VERSION ""

NS_ :

BS_:

BU_: CHUD_LS VKM_LS RCRM_LS MSM_RR_LS MSM_LR_LS CGM_LS BSM_LS VPM_LS ISRVM_LS DCAC_LS TouchPad_LS RSC_LS LVMPC_LS EOCM2B_K1_LS EOCM2A_K1_LS LCM_LS TIM_B_LS V2V_LS TCP_LS CSM_LS EOCM2B_K2_LS EOCM2A_K2_LS TIM_A_LS LVMNav_LS HFP_LS EDI_LS ARB_LS RSE_LS Dummy_LS VIS2_LS ICS_LS FCM_LS EOCM_F_LS VICM_LS AGC_LS MSM_P_LS OTIM_LS HVSM_R_LS HVSM_F_LS DVB_T_LS SBZA_R_LS PSD_R_LS PSD_L_LS UHP_Low UPA_LS STC_LS SBZA_L_LS PTM_LS ONSTAR_LS APA_LS TestTool_LS PHS_LS PDIM_LS CHM_LS RSA_LS AMP_LS HUD_LS MSM_LS HBSM_LS SCL_LS ECC_LS RadioHead_LS PEPS_LS IPC_LS AOS_LS SDM_LS TIM_LS BCM_LS

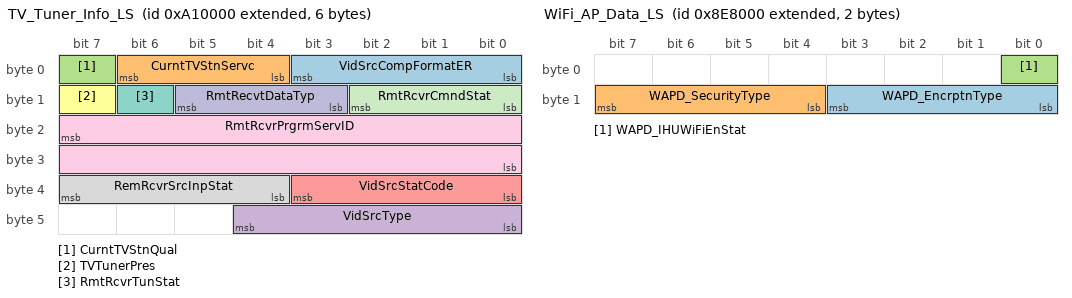
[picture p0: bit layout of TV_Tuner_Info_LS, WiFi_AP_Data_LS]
BO_ 2158034944 TV_Tuner_Info_LS: 6 DVB_T_LS
 SG_ VidSrcCompFormatER : 3|4@0+ (1,0) [0|15] ""  CGM_LS,RadioHead_LS
 SG_ CurntTVStnServc : 6|3@0+ (1,0) [0|7] ""  CGM_LS,RadioHead_LS
 SG_ CurntTVStnQual : 7|1@0+ (1,0) [0|1] ""  CGM_LS,RadioHead_LS
 SG_ VidSrcType : 44|5@0+ (1,0) [0|31] ""  CGM_LS,RadioHead_LS
 SG_ VidSrcStatCode : 35|4@0+ (1,0) [0|15] ""  CGM_LS,RadioHead_LS
 SG_ TVTunerPres : 15|1@0+ (1,0) [0|1] ""  CGM_LS,RadioHead_LS
 SG_ RmtRcvrTunStat : 14|1@0+ (1,0) [0|1] ""  CGM_LS,RadioHead_LS
 SG_ RemRcvrSrcInpStat : 39|4@0+ (1,0) [0|15] ""  CGM_LS,RadioHead_LS
 SG_ RmtRcvrPrgrmServID : 23|16@0+ (1,0) [0|65535] ""  CGM_LS,RadioHead_LS
 SG_ RmtRecvtDataTyp : 13|3@0+ (1,0) [0|7] ""  CGM_LS,RadioHead_LS
 SG_ RmtRcvrCmndStat : 10|3@0+ (1,0) [0|7] ""  CGM_LS,RadioHead_LS

BO_ 2158018560 TV_Station_Name_LS: 8 DVB_T_LS
 SG_ TVStatNmeChar1_8 : 7|64@0+ (1,0) [0|0] ""  CGM_LS,RadioHead_LS

BO_ 2156838912 WiFi_Station_LS: 7 RadioHead_LS
 SG_ WSR_WiFiStnMACAddr : 15|48@0+ (1,0) [0|281474976710655] ""  CGM_LS,ONSTAR_LS
 SG_ WSR_WiFiAssnStat : 3|4@0+ (1,0) [0|15] ""  CGM_LS,ONSTAR_LS

BO_ 2156822528 WiFi_AP_Data_LS: 2 ONSTAR_LS
 SG_ WAPD_EncrptnType : 11|4@0+ (1,0) [0|15] ""  CGM_LS,RadioHead_LS
 SG_ WAPD_SecurityType : 15|4@0+ (1,0) [0|15] ""  CGM_LS,RadioHead_LS
 SG_ WAPD_IHUWiFiEnStat : 0|1@0+ (1,0) [0|1] ""  CGM_LS,RadioHead_LS

BO_ 2151948288 Driver_Drow_Det_Cst_Rqst_LS: 1 RadioHead_LS
 SG_ RunBrdOpMdCstStReq : 7|3@0+ (1,0) [0|7] ""  ARB_LS
 SG_ DrvDrowDetCstStRq : 2|3@0+ (1,0) [0|7] ""  VIS2_LS,FCM_LS

BO_ 2158002176 XM_Radio_Service_LS: 1 RadioHead_LS
 SG_ SrvcPrvdr : 5|3@0+ (1,0) [0|7] ""  CGM_LS,ONSTAR_LS
 SG_ CurntStnServc : 2|3@0+ (1,0) [0|7] ""  CGM_LS,ONSTAR_LS

BO_ 2149728256 Charging_Sys_Trans_Shift_Lock_LS: 5 VICM_LS
 SG_ PrtyChrgStPnt : 38|7@0+ (1,0) [0|127] ""  BCM_LS,CGM_LS,IPC_LS,CSM_LS,RadioHead_LS
 SG_ PrtyChrgActIO : 3|1@0+ (1,0) [0|1] ""  BCM_LS,CSM_LS,CGM_LS,IPC_LS
 SG_ PrtyChrgAct : 4|1@0+ (1,0) [0|1] ""  BCM_LS,CGM_LS,CSM_LS,RadioHead_LS
 SG_ EngAstHtPlgInCsStAvl : 31|1@0+ (1,0) [0|1] ""  CGM_LS,CSM_LS,RadioHead_LS
 SG_ EngAstHtPlgInCsCrStVl : 30|3@0+ (1,0) [0|7] ""  CGM_LS,CSM_LS,RadioHead_LS
 SG_ EngAstHtCsStAvl : 27|1@0+ (1,0) [0|1] ""  CGM_LS,CSM_LS,RadioHead_LS
 SG_ EngAstHtCsCrStVal : 26|3@0+ (1,0) [0|7] ""  ECC_LS,CGM_LS,CSM_LS,RadioHead_LS
 SG_ HghVltgPropState : 7|3@0+ (1,0) [0|7] ""  CSM_LS,CGM_LS,RadioHead_LS,IPC_LS
 SG_ HVChrgPwrLvl : 22|3@0+ (1,0) [0|7] ""  BCM_LS,CGM_LS,CSM_LS,RadioHead_LS,IPC_LS
 SG_ ChrgPrtDrStat : 2|2@0+ (1,0) [0|3] ""  TCP_LS,CGM_LS,ONSTAR_LS,IPC_LS
 SG_ ChgCdTfAlCzStAvbl : 11|1@0+ (1,0) [0|1] ""  CGM_LS,CSM_LS,RadioHead_LS
 SG_ ChgCdTfAlCzCrStVal : 10|3@0+ (1,0) [0|7] ""  CGM_LS,CSM_LS,RadioHead_LS
 SG_ ChrgSysTrnsShftLckRq : 0|1@0+ (1,0) [0|1] ""  CSM_LS,CGM_LS,RadioHead_LS,BCM_LS
 SG_ ChgPwLsAlCzStAvbl : 15|1@0+ (1,0) [0|1] ""  CGM_LS,CSM_LS,RadioHead_LS
 SG_ ChgPwLsAlCzCrStVal : 14|3@0+ (1,0) [0|7] ""  CGM_LS,CSM_LS,RadioHead_LS
 SG_ ChgSysAudInCsStAvl : 19|1@0+ (1,0) [0|1] ""  CGM_LS,CSM_LS,RadioHead_LS
 SG_ ChgSyAudInCsCrStVa : 18|3@0+ (1,0) [0|7] ""  CGM_LS,CSM_LS,RadioHead_LS

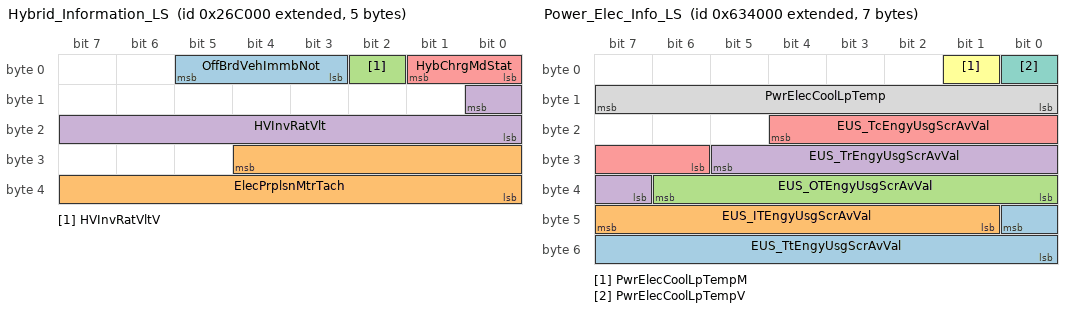
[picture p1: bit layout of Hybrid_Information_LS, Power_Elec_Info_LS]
BO_ 2150023168 Hybrid_Information_LS: 5 VICM_LS
 SG_ OffBrdVehImmbNot : 5|3@0+ (1,0) [0|7] ""  CGM_LS,TCP_LS,ONSTAR_LS
 SG_ ElecPrplsnMtrTach : 28|13@0+ (1,0) [0|8191] "rpm"  CSM_LS,RadioHead_LS,CGM_LS,IPC_LS
 SG_ HVInvRatVltV : 2|1@0+ (1,0) [0|1] ""  CSM_LS,ECC_LS,CGM_LS,RadioHead_LS
 SG_ HVInvRatVlt : 8|9@0+ (1,0) [0|511] "volts"  CSM_LS,ECC_LS,CGM_LS,RadioHead_LS
 SG_ HybChrgMdStat : 1|2@0+ (1,0) [0|3] ""  CSM_LS,ECC_LS,CGM_LS,RadioHead_LS,IPC_LS

BO_ 2153988096 Power_Elec_Info_LS: 7 VICM_LS
 SG_ EUS_TtEngyUsgScrAvVal : 40|9@0- (0.1,0) [-20|20] ""  CGM_LS,CSM_LS,RadioHead_LS
 SG_ EUS_ITEngyUsgScrAvVal : 47|7@0- (0.1,0) [-5|5] ""  CGM_LS,CSM_LS,RadioHead_LS
 SG_ EUS_OTEngyUsgScrAvVal : 38|7@0- (0.1,0) [-5|5] ""  CGM_LS,CSM_LS,RadioHead_LS
 SG_ EUS_TrEngyUsgScrAvVal : 29|7@0- (0.1,0) [-5|5] ""  CGM_LS,CSM_LS,RadioHead_LS
 SG_ EUS_TcEngyUsgScrAvVal : 20|7@0- (0.1,0) [-5|5] ""  CGM_LS,CSM_LS,RadioHead_LS
 SG_ PwrElecCoolLpTempM : 1|1@0+ (1,0) [0|1] ""  CGM_LS,ECC_LS
 SG_ PwrElecCoolLpTempV : 0|1@0+ (1,0) [0|1] ""  CGM_LS,ECC_LS
 SG_ PwrElecCoolLpTemp : 15|8@0+ (1,-40) [-40|215] "deg C"  CGM_LS,ECC_LS

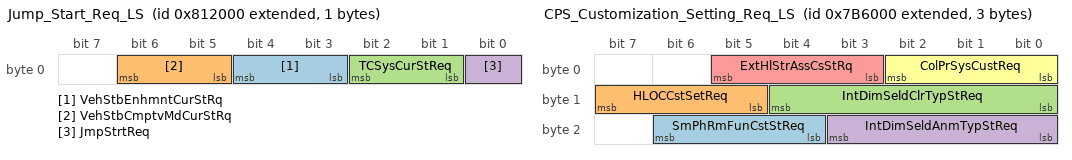
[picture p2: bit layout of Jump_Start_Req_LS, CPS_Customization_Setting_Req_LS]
BO_ 2155945984 Jump_Start_Req_LS: 1 IPC_LS
 SG_ VehStbEnhmntCurStRq : 4|2@0+ (1,0) [0|3] ""  BCM_LS
 SG_ VehStbCmptvMdCurStRq : 6|2@0+ (1,0) [0|3] ""  BCM_LS
 SG_ TCSysCurStReq : 2|2@0+ (1,0) [0|3] ""  BCM_LS
 SG_ JmpStrtReq : 0|1@0+ (1,0) [0|1] ""  BCM_LS

BO_ 1516 UUDT_Resp_From_VICM_LS: 8 VICM_LS
 SG_ DgnInf_LS5EC : 7|64@0+ (1,0) [0|1.84467440737096E+019] ""  CSM_LS,CGM_LS,TCP_LS,ONSTAR_LS,TestTool_LS

BO_ 2155585536 MSB_Customization_Setting_Req_LS: 1 RadioHead_LS
 SG_ StBltTgtCSRq : 2|3@0+ (1,0) [0|7] ""  BCM_LS

BO_ 2155569152 CPS_Customization_Setting_Req_LS: 3 RadioHead_LS
 SG_ SmPhRmFunCstStReq : 22|3@0+ (1,0) [0|7] ""  BCM_LS
 SG_ HLOCCstSetReq : 15|3@0+ (1,0) [0|7] ""  LCM_LS,PTM_LS
 SG_ IntDimSeldClrTypStReq : 12|5@0+ (1,0) [0|31] ""  BCM_LS
 SG_ IntDimSeldAnmTypStReq : 19|4@0+ (1,0) [0|15] ""  BCM_LS
 SG_ ExtHlStrAssCsStRq : 5|3@0+ (1,0) [0|7] ""  BCM_LS
 SG_ ColPrSysCustReq : 2|3@0+ (1,0) [0|7] ""  BCM_LS

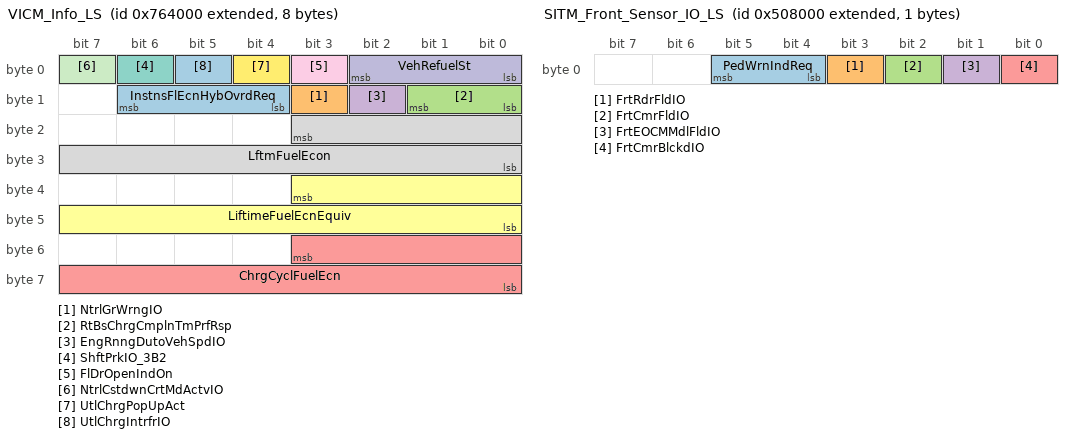
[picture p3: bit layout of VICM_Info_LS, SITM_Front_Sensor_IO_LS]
BO_ 2155233280 VICM_Info_LS: 8 VICM_LS
 SG_ InstnsFlEcnHybOvrdReq : 14|3@0+ (1,0) [0|7] ""  CGM_LS,IPC_LS
 SG_ NtrlGrWrngIO : 11|1@0+ (1,0) [0|1] ""  CGM_LS,IPC_LS
 SG_ RtBsChrgCmplnTmPrfRsp : 9|2@0+ (1,0) [0|3] ""  CGM_LS,CSM_LS,RadioHead_LS
 SG_ EngRnngDutoVehSpdIO : 10|1@0+ (1,0) [0|1] ""  IPC_LS,CGM_LS
 SG_ ChrgCyclFuelEcn : 51|12@0+ (0.1,0) [0|409.5] "km/l"  CGM_LS,CSM_LS,RadioHead_LS
 SG_ LiftimeFuelEcnEquiv : 35|12@0+ (0.1,0) [0|409.5] "km/l"  CGM_LS,CSM_LS,RadioHead_LS
 SG_ ShftPrkIO_3B2 : 6|1@0+ (1,0) [0|1] ""  CGM_LS,IPC_LS
 SG_ LftmFuelEcon : 19|12@0+ (0.1,0) [0|409.5] "kilometers/liter"  CGM_LS,CSM_LS,RadioHead_LS
 SG_ FlDrOpenIndOn : 3|1@0+ (1,0) [0|1] ""  CSM_LS,CGM_LS,RadioHead_LS,IPC_LS
 SG_ VehRefuelSt : 2|3@0+ (1,0) [0|7] ""  CSM_LS,CGM_LS,RadioHead_LS,IPC_LS
 SG_ NtrlCstdwnCrtMdActvIO : 7|1@0+ (1,0) [0|1] ""  CGM_LS,IPC_LS
 SG_ UtlChrgPopUpAct : 4|1@0+ (1,0) [0|1] ""  CGM_LS,CSM_LS,RadioHead_LS
 SG_ UtlChrgIntrfrIO : 5|1@0+ (1,0) [0|1] ""  CGM_LS,CSM_LS,RadioHead_LS,IPC_LS

BO_ 2152759296 SITM_Front_Sensor_IO_LS: 1 EOCM_F_LS
 SG_ PedWrnIndReq : 5|2@0+ (1,0) [0|3] ""  CSM_LS,RadioHead_LS,CGM_LS,IPC_LS
 SG_ FrtRdrFldIO : 3|1@0+ (1,0) [0|1] ""  CSM_LS,CGM_LS,RadioHead_LS,IPC_LS
 SG_ FrtCmrFldIO : 2|1@0+ (1,0) [0|1] ""  CSM_LS,CGM_LS,RadioHead_LS,IPC_LS
 SG_ FrtEOCMMdlFldIO : 1|1@0+ (1,0) [0|1] ""  CSM_LS,CGM_LS,RadioHead_LS,IPC_LS
 SG_ FrtCmrBlckdIO : 0|1@0+ (1,0) [0|1] ""  CSM_LS,CGM_LS,RadioHead_LS,IPC_LS

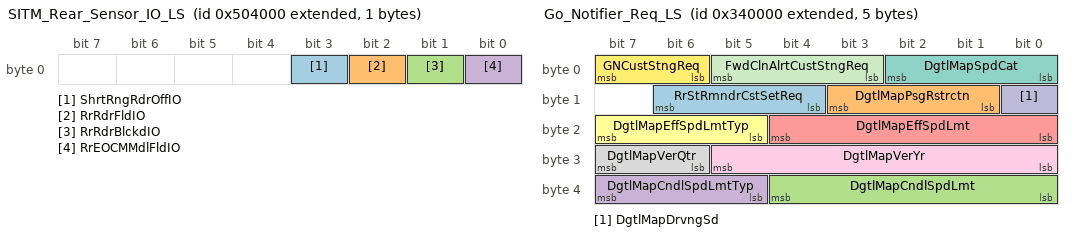
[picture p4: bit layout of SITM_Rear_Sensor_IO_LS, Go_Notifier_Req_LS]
BO_ 2152742912 SITM_Rear_Sensor_IO_LS: 1 EOCM_F_LS
 SG_ ShrtRngRdrOffIO : 3|1@0+ (1,0) [0|1] ""  CSM_LS,CGM_LS,RadioHead_LS,IPC_LS
 SG_ RrRdrFldIO : 2|1@0+ (1,0) [0|1] ""  CSM_LS,CGM_LS,RadioHead_LS,IPC_LS
 SG_ RrRdrBlckdIO : 1|1@0+ (1,0) [0|1] ""  CSM_LS,CGM_LS,RadioHead_LS,IPC_LS
 SG_ RrEOCMMdlFldIO : 0|1@0+ (1,0) [0|1] ""  CSM_LS,CGM_LS,RadioHead_LS,IPC_LS

BO_ 2150891520 Go_Notifier_Req_LS: 5 RadioHead_LS
 SG_ RrStRmndrCstSetReq : 14|3@0+ (1,0) [0|7] ""  BCM_LS
 SG_ DgtlMapPsgRstrctn : 11|3@0+ (1,0) [0|7] ""  VIS2_LS,FCM_LS
 SG_ DgtlMapCndlSpdLmt : 36|5@0+ (1,0) [0|31] ""  VIS2_LS,FCM_LS
 SG_ DgtlMapCndlSpdLmtTyp : 39|3@0+ (1,0) [0|7] ""  VIS2_LS,FCM_LS
 SG_ DgtlMapEffSpdLmt : 20|5@0+ (1,0) [0|31] ""  VIS2_LS,FCM_LS
 SG_ DgtlMapEffSpdLmtTyp : 23|3@0+ (1,0) [0|7] ""  VIS2_LS,FCM_LS
 SG_ DgtlMapSpdCat : 2|3@0+ (1,0) [0|7] ""  VIS2_LS,FCM_LS
 SG_ DgtlMapVerQtr : 31|2@0+ (1,0) [0|3] ""  VIS2_LS,FCM_LS
 SG_ DgtlMapVerYr : 29|6@0+ (1,0) [0|63] ""  VIS2_LS,FCM_LS
 SG_ DgtlMapDrvngSd : 8|1@0+ (1,0) [0|1] ""  VIS2_LS,FCM_LS
 SG_ FwdClnAlrtCustStngReq : 5|3@0+ (1,0) [0|7] ""  FCM_LS,BCM_LS
 SG_ GNCustStngReq : 7|2@0+ (1,0) [0|3] ""  BCM_LS

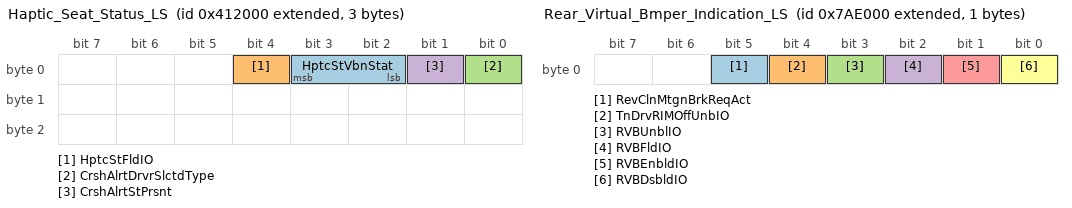
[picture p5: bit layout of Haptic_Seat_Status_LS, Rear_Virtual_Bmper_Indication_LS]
BO_ 2151751680 Haptic_Seat_Status_LS: 3 MSM_LS
 SG_ HptcStVbnStat : 3|2@0+ (1,0) [0|3] ""  V2V_LS,EOCM2A_K2_LS,EOCM2B_K2_LS,VPM_LS,CGM_LS,SBZA_R_LS,SBZA_L_LS,UPA_LS,APA_LS,VIS2_LS,FCM_LS,EOCM_F_LS,BCM_LS
 SG_ HptcStFldIO : 4|1@0+ (1,0) [0|1] ""  VPM_LS,EOCM2A_K2_LS,EOCM2B_K2_LS,V2V_LS,CGM_LS,VIS2_LS,IPC_LS,FCM_LS
 SG_ CrshAlrtDrvrSlctdType : 0|1@0+ (1,0) [0|1] ""  EOCM2A_K2_LS,EOCM2B_K2_LS,V2V_LS,VPM_LS,CGM_LS,VIS2_LS,UPA_LS,APA_LS,FCM_LS,SBZA_R_LS,SBZA_L_LS,BCM_LS,EOCM_F_LS
 SG_ CrshAlrtStPrsnt : 1|1@0+ (1,0) [0|1] ""  VPM_LS,EOCM2A_K2_LS,EOCM2B_K2_LS,V2V_LS,CGM_LS,VIS2_LS,FCM_LS,UPA_LS,APA_LS,BCM_LS,SBZA_R_LS,SBZA_L_LS,EOCM_F_LS

BO_ 2155536384 Rear_Virtual_Bmper_Indication_LS: 1 EOCM_F_LS
 SG_ RevClnMtgnBrkReqAct : 5|1@0+ (1,0) [0|1] ""  CGM_LS,BCM_LS
 SG_ TnDrvRIMOffUnbIO : 4|1@0+ (1,0) [0|1] ""  CGM_LS,IPC_LS
 SG_ RVBUnblIO : 3|1@0+ (1,0) [0|1] ""  CGM_LS,IPC_LS
 SG_ RVBFldIO : 2|1@0+ (1,0) [0|1] ""  CGM_LS,IPC_LS
 SG_ RVBEnbldIO : 1|1@0+ (1,0) [0|1] ""  CGM_LS,IPC_LS
 SG_ RVBDsbldIO : 0|1@0+ (1,0) [0|1] ""  CGM_LS,SBZA_R_LS,SBZA_L_LS,IPC_LS

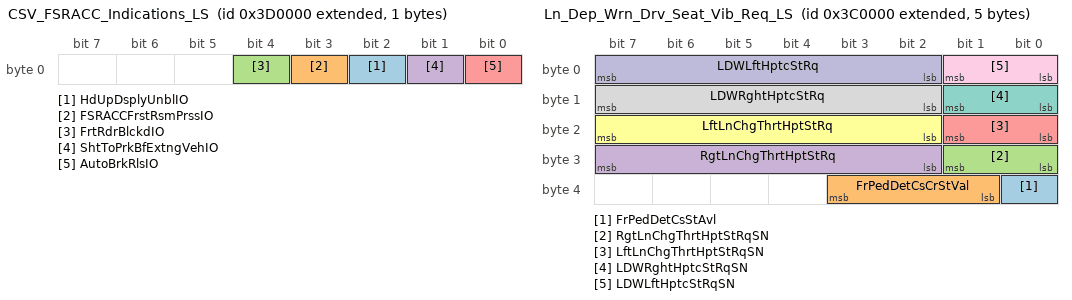
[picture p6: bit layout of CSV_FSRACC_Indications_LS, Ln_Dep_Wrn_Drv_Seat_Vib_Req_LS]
BO_ 2151481344 CSV_FSRACC_Indications_LS: 1 EOCM_F_LS
 SG_ HdUpDsplyUnblIO : 2|1@0+ (1,0) [0|1] ""  CGM_LS,IPC_LS
 SG_ FSRACCFrstRsmPrssIO : 3|1@0+ (1,0) [0|1] ""  CGM_LS,IPC_LS
 SG_ FrtRdrBlckdIO : 4|1@0+ (1,0) [0|1] ""  CSM_LS,CGM_LS,RadioHead_LS,IPC_LS
 SG_ ShtToPrkBfExtngVehIO : 1|1@0+ (1,0) [0|1] ""  CGM_LS,IPC_LS
 SG_ AutoBrkRlsIO : 0|1@0+ (1,0) [0|1] ""  CGM_LS,IPC_LS

BO_ 2151432192 ACC_Drv_Seat_Vib_Req_IO_LS: 1 BCM_LS
 SG_ ACCHptcStVbnRqSeqN : 1|2@0+ (1,0) [0|3] ""  MSM_P_LS,MSM_LS
 SG_ ACCHptcStVbnReq : 7|6@0+ (1,0) [0|63] ""  MSM_P_LS,MSM_LS

BO_ 2151415808 Ln_Dep_Wrn_Drv_Seat_Vib_Req_LS: 5 EOCM_F_LS
 SG_ FrPedDetCsStAvl : 32|1@0+ (1,0) [0|1] ""  CGM_LS,CSM_LS,RadioHead_LS,MSM_P_LS,MSM_LS
 SG_ FrPedDetCsCrStVal : 35|3@0+ (1,0) [0|7] ""  CGM_LS,CSM_LS,RadioHead_LS,MSM_P_LS,MSM_LS
 SG_ RgtLnChgThrtHptStRqSN : 25|2@0+ (1,0) [0|3] ""  CGM_LS,MSM_P_LS,MSM_LS
 SG_ RgtLnChgThrtHptStRq : 31|6@0+ (1,0) [0|63] "Pulse"  CGM_LS,MSM_P_LS,MSM_LS
 SG_ LftLnChgThrtHptStRqSN : 17|2@0+ (1,0) [0|3] ""  CGM_LS,MSM_P_LS,MSM_LS
 SG_ LftLnChgThrtHptStRq : 23|6@0+ (1,0) [0|63] "Pulse"  CGM_LS,MSM_P_LS,MSM_LS
 SG_ LDWRghtHptcStRqSN : 9|2@0+ (1,0) [0|3] ""  CGM_LS,MSM_P_LS,MSM_LS
 SG_ LDWRghtHptcStRq : 15|6@0+ (1,0) [0|63] ""  CGM_LS,BCM_LS,MSM_P_LS,MSM_LS
 SG_ LDWLftHptcStRqSN : 1|2@0+ (1,0) [0|3] ""  CGM_LS,MSM_P_LS,MSM_LS
 SG_ LDWLftHptcStRq : 7|6@0+ (1,0) [0|63] ""  CGM_LS,BCM_LS,MSM_P_LS,MSM_LS

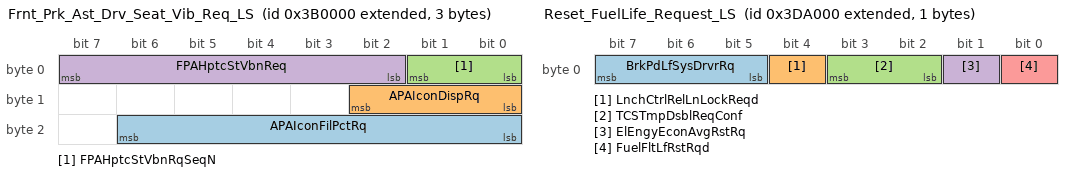
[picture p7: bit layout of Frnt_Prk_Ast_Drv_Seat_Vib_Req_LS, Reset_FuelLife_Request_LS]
BO_ 2151350272 Frnt_Prk_Ast_Drv_Seat_Vib_Req_LS: 3 APA_LS
 SG_ APAIconFilPctRq : 22|7@0+ (1,0) [0|127] ""  CGM_LS,VPM_LS,CSM_LS,RadioHead_LS
 SG_ APAIconDispRq : 10|3@0+ (1,0) [0|7] ""  CGM_LS,VPM_LS,CSM_LS,RadioHead_LS
 SG_ FPAHptcStVbnRqSeqN : 1|2@0+ (1,0) [0|3] ""  CGM_LS,MSM_P_LS,MSM_LS
 SG_ FPAHptcStVbnReq : 7|6@0+ (1,0) [0|63] ""  CGM_LS,MSM_P_LS,MSM_LS

BO_ 2151333888 Rear_Prk_Ast_Drv_Seat_Vib_Req_LS: 1 APA_LS
 SG_ RPAHptcStVbRqSeqN : 1|2@0+ (1,0) [0|3] ""  MSM_P_LS,MSM_LS
 SG_ RPAHptcStVbnReq : 7|6@0+ (1,0) [0|63] ""  MSM_P_LS,MSM_LS

BO_ 2151522304 Reset_FuelLife_Request_LS: 1 IPC_LS
 SG_ BrkPdLfSysDrvrRq : 7|3@0+ (1,0) [0|7] ""  BCM_LS
 SG_ LnchCtrlRelLnLockReqd : 4|1@0+ (1,0) [0|1] ""  BCM_LS
 SG_ TCSTmpDsblReqConf : 3|2@0+ (1,0) [0|3] ""  BCM_LS
 SG_ ElEngyEconAvgRstRq : 1|1@0+ (1,0) [0|1] ""  BSM_LS,VICM_LS
 SG_ FuelFltLfRstRqd : 0|1@0+ (1,0) [0|1] ""  BCM_LS

BO_ 2150629376 CV_System_Failure_LS: 1 Dummy_LS
 SG_ CVSysFlrIO : 0|1@0+ (1,0) [0|1] ""  CSM_LS,CGM_LS,IPC_LS

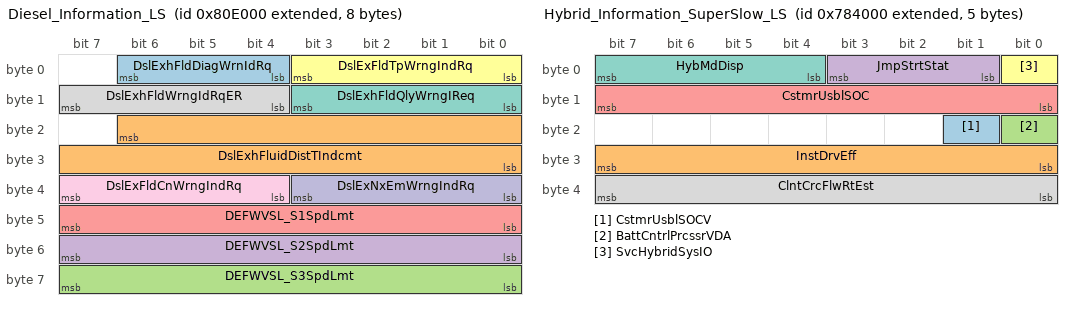
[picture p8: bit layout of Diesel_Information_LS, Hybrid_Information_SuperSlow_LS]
BO_ 2155929600 Diesel_Information_LS: 8 BCM_LS
 SG_ DslExhFldDiagWrnIdRq : 6|3@0+ (1,0) [0|7] ""  CSM_LS,CGM_LS,IPC_LS
 SG_ DslExhFluidDistTIndcmt : 22|15@0+ (2,0) [0|65534] "km"  CGM_LS,IPC_LS
 SG_ DEFWVSL_S3SpdLmt : 63|8@0+ (1,0) [0|255] "km / h"  CGM_LS,IPC_LS
 SG_ DEFWVSL_S2SpdLmt : 55|8@0+ (1,0) [0|255] "km / h"  CGM_LS,IPC_LS
 SG_ DEFWVSL_S1SpdLmt : 47|8@0+ (1,0) [0|255] "km / h"  CGM_LS,IPC_LS
 SG_ DslExFldTpWrngIndRq : 3|4@0+ (1,0) [0|15] ""  CGM_LS,IPC_LS
 SG_ DslExhFldQlyWrngIReq : 11|4@0+ (1,0) [0|15] ""  CGM_LS,IPC_LS
 SG_ DslExhFldWrngIdRqER : 15|4@0+ (1,0) [0|15] ""  CGM_LS,IPC_LS
 SG_ DslExFldCnWrngIndRq : 39|4@0+ (1,0) [0|15] ""  CGM_LS,IPC_LS
 SG_ DslExNxEmWrngIndRq : 35|4@0+ (1,0) [0|15] ""  CGM_LS,IPC_LS

BO_ 2154741760 RSA_Status_LS: 1 RSA_LS
 SG_ RSAPrsnt : 0|1@0+ (1,0) [0|1] ""  CGM_LS,CSM_LS,RadioHead_LS

BO_ 2154807296 Lighting_Customization_Info_3_LS: 4 BCM_LS
 SG_ ESCMHiEleclLdReqAct : 12|1@0+ (1,0) [0|1] ""  ECC_LS,CGM_LS
 SG_ TnDrvStBltShftIntrlkCsStAvl : 19|1@0+ (1,0) [0|1] ""  CSM_LS,CGM_LS
 SG_ TnDrvStBltShftIntrlkCrStVal : 22|3@0+ (1,0) [0|7] ""  CSM_LS,CGM_LS
 SG_ StBltShftIntrlkCsStAvl : 18|1@0+ (1,0) [0|1] ""  CSM_LS,CGM_LS
 SG_ StBltShftIntrlkCsCrStVal : 15|3@0+ (1,0) [0|7] ""  CSM_LS,CGM_LS
 SG_ EASSI_UnsdRsrvd2 : 24|1@0+ (1,0) [0|1] ""  CGM_LS,ECC_LS
 SG_ EASSI_StlDetd : 26|1@0+ (1,0) [0|1] ""  CGM_LS,ECC_LS
 SG_ EASSI_TrqDetd : 27|1@0+ (1,0) [0|1] ""  CGM_LS,ECC_LS
 SG_ EASSI_FuelReqOn : 28|1@0+ (1,0) [0|1] ""  CGM_LS,ECC_LS
 SG_ EASSI_StrtTyp : 31|3@0+ (1,0) [0|7] ""  CGM_LS,ECC_LS
 SG_ EASSI_StrtStpSt : 17|2@0+ (1,0) [0|3] ""  CGM_LS,ECC_LS
 SG_ EASSI_TorqDetdIndet : 25|1@0+ (1,0) [0|1] ""  CGM_LS,ECC_LS
 SG_ EngAutoStpNotProb : 11|1@0+ (1,0) [0|1] ""  CGM_LS,ECC_LS
 SG_ AFLMnu3CstStAvl : 10|1@0+ (1,0) [0|1] ""  CGM_LS,CSM_LS,RadioHead_LS
 SG_ AFLMnu2CstStAvl : 9|1@0+ (1,0) [0|1] ""  CGM_LS,CSM_LS,RadioHead_LS
 SG_ AFLGPSMnu2CstStAvl : 8|1@0+ (1,0) [0|1] ""  CGM_LS,CSM_LS,RadioHead_LS
 SG_ AFLGPSCstStAvl : 6|1@0+ (1,0) [0|1] ""  CGM_LS,CSM_LS,RadioHead_LS
 SG_ AFLGPSCstCrStVal : 2|3@0+ (1,0) [0|7] ""  CGM_LS,CSM_LS,RadioHead_LS
 SG_ AFLCstStAvl : 7|1@0+ (1,0) [0|1] ""  CGM_LS,CSM_LS,RadioHead_LS
 SG_ AFLCstCrStVal : 5|3@0+ (1,0) [0|7] ""  CGM_LS,CSM_LS,RadioHead_LS

BO_ 2151079936 PDIM_Status_LS: 1 PDIM_LS
 SG_ PDIMPrsnt : 0|1@0+ (1,0) [0|1] ""  CGM_LS,CSM_LS,RadioHead_LS

BO_ 2155364352 Hybrid_Information_SuperSlow_LS: 5 BCM_LS
 SG_ CstmrUsblSOCV : 17|1@0+ (1,0) [0|1] ""  BCM_LS,CGM_LS,IPC_LS,CSM_LS,RadioHead_LS
 SG_ InstDrvEff : 31|8@0- (0.78125,0) [-100|99.21875] "%"  CGM_LS,CSM_LS,RadioHead_LS,IPC_LS
 SG_ BattCntrlPrcssrVDA : 16|1@0+ (1,0) [0|1] ""  CSM_LS,CGM_LS,RadioHead_LS,IPC_LS
 SG_ JmpStrtStat : 3|3@0+ (1,0) [0|7] ""  CSM_LS,CGM_LS,RadioHead_LS,IPC_LS
 SG_ CstmrUsblSOC : 15|8@0+ (0.39216,0) [0|100.0008] "%"  BCM_LS,CGM_LS,CSM_LS,RadioHead_LS,IPC_LS
 SG_ SvcHybridSysIO : 0|1@0+ (1,0) [0|1] ""  CSM_LS,CGM_LS,RadioHead_LS,IPC_LS
 SG_ HybMdDisp : 7|4@0+ (1,0) [0|15] ""  CGM_LS,CSM_LS,RadioHead_LS,IPC_LS
 SG_ ClntCrcFlwRtEst : 39|8@0+ (0.392157,0) [0|100.000035] "%"  CSM_LS,CGM_LS,RadioHead_LS,ECC_LS

BO_ 2154979328 Front_Seat_Heat_Cool_Req_LS: 1 MSM_LS
 SG_ FrntStVoltBstModReq : 0|1@0+ (1,0) [0|1] ""  CGM_LS,BCM_LS

BO_ 2155282432 RearSeat_HeatVent_Cool_LS: 1 HVSM_R_LS
 SG_ RrStVoltBstModReq : 0|1@0+ (1,0) [0|1] ""  CGM_LS,BCM_LS

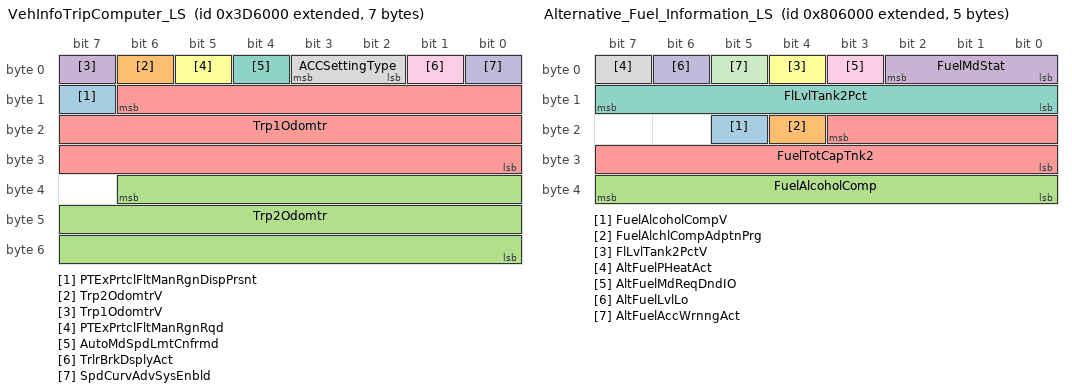
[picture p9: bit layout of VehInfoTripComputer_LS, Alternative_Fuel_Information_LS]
BO_ 2151505920 VehInfoTripComputer_LS: 7 IPC_LS
 SG_ PTExPrtclFltManRgnDispPrsnt : 15|1@0+ (1,0) [0|1] ""  BCM_LS
 SG_ Trp2OdomtrV : 6|1@0+ (1,0) [0|1] ""  RadioHead_LS
 SG_ Trp2Odomtr : 38|23@0+ (0.015625,0) [0|131071.984375] "km"  RadioHead_LS
 SG_ Trp1OdomtrV : 7|1@0+ (1,0) [0|1] ""  RadioHead_LS
 SG_ Trp1Odomtr : 14|23@0+ (0.015625,0) [0|131071.984375] "km"  RadioHead_LS
 SG_ PTExPrtclFltManRgnRqd : 5|1@0+ (1,0) [0|1] ""  BCM_LS
 SG_ AutoMdSpdLmtCnfrmd : 4|1@0+ (1,0) [0|1] ""  BCM_LS
 SG_ ACCSettingType : 3|2@0+ (1,0) [0|3] ""  VIS2_LS,ONSTAR_LS,BCM_LS
 SG_ TrlrBrkDsplyAct : 1|1@0+ (1,0) [0|1] ""  BCM_LS
 SG_ SpdCurvAdvSysEnbld : 0|1@0+ (1,0) [0|1] ""  ONSTAR_LS,CHUD_LS,HUD_LS

BO_ 2155896832 Alternative_Fuel_Information_LS: 5 BCM_LS
 SG_ FuelAlcoholCompV : 21|1@0+ (1,0) [0|1] ""  CGM_LS,RadioHead_LS,IPC_LS
 SG_ FuelAlchlCompAdptnPrg : 20|1@0+ (1,0) [0|1] ""  CGM_LS,RadioHead_LS,IPC_LS
 SG_ FuelAlcoholComp : 39|8@0+ (0.392157,0) [0|100.000035] "%"  CGM_LS,RadioHead_LS,IPC_LS
 SG_ FuelMdStat : 2|3@0+ (1,0) [0|7] ""  CGM_LS,RadioHead_LS,IPC_LS
 SG_ FuelTotCapTnk2 : 19|12@0+ (0.125,0) [0|511.875] "liters"  CGM_LS,RadioHead_LS,IPC_LS
 SG_ FlLvlTank2PctV : 4|1@0+ (1,0) [0|1] ""  CGM_LS,RadioHead_LS,IPC_LS
 SG_ FlLvlTank2Pct : 15|8@0+ (0.392157,0) [0|100.000035] "%"  CGM_LS,RadioHead_LS,IPC_LS
 SG_ AltFuelPHeatAct : 7|1@0+ (1,0) [0|1] ""  CGM_LS,RadioHead_LS,IPC_LS
 SG_ AltFuelMdReqDndIO : 3|1@0+ (1,0) [0|1] ""  CGM_LS,RadioHead_LS,IPC_LS
 SG_ AltFuelLvlLo : 6|1@0+ (1,0) [0|1] ""  CGM_LS,RadioHead_LS,IPC_LS
 SG_ AltFuelAccWrnngAct : 5|1@0+ (1,0) [0|1] ""  CGM_LS,RadioHead_LS,IPC_LS

BO_ 2155552768 Exterior_Lock_Switch_Req_LS: 1 PEPS_LS
 SG_ PsvEntCmftWndRq : 1|2@0+ (1,0) [0|3] ""  CGM_LS,BCM_LS

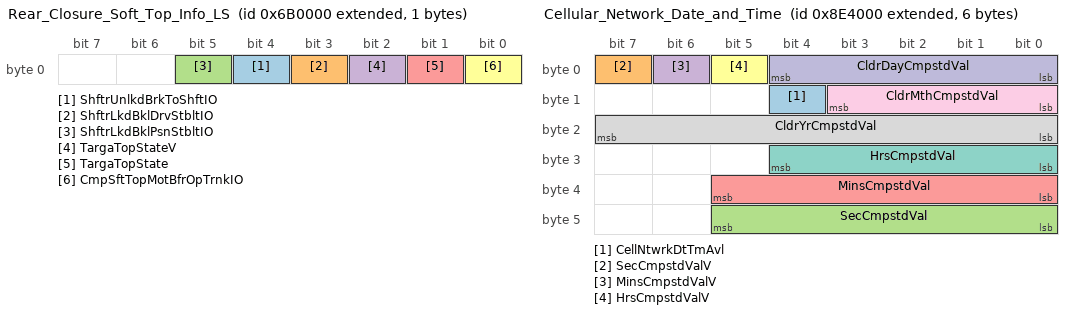
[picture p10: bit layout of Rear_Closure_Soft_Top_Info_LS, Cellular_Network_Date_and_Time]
BO_ 2154496000 Rear_Closure_Soft_Top_Info_LS: 1 BCM_LS
 SG_ ShftrUnlkdBrkToShftIO : 4|1@0+ (1,0) [0|1] ""  CGM_LS,IPC_LS
 SG_ ShftrLkdBklDrvStbltIO : 3|1@0+ (1,0) [0|1] ""  CGM_LS,IPC_LS
 SG_ ShftrLkdBklPsnStbltIO : 5|1@0+ (1,0) [0|1] ""  CGM_LS,IPC_LS
 SG_ TargaTopStateV : 2|1@0+ (1,0) [0|1] ""  AMP_LS,CGM_LS,ISRVM_LS,CSM_LS,RadioHead_LS
 SG_ TargaTopState : 1|1@0+ (1,0) [0|1] ""  AMP_LS,CGM_LS,ISRVM_LS,CSM_LS,RadioHead_LS
 SG_ CmpSftTopMotBfrOpTrnkIO : 0|1@0+ (1,0) [0|1] ""  CSM_LS,CGM_LS,IPC_LS

BO_ 2155208704 Power_Conv_Top_Info_LS: 3 STC_LS
 SG_ SftTpPlsDnWrngIndOn : 22|1@0+ (1,0) [0|1] ""  CGM_LS,IPC_LS
 SG_ SftTpPlsDnSrtdIndOn : 21|1@0+ (1,0) [0|1] ""  CGM_LS,IPC_LS
 SG_ VltSwAtvIndOn : 14|1@0+ (1,0) [0|1] ""  CGM_LS,RadioHead_LS,IPC_LS
 SG_ SftTpVltLwIO : 10|1@0+ (1,0) [0|1] ""  CGM_LS,RadioHead_LS,IPC_LS
 SG_ SftTpVehOvSpdIndOn : 9|1@0+ (1,0) [0|1] ""  CGM_LS,RadioHead_LS,IPC_LS
 SG_ SftTpTneuCvrIO : 8|1@0+ (1,0) [0|1] ""  CGM_LS,RadioHead_LS,IPC_LS
 SG_ SftTpTmpLwIO : 7|1@0+ (1,0) [0|1] ""  CGM_LS,RadioHead_LS,IPC_LS
 SG_ SftTpStrIO : 6|1@0+ (1,0) [0|1] ""  CGM_LS,RadioHead_LS,IPC_LS
 SG_ SftTpRmCrgCrrIO : 5|1@0+ (1,0) [0|1] ""  CGM_LS,RadioHead_LS,IPC_LS
 SG_ SftTpMnlLtchIndOn : 3|1@0+ (1,0) [0|1] ""  CGM_LS,RadioHead_LS,IPC_LS
 SG_ SftTpMchnOvhtIO : 4|1@0+ (1,0) [0|1] ""  CGM_LS,RadioHead_LS,IPC_LS
 SG_ SftTpLtcIO : 2|1@0+ (1,0) [0|1] ""  CGM_LS,RadioHead_LS,IPC_LS
 SG_ SftTpFlrIO : 1|1@0+ (1,0) [0|1] ""  CGM_LS,RadioHead_LS,IPC_LS
 SG_ SftTpAbvWrngSpdIndOn : 0|1@0+ (1,0) [0|1] ""  CGM_LS,RadioHead_LS,IPC_LS
 SG_ FldngTpSt : 18|3@0+ (1,0) [0|7] ""  AMP_LS,LCM_LS,CGM_LS,ISRVM_LS,IPC_LS,ECC_LS,RadioHead_LS,BCM_LS
 SG_ ClsTrnkLidIO : 12|1@0+ (1,0) [0|1] ""  V2V_LS,CGM_LS,RadioHead_LS,IPC_LS
 SG_ CkSoftTpIO : 11|1@0+ (1,0) [0|1] ""  CGM_LS,RadioHead_LS,IPC_LS
 SG_ SftTpTrnLmpsRqd : 15|1@0+ (1,0) [0|1] ""  CGM_LS,RadioHead_LS,BCM_LS
 SG_ FldngTpWndCmftRq : 20|2@0+ (1,0) [0|3] ""  CGM_LS,RadioHead_LS,BCM_LS
 SG_ FTUpdWndPsLmtEnbld : 13|1@0+ (1,0) [0|1] ""  CGM_LS,RadioHead_LS,BCM_LS

BO_ 2153390080 Manual_Liftgate_Control_LS: 1 BCM_LS
 SG_ RrClosOpenSwAct_2D1V : 3|1@0+ (1,0) [0|1] ""  CGM_LS,IPC_LS
 SG_ RrClosOpenSwAct_2D1 : 1|1@0+ (1,0) [0|1] ""  VKM_LS,CGM_LS,IPC_LS

BO_ 2155175936 CruiseControlGapSwitch_LS: 1 BCM_LS
 SG_ AdptCrsLKALDWSwAct : 2|1@0+ (1,0) [0|1] ""  CGM_LS,FCM_LS
 SG_ AdptCrsGapSwAct : 1|2@0+ (1,0) [0|3] ""  CGM_LS,FCM_LS

BO_ 2156806144 Cellular_Network_Date_and_Time: 6 ONSTAR_LS
 SG_ CellNtwrkDtTmAvl : 12|1@0+ (1,0) [0|1] ""  CSM_LS,RadioHead_LS
 SG_ SecCmpstdValV : 7|1@0+ (1,0) [0|1] ""  CSM_LS,RadioHead_LS
 SG_ SecCmpstdVal : 45|6@0+ (1,0) [0|63] "secs"  CSM_LS,RadioHead_LS
 SG_ MinsCmpstdValV : 6|1@0+ (1,0) [0|1] ""  CSM_LS,RadioHead_LS
 SG_ MinsCmpstdVal : 37|6@0+ (1,0) [0|63] "min"  CSM_LS,RadioHead_LS
 SG_ HrsCmpstdValV : 5|1@0+ (1,0) [0|1] ""  CSM_LS,RadioHead_LS
 SG_ HrsCmpstdVal : 28|5@0+ (1,0) [0|31] "h"  CSM_LS,RadioHead_LS
 SG_ CldrYrCmpstdVal : 23|8@0+ (1,2000) [2000|2255] "year"  CSM_LS,RadioHead_LS
 SG_ CldrMthCmpstdVal : 11|4@0+ (1,0) [0|15] ""  ECC_LS,CSM_LS,RadioHead_LS
 SG_ CldrDayCmpstdVal : 4|5@0+ (1,0) [0|31] "days"  ECC_LS,CSM_LS,RadioHead_LS

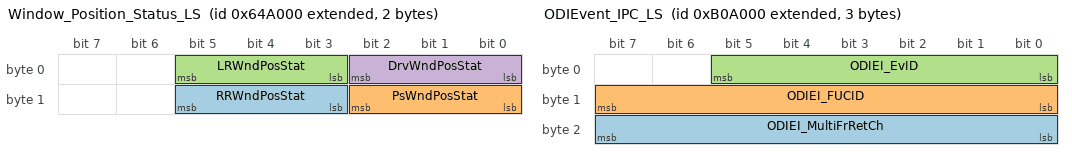
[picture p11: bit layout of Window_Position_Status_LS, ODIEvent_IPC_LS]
BO_ 2154078208 Window_Position_Status_LS: 2 BCM_LS
 SG_ RRWndPosStat : 13|3@0+ (1,0) [0|7] ""  CSM_LS,CGM_LS,RadioHead_LS,LCM_LS,PTM_LS,PSD_R_LS,PSD_L_LS,STC_LS
 SG_ PsWndPosStat : 10|3@0+ (1,0) [0|7] ""  CSM_LS,CGM_LS,RadioHead_LS,LCM_LS,PTM_LS,STC_LS
 SG_ LRWndPosStat : 5|3@0+ (1,0) [0|7] ""  CSM_LS,CGM_LS,RadioHead_LS,LCM_LS,PTM_LS,PSD_R_LS,PSD_L_LS,STC_LS
 SG_ DrvWndPosStat : 2|3@0+ (1,0) [0|7] ""  CSM_LS,CGM_LS,RadioHead_LS,LCM_LS,PTM_LS,STC_LS

BO_ 2159058944 ODIEvent_IPC_LS: 3 IPC_LS
 SG_ ODIEI_MultiFrRetCh : 23|8@0+ (1,0) [0|255] ""  CGM_LS,RadioHead_LS,CHUD_LS,HUD_LS
 SG_ ODIEI_FUCID : 15|8@0+ (1,0) [0|255] ""  CGM_LS,RadioHead_LS,CHUD_LS,HUD_LS
 SG_ ODIEI_EvID : 5|6@0+ (1,0) [0|63] ""  CGM_LS,RadioHead_LS,CHUD_LS,HUD_LS

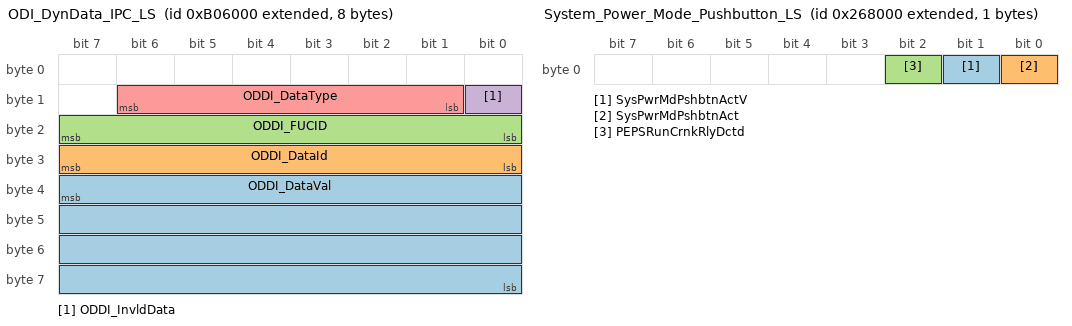
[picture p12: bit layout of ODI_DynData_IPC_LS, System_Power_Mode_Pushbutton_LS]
BO_ 2159042560 ODI_DynData_IPC_LS: 8 IPC_LS
 SG_ ODDI_DataVal : 39|32@0+ (1,0) [0|4294967295] ""  CGM_LS,RadioHead_LS,CHUD_LS,HUD_LS
 SG_ ODDI_DataId : 31|8@0+ (1,0) [0|255] ""  CGM_LS,RadioHead_LS,CHUD_LS,HUD_LS
 SG_ ODDI_FUCID : 23|8@0+ (1,0) [0|255] ""  CGM_LS,RadioHead_LS,CHUD_LS,HUD_LS
 SG_ ODDI_InvldData : 8|1@0+ (1,0) [0|1] ""  CGM_LS,RadioHead_LS,CHUD_LS,HUD_LS
 SG_ ODDI_DataType : 14|6@0+ (1,0) [0|63] ""  CGM_LS,RadioHead_LS,CHUD_LS,HUD_LS

BO_ 2150006784 System_Power_Mode_Pushbutton_LS: 1 PEPS_LS
 SG_ SysPwrMdPshbtnActV : 1|1@0+ (1,0) [0|1] ""  CGM_LS,BCM_LS
 SG_ SysPwrMdPshbtnAct : 0|1@0+ (1,0) [0|1] ""  CGM_LS,VKM_LS,BCM_LS
 SG_ PEPSRunCrnkRlyDctd : 2|1@0+ (1,0) [0|1] ""  CGM_LS,BCM_LS

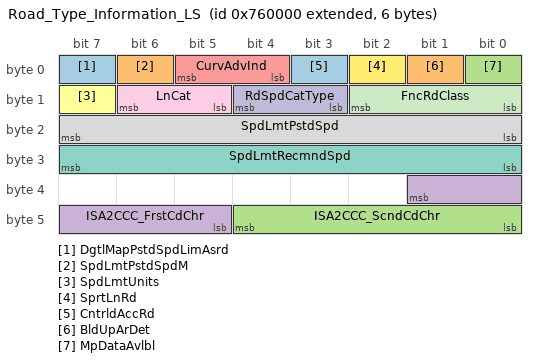
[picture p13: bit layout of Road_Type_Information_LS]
BO_ 2155216896 Road_Type_Information_LS: 6 RadioHead_LS
 SG_ DgtlMapPstdSpdLimAsrd : 7|1@0+ (1,0) [0|1] ""  FCM_LS,VIS2_LS
 SG_ SpdLmtPstdSpdM : 6|1@0+ (1,0) [0|1] ""  VIS2_LS,CHUD_LS,HUD_LS,FCM_LS
 SG_ ISA2CCC_ScndCdChr : 44|5@0+ (1,0) [0|31] ""  VIS2_LS,BCM_LS,FCM_LS,LVMPC_LS
 SG_ ISA2CCC_FrstCdChr : 33|5@0+ (1,0) [0|31] ""  VIS2_LS,BCM_LS,FCM_LS,LVMPC_LS
 SG_ CurvAdvInd : 5|2@0+ (1,0) [0|3] ""  FCM_LS,CHUD_LS,HUD_LS
 SG_ SpdLmtUnits : 15|1@0+ (1,0) [0|1] ""  BCM_LS,VIS2_LS,FCM_LS,CHUD_LS,HUD_LS
 SG_ SpdLmtRecmndSpd : 31|8@0+ (1,0) [0|255] ""  VIS2_LS,FCM_LS,CHUD_LS,HUD_LS
 SG_ SpdLmtPstdSpd : 23|8@0+ (1,0) [0|255] ""  VIS2_LS,FCM_LS,CHUD_LS,HUD_LS
 SG_ LnCat : 14|2@0+ (1,0) [0|3] ""  VIS2_LS,FCM_LS,BCM_LS
 SG_ RdSpdCatType : 12|2@0+ (1,0) [0|3] ""  VIS2_LS,EOCM_F_LS,FCM_LS,BCM_LS
 SG_ FncRdClass : 10|3@0+ (1,0) [0|7] ""  VIS2_LS,EOCM_F_LS,FCM_LS,BCM_LS
 SG_ SprtLnRd : 2|1@0+ (1,0) [0|1] ""  VIS2_LS,FCM_LS,BCM_LS
 SG_ CntrldAccRd : 3|1@0+ (1,0) [0|1] ""  VIS2_LS,FCM_LS,BCM_LS
 SG_ BldUpArDet : 1|1@0+ (1,0) [0|1] ""  VIS2_LS,EOCM_F_LS,FCM_LS,BCM_LS
 SG_ MpDataAvlbl : 0|1@0+ (1,0) [0|1] ""  VIS2_LS,EOCM_F_LS,FCM_LS,BCM_LS

BO_ 2156216320 TTY_Status_LS: 1 OTIM_LS
 SG_ TxtTelephoneDevPr : 0|1@0+ (1,0) [0|1] ""  CGM_LS,TCP_LS,ONSTAR_LS

BO_ 2158813184 ODIIndication_IPC_LS: 8 IPC_LS
 SG_ ODIIIPC_ODIInd56 : 56|1@0+ (1,0) [0|1] ""  CGM_LS,TCP_LS,ONSTAR_LS,CHUD_LS,HUD_LS,RadioHead_LS
 SG_ ODIIIPC_ODIInd55 : 57|1@0+ (1,0) [0|1] ""  CGM_LS,TCP_LS,ONSTAR_LS,CHUD_LS,HUD_LS,RadioHead_LS
 SG_ ODIIIPC_ODIInd54 : 58|1@0+ (1,0) [0|1] ""  CGM_LS,TCP_LS,ONSTAR_LS,CHUD_LS,HUD_LS,RadioHead_LS
 SG_ ODIIIPC_ODIInd53 : 59|1@0+ (1,0) [0|1] ""  CGM_LS,TCP_LS,ONSTAR_LS,CHUD_LS,HUD_LS,RadioHead_LS
 SG_ ODIIIPC_ODIInd52 : 60|1@0+ (1,0) [0|1] ""  CGM_LS,TCP_LS,ONSTAR_LS,CHUD_LS,HUD_LS,RadioHead_LS
 SG_ ODIIIPC_ODIInd51 : 61|1@0+ (1,0) [0|1] ""  CGM_LS,TCP_LS,ONSTAR_LS,CHUD_LS,HUD_LS,RadioHead_LS
 SG_ ODIIIPC_ODIInd50 : 62|1@0+ (1,0) [0|1] ""  CGM_LS,TCP_LS,ONSTAR_LS,CHUD_LS,HUD_LS,RadioHead_LS
 SG_ ODIIIPC_ODIInd49 : 63|1@0+ (1,0) [0|1] ""  CGM_LS,TCP_LS,ONSTAR_LS,CHUD_LS,HUD_LS,RadioHead_LS
 SG_ ODIIIPC_ODIInd48 : 48|1@0+ (1,0) [0|1] ""  CGM_LS,TCP_LS,ONSTAR_LS,CHUD_LS,HUD_LS,RadioHead_LS
 SG_ ODIIIPC_ODIInd47 : 49|1@0+ (1,0) [0|1] ""  CGM_LS,TCP_LS,ONSTAR_LS,CHUD_LS,HUD_LS,RadioHead_LS
 SG_ ODIIIPC_ODIInd46 : 50|1@0+ (1,0) [0|1] ""  CGM_LS,TCP_LS,ONSTAR_LS,CHUD_LS,HUD_LS,RadioHead_LS
 SG_ ODIIIPC_ODIInd45 : 51|1@0+ (1,0) [0|1] ""  CGM_LS,TCP_LS,ONSTAR_LS,CHUD_LS,HUD_LS,RadioHead_LS
 SG_ ODIIIPC_ODIInd44 : 52|1@0+ (1,0) [0|1] ""  CGM_LS,TCP_LS,ONSTAR_LS,CHUD_LS,HUD_LS,RadioHead_LS
 SG_ ODIIIPC_ODIInd43 : 53|1@0+ (1,0) [0|1] ""  CGM_LS,TCP_LS,ONSTAR_LS,CHUD_LS,HUD_LS,RadioHead_LS
 SG_ ODIIIPC_ODIInd42 : 54|1@0+ (1,0) [0|1] ""  CGM_LS,TCP_LS,ONSTAR_LS,CHUD_LS,HUD_LS,RadioHead_LS
 SG_ ODIIIPC_ODIInd41 : 55|1@0+ (1,0) [0|1] ""  CGM_LS,TCP_LS,ONSTAR_LS,CHUD_LS,HUD_LS,RadioHead_LS
 SG_ ODIIIPC_ODIInd40 : 40|1@0+ (1,0) [0|1] ""  CGM_LS,TCP_LS,ONSTAR_LS,CHUD_LS,HUD_LS,RadioHead_LS
 SG_ ODIIIPC_ODIInd39 : 41|1@0+ (1,0) [0|1] ""  CGM_LS,TCP_LS,ONSTAR_LS,CHUD_LS,HUD_LS,RadioHead_LS
 SG_ ODIIIPC_ODIInd38 : 42|1@0+ (1,0) [0|1] ""  CGM_LS,TCP_LS,ONSTAR_LS,CHUD_LS,HUD_LS,RadioHead_LS
 SG_ ODIIIPC_ODIInd9 : 23|1@0+ (1,0) [0|1] ""  CGM_LS,TCP_LS,ONSTAR_LS,CHUD_LS,HUD_LS,RadioHead_LS
 SG_ ODIIIPC_ODIInd8 : 8|1@0+ (1,0) [0|1] ""  CGM_LS,TCP_LS,ONSTAR_LS,CHUD_LS,HUD_LS,RadioHead_LS
 SG_ ODIIIPC_ODIInd7 : 9|1@0+ (1,0) [0|1] ""  CGM_LS,TCP_LS,ONSTAR_LS,CHUD_LS,HUD_LS,RadioHead_LS
 SG_ ODIIIPC_ODIInd6 : 10|1@0+ (1,0) [0|1] ""  CGM_LS,TCP_LS,ONSTAR_LS,CHUD_LS,HUD_LS,RadioHead_LS
 SG_ ODIIIPC_ODIInd5 : 11|1@0+ (1,0) [0|1] ""  CGM_LS,TCP_LS,ONSTAR_LS,CHUD_LS,HUD_LS,RadioHead_LS
 SG_ ODIIIPC_ODIInd4 : 12|1@0+ (1,0) [0|1] ""  CGM_LS,TCP_LS,ONSTAR_LS,CHUD_LS,HUD_LS,RadioHead_LS
 SG_ ODIIIPC_ODIInd3 : 13|1@0+ (1,0) [0|1] ""  CGM_LS,TCP_LS,ONSTAR_LS,CHUD_LS,HUD_LS,RadioHead_LS
 SG_ ODIIIPC_ODIInd37 : 43|1@0+ (1,0) [0|1] ""  CGM_LS,TCP_LS,ONSTAR_LS,CHUD_LS,HUD_LS,RadioHead_LS
 SG_ ODIIIPC_ODIInd36 : 44|1@0+ (1,0) [0|1] ""  CGM_LS,TCP_LS,ONSTAR_LS,CHUD_LS,HUD_LS,RadioHead_LS
 SG_ ODIIIPC_ODIInd35 : 45|1@0+ (1,0) [0|1] ""  CGM_LS,TCP_LS,ONSTAR_LS,CHUD_LS,HUD_LS,RadioHead_LS
 SG_ ODIIIPC_ODIInd34 : 46|1@0+ (1,0) [0|1] ""  CGM_LS,TCP_LS,ONSTAR_LS,CHUD_LS,HUD_LS,RadioHead_LS
 SG_ ODIIIPC_ODIInd33 : 47|1@0+ (1,0) [0|1] ""  CGM_LS,TCP_LS,ONSTAR_LS,CHUD_LS,HUD_LS,RadioHead_LS
 SG_ ODIIIPC_ODIInd32 : 32|1@0+ (1,0) [0|1] ""  CGM_LS,TCP_LS,ONSTAR_LS,CHUD_LS,HUD_LS,RadioHead_LS
 SG_ ODIIIPC_ODIInd31 : 33|1@0+ (1,0) [0|1] ""  CGM_LS,TCP_LS,ONSTAR_LS,CHUD_LS,HUD_LS,RadioHead_LS
 SG_ ODIIIPC_ODIInd30 : 34|1@0+ (1,0) [0|1] ""  CGM_LS,TCP_LS,ONSTAR_LS,CHUD_LS,HUD_LS,RadioHead_LS
 SG_ ODIIIPC_ODIInd29 : 35|1@0+ (1,0) [0|1] ""  CGM_LS,TCP_LS,ONSTAR_LS,CHUD_LS,HUD_LS,RadioHead_LS
 SG_ ODIIIPC_ODIInd28 : 36|1@0+ (1,0) [0|1] ""  CGM_LS,TCP_LS,ONSTAR_LS,CHUD_LS,HUD_LS,RadioHead_LS
 SG_ ODIIIPC_ODIInd27 : 37|1@0+ (1,0) [0|1] ""  CGM_LS,TCP_LS,ONSTAR_LS,CHUD_LS,HUD_LS,RadioHead_LS
 SG_ ODIIIPC_ODIInd26 : 38|1@0+ (1,0) [0|1] ""  CGM_LS,TCP_LS,ONSTAR_LS,CHUD_LS,HUD_LS,RadioHead_LS
 SG_ ODIIIPC_ODIInd25 : 39|1@0+ (1,0) [0|1] ""  CGM_LS,TCP_LS,ONSTAR_LS,CHUD_LS,HUD_LS,RadioHead_LS
 SG_ ODIIIPC_ODIInd24 : 24|1@0+ (1,0) [0|1] ""  CGM_LS,TCP_LS,ONSTAR_LS,CHUD_LS,HUD_LS,RadioHead_LS
 SG_ ODIIIPC_ODIInd23 : 25|1@0+ (1,0) [0|1] ""  CGM_LS,TCP_LS,ONSTAR_LS,CHUD_LS,HUD_LS,RadioHead_LS
 SG_ ODIIIPC_ODIInd22 : 26|1@0+ (1,0) [0|1] ""  CGM_LS,TCP_LS,ONSTAR_LS,CHUD_LS,HUD_LS,RadioHead_LS
 SG_ ODIIIPC_ODIInd21 : 27|1@0+ (1,0) [0|1] ""  CGM_LS,TCP_LS,ONSTAR_LS,CHUD_LS,HUD_LS,RadioHead_LS
 SG_ ODIIIPC_ODIInd20 : 28|1@0+ (1,0) [0|1] ""  CGM_LS,TCP_LS,ONSTAR_LS,CHUD_LS,HUD_LS,RadioHead_LS
 SG_ ODIIIPC_ODIInd19 : 29|1@0+ (1,0) [0|1] ""  CGM_LS,TCP_LS,ONSTAR_LS,CHUD_LS,HUD_LS,RadioHead_LS
 SG_ ODIIIPC_ODIInd18 : 30|1@0+ (1,0) [0|1] ""  CGM_LS,TCP_LS,ONSTAR_LS,CHUD_LS,HUD_LS,RadioHead_LS
 SG_ ODIIIPC_ODIInd17 : 31|1@0+ (1,0) [0|1] ""  CGM_LS,TCP_LS,ONSTAR_LS,CHUD_LS,HUD_LS,RadioHead_LS
 SG_ ODIIIPC_ODIInd16 : 16|1@0+ (1,0) [0|1] ""  CGM_LS,TCP_LS,ONSTAR_LS,CHUD_LS,HUD_LS,RadioHead_LS
 SG_ ODIIIPC_ODIInd15 : 17|1@0+ (1,0) [0|1] ""  CGM_LS,TCP_LS,ONSTAR_LS,CHUD_LS,HUD_LS,RadioHead_LS
 SG_ ODIIIPC_ODIInd14 : 18|1@0+ (1,0) [0|1] ""  CGM_LS,TCP_LS,ONSTAR_LS,CHUD_LS,HUD_LS,RadioHead_LS
 SG_ ODIIIPC_ODIInd13 : 19|1@0+ (1,0) [0|1] ""  CGM_LS,TCP_LS,ONSTAR_LS,CHUD_LS,HUD_LS,RadioHead_LS
 SG_ ODIIIPC_ODIInd12 : 20|1@0+ (1,0) [0|1] ""  CGM_LS,TCP_LS,ONSTAR_LS,CHUD_LS,HUD_LS,RadioHead_LS
 SG_ ODIIIPC_ODIInd11 : 21|1@0+ (1,0) [0|1] ""  CGM_LS,TCP_LS,ONSTAR_LS,CHUD_LS,HUD_LS,RadioHead_LS
 SG_ ODIIIPC_ODIInd10 : 22|1@0+ (1,0) [0|1] ""  CGM_LS,TCP_LS,ONSTAR_LS,CHUD_LS,HUD_LS,RadioHead_LS
 SG_ ODIIIPC_ODIInd2 : 14|1@0+ (1,0) [0|1] ""  CGM_LS,TCP_LS,ONSTAR_LS,CHUD_LS,HUD_LS,RadioHead_LS
 SG_ ODIIIPC_ODIInd1 : 15|1@0+ (1,0) [0|1] ""  CGM_LS,TCP_LS,ONSTAR_LS,CHUD_LS,HUD_LS,RadioHead_LS
 SG_ ODIIIPC_FUCID : 7|8@0+ (1,0) [0|255] ""  CGM_LS,TCP_LS,ONSTAR_LS,CHUD_LS,HUD_LS,RadioHead_LS

BO_TX_BU_ 2151948288 : CGM_LS,CSM_LS,RadioHead_LS;
BO_TX_BU_ 2149728256 : BSM_LS,VICM_LS;
BO_TX_BU_ 2150023168 : BSM_LS,VICM_LS;
BO_TX_BU_ 2153988096 : BSM_LS,VICM_LS;
BO_TX_BU_ 2155945984 : CGM_LS,IPC_LS;
BO_TX_BU_ 1516 : BSM_LS,VICM_LS;
BO_TX_BU_ 2155585536 : CGM_LS,CSM_LS,RadioHead_LS;
BO_TX_BU_ 2155569152 : CGM_LS,CSM_LS,RadioHead_LS;
BO_TX_BU_ 2155233280 : BSM_LS,VICM_LS;
BO_TX_BU_ 2152759296 : EOCM2A_K2_LS,FCM_LS,EOCM_F_LS;
BO_TX_BU_ 2152742912 : EOCM2A_K2_LS,EOCM_F_LS;
BO_TX_BU_ 2150891520 : CGM_LS,CSM_LS,RadioHead_LS;
BO_TX_BU_ 2151751680 : MSM_P_LS,MSM_LS;
BO_TX_BU_ 2155536384 : EOCM2A_K2_LS,EOCM_F_LS;
BO_TX_BU_ 2151481344 : FCM_LS,EOCM2A_K2_LS,BCM_LS,EOCM_F_LS;
BO_TX_BU_ 2151432192 : FCM_LS,EOCM2A_K2_LS,EOCM_F_LS,BCM_LS;
BO_TX_BU_ 2151415808 : EOCM2A_K2_LS,FCM_LS,EOCM_F_LS;
BO_TX_BU_ 2151350272 : UPA_LS,APA_LS;
BO_TX_BU_ 2151333888 : EOCM2A_K2_LS,EOCM_F_LS,UPA_LS,APA_LS;
BO_TX_BU_ 2151522304 : CGM_LS,IPC_LS;
BO_TX_BU_ 2154741760 : RSC_LS,RSA_LS;
BO_TX_BU_ 2155364352 : BSM_LS,VICM_LS,BCM_LS;
BO_TX_BU_ 2154979328 : MSM_P_LS,HVSM_F_LS,MSM_LS;
BO_TX_BU_ 2151505920 : CGM_LS,IPC_LS;
BO_TX_BU_ 2156806144 : CGM_LS,TCP_LS,ONSTAR_LS;
BO_TX_BU_ 2155216896 : CGM_LS,CSM_LS,RadioHead_LS;
CM_ BO_ 2151481344 "CAUTION!!!! BOTH GATED AND Tx ON LS!! DO NOT ADD ONLY GATED SIGNALS";
CM_ BO_ 2151432192 "CAUTION!!!! BOTH GATED AND Tx ON LS!! DO NOT ADD ONLY GATED SIGNALS";
CM_ SG_ 2151079936 PDIMPrsnt "Indicates if the PDIM ECU is present on the bus.";
CM_ SG_ 2159058944 ODIEI_FUCID "ODI - Primary ID of Functional Unit in FU Database";
CM_ SG_ 2159058944 ODIEI_EvID "EventID within FUClass";
CM_ SG_ 2159042560 ODDI_DataVal "ODI";
CM_ SG_ 2159042560 ODDI_DataId "ODI-Data Id for the dynamic list";
CM_ SG_ 2159042560 ODDI_FUCID "ODI - Primary ID of Functional Unit in FU Database";
CM_ SG_ 2159042560 ODDI_InvldData "ODI";
CM_ SG_ 2159042560 ODDI_DataType "ODI";
CM_ SG_ 2155216896 SpdLmtUnits "This signal indicates the units used for the Speed Limit Posted Speed and Speed Limit Recommended Speed signals";
CM_ SG_ 2155216896 SpdLmtRecmndSpd "Seperate signal 'Speed Limit Units' must be used to define selectable units for this signal";
CM_ SG_ 2155216896 SpdLmtPstdSpd "Seperate signal 'Speed Limit Units' must be used to define selectable units for this signal";
CM_ SG_ 2158813184 ODIIIPC_FUCID "ODI - Primary ID of Functional Unit in FU Database";
BA_DEF_ SG_  "VNSigPrimaryTriggering" ENUM  "No","Yes","DLCLS","DLCHS","DLCCE","DLCFO";
BA_DEF_ SG_  "VNSigRemoteDiagnostics" ENUM  "No","Yes","DLCLS","DLCHS","DLCCE","DLCFO";
BA_DEF_ SG_  "VNSigInfotainment" ENUM  "No","Yes","DLCLS","DLCHS","DLCCE","DLCFO";
BA_DEF_ SG_  "VNSigParkedVehicle" ENUM  "No","Yes","DLCLS","DLCHS","DLCCE","DLCFO";
BA_DEF_ SG_  "VNSigIntermediate" ENUM  "No","Yes","DLCLS","DLCHS","DLCCE","DLCFO";
BA_DEF_ SG_  "VNSigUnused_4" ENUM  "No","Yes","DLCLS","DLCHS","DLCCE","DLCFO";
BA_DEF_ SG_  "SignalType" STRING ;
BA_DEF_ SG_  "PacketOrder" INT 0 65535;
BA_DEF_ SG_  "SignalLongName" STRING ;
BA_DEF_ SG_  "GenSigStartValue" INT 0 65535;
BA_DEF_ SG_  "VNSigDiagnostic" ENUM  "No","Yes","DLCLS","DLCHS","DLCCE","DLCFO";
BA_DEF_ SG_  "VNSigAllNodes" ENUM  "No","Yes","DLCLS","DLCHS","DLCCE","DLCFO";
BA_DEF_ SG_  "GenSigDeltaValue" INT 0 0;
BA_DEF_ SG_  "GenSigInactiveValue" INT 0 0;
BA_DEF_ SG_  "GenSigSendType" ENUM  "not used","not used","not used","not used","not used","not used","not used","NoSigSendType","not used","not used","OnAnyChange","OnChangeIfActive","OnDelta","DLCLS","DLCHS","DLCCE","DLCFO";
BA_DEF_ SG_  "GenSigSendOnInit" ENUM  "Not Initialized","Application","Handler","DLCLS","DLCHS","DLCCE","DLCFO";
BA_DEF_ BO_  "AppGenMsgCycleTime" INT 0 0;
BA_DEF_ BO_  "TpTxIndex" INT 0 99;
BA_DEF_ BO_  "GenMsgILSupport" ENUM  "No","Yes","DLCLS","DLCHS","DLCCE","DLCFO";
BA_DEF_ BO_  "TpApplType" STRING ;
BA_DEF_ BO_  "Prio" INT 0 7;
BA_DEF_ BO_  "MessageSubnet" ENUM  "LS","MS","HS","CE","PE","HV","FO","S1","HE","LE","HE2","DLCLS","DLCHS","DLCCE","DLCFO";
BA_DEF_ BO_  "GenMsgMandatoryToSupervision" ENUM  "No","Yes","DLCLS","DLCHS","DLCCE","DLCFO";
BA_DEF_ BO_  "DiagState" ENUM  "No","Yes","DLCLS","DLCHS","DLCCE","DLCFO";
BA_DEF_ BO_  "GenMsgStartDelayTime" INT 0 100000;
BA_DEF_ BO_  "GenMsgDelayTime" INT 0 100000;
BA_DEF_ BO_  "GenMsgCycleTime" INT 0 100000;
BA_DEF_ BO_  "GenMsgSendType" ENUM  "cyclicX","spontanX","cyclicIfActiveX","spontanWithDelay","cyclicAndSpontanX","cyclicAndSpontanWithDelay","spontanWithRepitition","cyclicIfActiveAndSpontanWD","DLCLS","DLCHS","DLCCE","DLCFO";
BA_DEF_ BO_  "DiagResponse" ENUM  "No","Yes","DLCLS","DLCHS","DLCCE","DLCFO";
BA_DEF_ BO_  "DiagRequest" ENUM  "No","Yes","DLCLS","DLCHS","DLCCE","DLCFO";
BA_DEF_ BO_  "NmMessage" ENUM  "No","Yes","DLCLS","DLCHS","DLCCE","DLCFO";
BA_DEF_REL_ BU_SG_REL_  "GenSigSuprvRespComment" STRING ;
BA_DEF_REL_ BU_SG_REL_  "GenSigVBitResp" ENUM  "No","Yes","DLCLS","DLCHS","DLCCE","DLCFO";
BA_DEF_REL_ BU_SG_REL_  "GenSigVBitRespComment" STRING ;
BA_DEF_REL_ BU_SG_REL_  "GenSigVDAFailComment" STRING ;
BA_DEF_REL_ BU_SG_REL_  "GenSigVDAFailResp" ENUM  "No","Yes","DLCLS","DLCHS","DLCCE","DLCFO";
BA_DEF_REL_ BU_SG_REL_  "GenSigRxStartValue" STRING ;
BA_DEF_REL_ BU_SG_REL_  "GenSigSuprvRespSubValue" INT 0 65535;
BA_DEF_REL_ BU_SG_REL_  "GenSigSuprvResp" ENUM  "None","Notify App","Substitute Default","DLCLS","DLCHS","DLCCE","DLCFO";
BA_DEF_REL_ BU_SG_REL_  "GenSigTimeoutMsg" HEX -2147483648 268435455;
BA_DEF_REL_ BU_SG_REL_  "GenSigTimeoutTime" INT 0 15000;
BA_DEF_DEF_  "VNSigPrimaryTriggering" "No";
BA_DEF_DEF_  "VNSigRemoteDiagnostics" "No";
BA_DEF_DEF_  "VNSigInfotainment" "No";
BA_DEF_DEF_  "VNSigParkedVehicle" "No";
BA_DEF_DEF_  "VNSigIntermediate" "No";
BA_DEF_DEF_  "VNSigUnused_4" "No";
BA_DEF_DEF_  "SignalType" "";
BA_DEF_DEF_  "PacketOrder" 0;
BA_DEF_DEF_  "SignalLongName" "";
BA_DEF_DEF_  "GenSigStartValue" 0;
BA_DEF_DEF_  "VNSigDiagnostic" "No";
BA_DEF_DEF_  "VNSigAllNodes" "No";
BA_DEF_DEF_  "GenSigDeltaValue" 0;
BA_DEF_DEF_  "GenSigInactiveValue" 0;
BA_DEF_DEF_  "GenSigSendType" "NoSigSendType";
BA_DEF_DEF_  "GenSigSendOnInit" "Not Initialized";
BA_DEF_DEF_  "AppGenMsgCycleTime" 0;
BA_DEF_DEF_  "TpTxIndex" 0;
BA_DEF_DEF_  "GenMsgILSupport" "Yes";
BA_DEF_DEF_  "TpApplType" "";
BA_DEF_DEF_  "Prio" 4;
BA_DEF_DEF_  "MessageSubnet" "FO";
BA_DEF_DEF_  "GenMsgMandatoryToSupervision" "No";
BA_DEF_DEF_  "DiagState" "No";
BA_DEF_DEF_  "GenMsgStartDelayTime" 0;
BA_DEF_DEF_  "GenMsgDelayTime" 0;
BA_DEF_DEF_  "GenMsgCycleTime" 0;
BA_DEF_DEF_  "GenMsgSendType" "spontanX";
BA_DEF_DEF_  "DiagResponse" "No";
BA_DEF_DEF_  "DiagRequest" "No";
BA_DEF_DEF_  "NmMessage" "No";
BA_DEF_DEF_REL_ "GenSigSuprvRespComment" "";
BA_DEF_DEF_REL_ "GenSigVBitResp" "No";
BA_DEF_DEF_REL_ "GenSigVBitRespComment" "";
BA_DEF_DEF_REL_ "GenSigVDAFailComment" "";
BA_DEF_DEF_REL_ "GenSigVDAFailResp" "No";
BA_DEF_DEF_REL_ "GenSigRxStartValue" "";
BA_DEF_DEF_REL_ "GenSigSuprvRespSubValue" 0;
BA_DEF_DEF_REL_ "GenSigSuprvResp" "None";
BA_DEF_DEF_REL_ "GenSigTimeoutMsg" 0;
BA_DEF_DEF_REL_ "GenSigTimeoutTime" 0;
BA_ "MessageSubnet" BO_ 2158034944 0;
BA_ "GenMsgDelayTime" BO_ 2158034944 100;
BA_ "MessageSubnet" BO_ 2158018560 0;
BA_ "GenMsgDelayTime" BO_ 2158018560 100;
BA_ "MessageSubnet" BO_ 2156838912 0;
BA_ "GenMsgDelayTime" BO_ 2156838912 100;
BA_ "MessageSubnet" BO_ 2156822528 0;
BA_ "GenMsgDelayTime" BO_ 2156822528 100;
BA_ "MessageSubnet" BO_ 2151948288 0;
BA_ "GenMsgDelayTime" BO_ 2151948288 100;
BA_ "MessageSubnet" BO_ 2158002176 0;
BA_ "GenMsgDelayTime" BO_ 2158002176 100;
BA_ "MessageSubnet" BO_ 2149728256 0;
BA_ "GenMsgDelayTime" BO_ 2149728256 100;
BA_ "MessageSubnet" BO_ 2150023168 0;
BA_ "GenMsgCycleTime" BO_ 2150023168 250;
BA_ "GenMsgSendType" BO_ 2150023168 0;
BA_ "MessageSubnet" BO_ 2153988096 0;
BA_ "GenMsgDelayTime" BO_ 2153988096 100;
BA_ "MessageSubnet" BO_ 2155945984 0;
BA_ "GenMsgDelayTime" BO_ 2155945984 100;
BA_ "GenMsgILSupport" BO_ 1516 0;
BA_ "TpApplType" BO_ 1516 "DiagUUDTResponse";
BA_ "Prio" BO_ 1516 0;
BA_ "MessageSubnet" BO_ 1516 0;
BA_ "MessageSubnet" BO_ 2155585536 0;
BA_ "GenMsgDelayTime" BO_ 2155585536 100;
BA_ "MessageSubnet" BO_ 2155569152 0;
BA_ "GenMsgDelayTime" BO_ 2155569152 100;
BA_ "MessageSubnet" BO_ 2155233280 0;
BA_ "GenMsgDelayTime" BO_ 2155233280 100;
BA_ "MessageSubnet" BO_ 2152759296 0;
BA_ "GenMsgDelayTime" BO_ 2152759296 100;
BA_ "MessageSubnet" BO_ 2152742912 0;
BA_ "GenMsgDelayTime" BO_ 2152742912 100;
BA_ "MessageSubnet" BO_ 2150891520 0;
BA_ "GenMsgDelayTime" BO_ 2150891520 100;
BA_ "MessageSubnet" BO_ 2151751680 0;
BA_ "GenMsgDelayTime" BO_ 2151751680 100;
BA_ "MessageSubnet" BO_ 2155536384 0;
BA_ "GenMsgDelayTime" BO_ 2155536384 100;
BA_ "MessageSubnet" BO_ 2151481344 0;
BA_ "GenMsgCycleTime" BO_ 2151481344 200;
BA_ "GenMsgSendType" BO_ 2151481344 0;
BA_ "MessageSubnet" BO_ 2151432192 0;
BA_ "GenMsgCycleTime" BO_ 2151432192 200;
BA_ "GenMsgSendType" BO_ 2151432192 0;
BA_ "MessageSubnet" BO_ 2151415808 0;
BA_ "GenMsgDelayTime" BO_ 2151415808 100;
BA_ "MessageSubnet" BO_ 2151350272 0;
BA_ "GenMsgDelayTime" BO_ 2151350272 100;
BA_ "MessageSubnet" BO_ 2151333888 0;
BA_ "GenMsgDelayTime" BO_ 2151333888 100;
BA_ "MessageSubnet" BO_ 2151522304 0;
BA_ "GenMsgDelayTime" BO_ 2151522304 100;
BA_ "MessageSubnet" BO_ 2150629376 0;
BA_ "GenMsgDelayTime" BO_ 2150629376 100;
BA_ "MessageSubnet" BO_ 2155929600 0;
BA_ "GenMsgCycleTime" BO_ 2155929600 1000;
BA_ "GenMsgSendType" BO_ 2155929600 0;
BA_ "MessageSubnet" BO_ 2154741760 0;
BA_ "GenMsgDelayTime" BO_ 2154741760 100;
BA_ "MessageSubnet" BO_ 2154807296 0;
BA_ "GenMsgDelayTime" BO_ 2154807296 100;
BA_ "MessageSubnet" BO_ 2151079936 0;
BA_ "GenMsgDelayTime" BO_ 2151079936 100;
BA_ "MessageSubnet" BO_ 2155364352 0;
BA_ "GenMsgStartDelayTime" BO_ 2155364352 10;
BA_ "GenMsgDelayTime" BO_ 2155364352 100;
BA_ "GenMsgCycleTime" BO_ 2155364352 250;
BA_ "GenMsgSendType" BO_ 2155364352 0;
BA_ "MessageSubnet" BO_ 2154979328 0;
BA_ "GenMsgDelayTime" BO_ 2154979328 100;
BA_ "MessageSubnet" BO_ 2155282432 0;
BA_ "GenMsgDelayTime" BO_ 2155282432 100;
BA_ "MessageSubnet" BO_ 2151505920 0;
BA_ "GenMsgDelayTime" BO_ 2151505920 100;
BA_ "GenMsgCycleTime" BO_ 2151505920 1000;
BA_ "GenMsgSendType" BO_ 2151505920 0;
BA_ "MessageSubnet" BO_ 2155896832 0;
BA_ "GenMsgStartDelayTime" BO_ 2155896832 170;
BA_ "GenMsgCycleTime" BO_ 2155896832 500;
BA_ "GenMsgSendType" BO_ 2155896832 0;
BA_ "MessageSubnet" BO_ 2155552768 0;
BA_ "GenMsgDelayTime" BO_ 2155552768 100;
BA_ "MessageSubnet" BO_ 2154496000 0;
BA_ "GenMsgDelayTime" BO_ 2154496000 100;
BA_ "MessageSubnet" BO_ 2155208704 0;
BA_ "GenMsgDelayTime" BO_ 2155208704 100;
BA_ "MessageSubnet" BO_ 2153390080 0;
BA_ "GenMsgDelayTime" BO_ 2153390080 500;
BA_ "MessageSubnet" BO_ 2155175936 0;
BA_ "GenMsgDelayTime" BO_ 2155175936 200;
BA_ "MessageSubnet" BO_ 2156806144 0;
BA_ "GenMsgDelayTime" BO_ 2156806144 500;
BA_ "MessageSubnet" BO_ 2154078208 0;
BA_ "GenMsgDelayTime" BO_ 2154078208 200;
BA_ "MessageSubnet" BO_ 2159058944 0;
BA_ "GenMsgDelayTime" BO_ 2159058944 100;
BA_ "MessageSubnet" BO_ 2159042560 0;
BA_ "GenMsgDelayTime" BO_ 2159042560 100;
BA_ "MessageSubnet" BO_ 2150006784 0;
BA_ "GenMsgDelayTime" BO_ 2150006784 100;
BA_ "MessageSubnet" BO_ 2155216896 0;
BA_ "GenMsgDelayTime" BO_ 2155216896 100;
BA_ "MessageSubnet" BO_ 2156216320 0;
BA_ "GenMsgDelayTime" BO_ 2156216320 100;
BA_ "MessageSubnet" BO_ 2158813184 0;
BA_ "GenMsgDelayTime" BO_ 2158813184 100;
BA_ "GenSigSendType" SG_ 2158034944 VidSrcCompFormatER 10;
BA_ "SignalType" SG_ 2158034944 VidSrcCompFormatER "ENM";
BA_ "SignalLongName" SG_ 2158034944 VidSrcCompFormatER "Video Source Composite Format Extended Range";
BA_ "VNSigAllNodes" SG_ 2158034944 VidSrcCompFormatER 1;
BA_ "GenSigSendType" SG_ 2158034944 CurntTVStnServc 10;
BA_ "SignalType" SG_ 2158034944 CurntTVStnServc "ENM";
BA_ "SignalLongName" SG_ 2158034944 CurntTVStnServc "Current TV Station Service";
BA_ "VNSigAllNodes" SG_ 2158034944 CurntTVStnServc 1;
BA_ "GenSigSendType" SG_ 2158034944 CurntTVStnQual 10;
BA_ "SignalType" SG_ 2158034944 CurntTVStnQual "ENM";
BA_ "SignalLongName" SG_ 2158034944 CurntTVStnQual "Current TV Station Quality";
BA_ "VNSigAllNodes" SG_ 2158034944 CurntTVStnQual 1;
BA_ "GenSigSendType" SG_ 2158034944 VidSrcType 10;
BA_ "SignalType" SG_ 2158034944 VidSrcType "ENM";
BA_ "SignalLongName" SG_ 2158034944 VidSrcType "Video Source Type";
BA_ "VNSigAllNodes" SG_ 2158034944 VidSrcType 1;
BA_ "GenSigSendType" SG_ 2158034944 VidSrcStatCode 10;
BA_ "SignalType" SG_ 2158034944 VidSrcStatCode "ENM";
BA_ "SignalLongName" SG_ 2158034944 VidSrcStatCode "Video Source Status Code";
BA_ "VNSigAllNodes" SG_ 2158034944 VidSrcStatCode 1;
BA_ "GenSigSendType" SG_ 2158034944 TVTunerPres 10;
BA_ "SignalType" SG_ 2158034944 TVTunerPres "BLN";
BA_ "SignalLongName" SG_ 2158034944 TVTunerPres "Television Tuner Present";
BA_ "VNSigAllNodes" SG_ 2158034944 TVTunerPres 1;
BA_ "GenSigSendType" SG_ 2158034944 RmtRcvrTunStat 10;
BA_ "SignalType" SG_ 2158034944 RmtRcvrTunStat "ENM";
BA_ "SignalLongName" SG_ 2158034944 RmtRcvrTunStat "Remote Receiver Tuning Status";
BA_ "VNSigAllNodes" SG_ 2158034944 RmtRcvrTunStat 1;
BA_ "GenSigSendType" SG_ 2158034944 RemRcvrSrcInpStat 10;
BA_ "SignalType" SG_ 2158034944 RemRcvrSrcInpStat "ENM";
BA_ "SignalLongName" SG_ 2158034944 RemRcvrSrcInpStat "Remote Receiver Source Input Status";
BA_ "VNSigAllNodes" SG_ 2158034944 RemRcvrSrcInpStat 1;
BA_ "GenSigDeltaValue" SG_ 2158034944 RmtRcvrPrgrmServID 1;
BA_ "GenSigSendType" SG_ 2158034944 RmtRcvrPrgrmServID 12;
BA_ "SignalType" SG_ 2158034944 RmtRcvrPrgrmServID "UNM";
BA_ "SignalLongName" SG_ 2158034944 RmtRcvrPrgrmServID "Remote Receiver Program Service ID";
BA_ "VNSigAllNodes" SG_ 2158034944 RmtRcvrPrgrmServID 1;
BA_ "GenSigSendType" SG_ 2158034944 RmtRecvtDataTyp 10;
BA_ "SignalType" SG_ 2158034944 RmtRecvtDataTyp "ENM";
BA_ "SignalLongName" SG_ 2158034944 RmtRecvtDataTyp "Remote Receiver Data Type";
BA_ "VNSigAllNodes" SG_ 2158034944 RmtRecvtDataTyp 1;
BA_ "GenSigSendType" SG_ 2158034944 RmtRcvrCmndStat 10;
BA_ "SignalType" SG_ 2158034944 RmtRcvrCmndStat "ENM";
BA_ "SignalLongName" SG_ 2158034944 RmtRcvrCmndStat "Remote Receiver Command Status";
BA_ "VNSigAllNodes" SG_ 2158034944 RmtRcvrCmndStat 1;
BA_ "GenSigSendType" SG_ 2158018560 TVStatNmeChar1_8 10;
BA_ "SignalType" SG_ 2158018560 TVStatNmeChar1_8 "ASC";
BA_ "SignalLongName" SG_ 2158018560 TVStatNmeChar1_8 "TV Station Name Character 1-8";
BA_ "VNSigAllNodes" SG_ 2158018560 TVStatNmeChar1_8 1;
BA_ "GenSigDeltaValue" SG_ 2156838912 WSR_WiFiStnMACAddr 1;
BA_ "GenSigSendType" SG_ 2156838912 WSR_WiFiStnMACAddr 12;
BA_ "SignalType" SG_ 2156838912 WSR_WiFiStnMACAddr "UNM";
BA_ "PacketOrder" SG_ 2156838912 WSR_WiFiStnMACAddr 2;
BA_ "SignalLongName" SG_ 2156838912 WSR_WiFiStnMACAddr "WiFi Station Response : WiFi Station Media Access Control Address";
BA_ "VNSigAllNodes" SG_ 2156838912 WSR_WiFiStnMACAddr 1;
BA_ "GenSigSendType" SG_ 2156838912 WSR_WiFiAssnStat 10;
BA_ "SignalType" SG_ 2156838912 WSR_WiFiAssnStat "ENM";
BA_ "PacketOrder" SG_ 2156838912 WSR_WiFiAssnStat 1;
BA_ "SignalLongName" SG_ 2156838912 WSR_WiFiAssnStat "WiFi Station Response : WiFi Association Status";
BA_ "VNSigAllNodes" SG_ 2156838912 WSR_WiFiAssnStat 1;
BA_ "GenSigSendType" SG_ 2156822528 WAPD_EncrptnType 10;
BA_ "GenSigSendOnInit" SG_ 2156822528 WAPD_EncrptnType 2;
BA_ "SignalType" SG_ 2156822528 WAPD_EncrptnType "ENM";
BA_ "PacketOrder" SG_ 2156822528 WAPD_EncrptnType 3;
BA_ "SignalLongName" SG_ 2156822528 WAPD_EncrptnType "WiFi Access Point Data : Encryption Type";
BA_ "VNSigAllNodes" SG_ 2156822528 WAPD_EncrptnType 1;
BA_ "GenSigSendType" SG_ 2156822528 WAPD_SecurityType 10;
BA_ "GenSigSendOnInit" SG_ 2156822528 WAPD_SecurityType 2;
BA_ "SignalType" SG_ 2156822528 WAPD_SecurityType "ENM";
BA_ "PacketOrder" SG_ 2156822528 WAPD_SecurityType 2;
BA_ "SignalLongName" SG_ 2156822528 WAPD_SecurityType "WiFi Access Point Data : Security Type";
BA_ "VNSigAllNodes" SG_ 2156822528 WAPD_SecurityType 1;
BA_ "GenSigSendType" SG_ 2156822528 WAPD_IHUWiFiEnStat 10;
BA_ "GenSigSendOnInit" SG_ 2156822528 WAPD_IHUWiFiEnStat 2;
BA_ "SignalType" SG_ 2156822528 WAPD_IHUWiFiEnStat "ENM";
BA_ "PacketOrder" SG_ 2156822528 WAPD_IHUWiFiEnStat 1;
BA_ "SignalLongName" SG_ 2156822528 WAPD_IHUWiFiEnStat "WiFi Access Point Data : Infotainment Head Unit WiFi Enabled Status";
BA_ "VNSigAllNodes" SG_ 2156822528 WAPD_IHUWiFiEnStat 1;
BA_ "GenSigSendType" SG_ 2151948288 RunBrdOpMdCstStReq 10;
BA_ "SignalType" SG_ 2151948288 RunBrdOpMdCstStReq "ENM";
BA_ "SignalLongName" SG_ 2151948288 RunBrdOpMdCstStReq "Running Boards Operating Mode Customization Setting Request";
BA_ "VNSigAllNodes" SG_ 2151948288 RunBrdOpMdCstStReq 1;
BA_ "GenSigSendType" SG_ 2151948288 DrvDrowDetCstStRq 10;
BA_ "SignalType" SG_ 2151948288 DrvDrowDetCstStRq "ENM";
BA_ "SignalLongName" SG_ 2151948288 DrvDrowDetCstStRq "Driver Drowsiness Detection Customization Setting Request";
BA_ "VNSigAllNodes" SG_ 2151948288 DrvDrowDetCstStRq 1;
BA_ "GenSigSendType" SG_ 2158002176 SrvcPrvdr 10;
BA_ "SignalType" SG_ 2158002176 SrvcPrvdr "ENM";
BA_ "SignalLongName" SG_ 2158002176 SrvcPrvdr "Service Provider";
BA_ "VNSigAllNodes" SG_ 2158002176 SrvcPrvdr 1;
BA_ "GenSigSendType" SG_ 2158002176 CurntStnServc 10;
BA_ "SignalType" SG_ 2158002176 CurntStnServc "ENM";
BA_ "SignalLongName" SG_ 2158002176 CurntStnServc "Current Station Service";
BA_ "VNSigAllNodes" SG_ 2158002176 CurntStnServc 1;
BA_ "GenSigDeltaValue" SG_ 2149728256 PrtyChrgStPnt 1;
BA_ "GenSigSendType" SG_ 2149728256 PrtyChrgStPnt 12;
BA_ "GenSigSendOnInit" SG_ 2149728256 PrtyChrgStPnt 1;
BA_ "VNSigInfotainment" SG_ 2149728256 PrtyChrgStPnt 1;
BA_ "SignalType" SG_ 2149728256 PrtyChrgStPnt "UNM";
BA_ "SignalLongName" SG_ 2149728256 PrtyChrgStPnt "Priority Charging Set Point";
BA_ "VNSigAllNodes" SG_ 2149728256 PrtyChrgStPnt 1;
BA_ "GenSigSendType" SG_ 2149728256 PrtyChrgActIO 10;
BA_ "VNSigInfotainment" SG_ 2149728256 PrtyChrgActIO 1;
BA_ "SignalType" SG_ 2149728256 PrtyChrgActIO "BLN";
BA_ "SignalLongName" SG_ 2149728256 PrtyChrgActIO "Priority Charging Active Indication On";
BA_ "VNSigAllNodes" SG_ 2149728256 PrtyChrgActIO 1;
BA_ "GenSigSendType" SG_ 2149728256 PrtyChrgAct 10;
BA_ "GenSigSendOnInit" SG_ 2149728256 PrtyChrgAct 1;
BA_ "VNSigInfotainment" SG_ 2149728256 PrtyChrgAct 1;
BA_ "SignalType" SG_ 2149728256 PrtyChrgAct "BLN";
BA_ "SignalLongName" SG_ 2149728256 PrtyChrgAct "Priority Charging Active";
BA_ "VNSigAllNodes" SG_ 2149728256 PrtyChrgAct 1;
BA_ "GenSigSendType" SG_ 2149728256 EngAstHtPlgInCsStAvl 10;
BA_ "GenSigSendOnInit" SG_ 2149728256 EngAstHtPlgInCsStAvl 1;
BA_ "VNSigInfotainment" SG_ 2149728256 EngAstHtPlgInCsStAvl 1;
BA_ "SignalType" SG_ 2149728256 EngAstHtPlgInCsStAvl "BLN";
BA_ "SignalLongName" SG_ 2149728256 EngAstHtPlgInCsStAvl "Engine Assisted Heating Plugged-In Customization Setting Available";
BA_ "VNSigAllNodes" SG_ 2149728256 EngAstHtPlgInCsStAvl 1;
BA_ "GenSigSendType" SG_ 2149728256 EngAstHtPlgInCsCrStVl 10;
BA_ "GenSigSendOnInit" SG_ 2149728256 EngAstHtPlgInCsCrStVl 1;
BA_ "VNSigInfotainment" SG_ 2149728256 EngAstHtPlgInCsCrStVl 1;
BA_ "SignalType" SG_ 2149728256 EngAstHtPlgInCsCrStVl "ENM";
BA_ "SignalLongName" SG_ 2149728256 EngAstHtPlgInCsCrStVl "Engine Assisted Heating Plugged-In Customization Current Setting Value";
BA_ "VNSigAllNodes" SG_ 2149728256 EngAstHtPlgInCsCrStVl 1;
BA_ "GenSigSendType" SG_ 2149728256 EngAstHtCsStAvl 10;
BA_ "GenSigSendOnInit" SG_ 2149728256 EngAstHtCsStAvl 1;
BA_ "VNSigInfotainment" SG_ 2149728256 EngAstHtCsStAvl 1;
BA_ "SignalType" SG_ 2149728256 EngAstHtCsStAvl "BLN";
BA_ "SignalLongName" SG_ 2149728256 EngAstHtCsStAvl "Engine Assisted Heating Customization Setting Available";
BA_ "VNSigAllNodes" SG_ 2149728256 EngAstHtCsStAvl 1;
BA_ "GenSigSendType" SG_ 2149728256 EngAstHtCsCrStVal 10;
BA_ "GenSigSendOnInit" SG_ 2149728256 EngAstHtCsCrStVal 1;
BA_ "VNSigInfotainment" SG_ 2149728256 EngAstHtCsCrStVal 1;
BA_ "SignalType" SG_ 2149728256 EngAstHtCsCrStVal "ENM";
BA_ "SignalLongName" SG_ 2149728256 EngAstHtCsCrStVal "Engine Assisted Heating Customization Current Setting Value";
BA_ "VNSigAllNodes" SG_ 2149728256 EngAstHtCsCrStVal 1;
BA_ "GenSigSendType" SG_ 2149728256 HghVltgPropState 10;
BA_ "VNSigInfotainment" SG_ 2149728256 HghVltgPropState 1;
BA_ "SignalType" SG_ 2149728256 HghVltgPropState "ENM";
BA_ "SignalLongName" SG_ 2149728256 HghVltgPropState "High Voltage Propulsion State";
BA_ "VNSigAllNodes" SG_ 2149728256 HghVltgPropState 1;
BA_ "GenSigSendType" SG_ 2149728256 HVChrgPwrLvl 10;
BA_ "GenSigSendOnInit" SG_ 2149728256 HVChrgPwrLvl 1;
BA_ "VNSigInfotainment" SG_ 2149728256 HVChrgPwrLvl 1;
BA_ "SignalType" SG_ 2149728256 HVChrgPwrLvl "ENM";
BA_ "SignalLongName" SG_ 2149728256 HVChrgPwrLvl "High Voltage Charger Power Level";
BA_ "VNSigAllNodes" SG_ 2149728256 HVChrgPwrLvl 1;
BA_ "GenSigSendType" SG_ 2149728256 ChrgPrtDrStat 10;
BA_ "GenSigSendOnInit" SG_ 2149728256 ChrgPrtDrStat 1;
BA_ "VNSigInfotainment" SG_ 2149728256 ChrgPrtDrStat 1;
BA_ "SignalType" SG_ 2149728256 ChrgPrtDrStat "ENM";
BA_ "SignalLongName" SG_ 2149728256 ChrgPrtDrStat "Charge Port Door Status";
BA_ "VNSigAllNodes" SG_ 2149728256 ChrgPrtDrStat 1;
BA_ "GenSigSendType" SG_ 2149728256 ChgCdTfAlCzStAvbl 10;
BA_ "GenSigSendOnInit" SG_ 2149728256 ChgCdTfAlCzStAvbl 1;
BA_ "VNSigInfotainment" SG_ 2149728256 ChgCdTfAlCzStAvbl 1;
BA_ "SignalType" SG_ 2149728256 ChgCdTfAlCzStAvbl "BLN";
BA_ "SignalLongName" SG_ 2149728256 ChgCdTfAlCzStAvbl "Charge Cord Theft Alert Customization Setting Available";
BA_ "VNSigAllNodes" SG_ 2149728256 ChgCdTfAlCzStAvbl 1;
BA_ "GenSigSendType" SG_ 2149728256 ChgCdTfAlCzCrStVal 10;
BA_ "GenSigSendOnInit" SG_ 2149728256 ChgCdTfAlCzCrStVal 1;
BA_ "VNSigInfotainment" SG_ 2149728256 ChgCdTfAlCzCrStVal 1;
BA_ "SignalType" SG_ 2149728256 ChgCdTfAlCzCrStVal "ENM";
BA_ "SignalLongName" SG_ 2149728256 ChgCdTfAlCzCrStVal "Charge Cord Theft Alert Customization Current Setting Value";
BA_ "VNSigAllNodes" SG_ 2149728256 ChgCdTfAlCzCrStVal 1;
BA_ "GenSigSendType" SG_ 2149728256 ChrgSysTrnsShftLckRq 10;
BA_ "VNSigInfotainment" SG_ 2149728256 ChrgSysTrnsShftLckRq 1;
BA_ "SignalType" SG_ 2149728256 ChrgSysTrnsShftLckRq "BLN";
BA_ "SignalLongName" SG_ 2149728256 ChrgSysTrnsShftLckRq "Charging System Transmission Shift Lock Requested";
BA_ "VNSigAllNodes" SG_ 2149728256 ChrgSysTrnsShftLckRq 1;
BA_ "GenSigSendType" SG_ 2149728256 ChgPwLsAlCzStAvbl 10;
BA_ "GenSigSendOnInit" SG_ 2149728256 ChgPwLsAlCzStAvbl 1;
BA_ "VNSigInfotainment" SG_ 2149728256 ChgPwLsAlCzStAvbl 1;
BA_ "SignalType" SG_ 2149728256 ChgPwLsAlCzStAvbl "BLN";
BA_ "SignalLongName" SG_ 2149728256 ChgPwLsAlCzStAvbl "Charge Power Loss Alert Customization Setting Available";
BA_ "VNSigAllNodes" SG_ 2149728256 ChgPwLsAlCzStAvbl 1;
BA_ "GenSigSendType" SG_ 2149728256 ChgPwLsAlCzCrStVal 10;
BA_ "GenSigSendOnInit" SG_ 2149728256 ChgPwLsAlCzCrStVal 1;
BA_ "VNSigInfotainment" SG_ 2149728256 ChgPwLsAlCzCrStVal 1;
BA_ "SignalType" SG_ 2149728256 ChgPwLsAlCzCrStVal "ENM";
BA_ "SignalLongName" SG_ 2149728256 ChgPwLsAlCzCrStVal "Charge Power Loss Alert Customization Current Setting Value";
BA_ "VNSigAllNodes" SG_ 2149728256 ChgPwLsAlCzCrStVal 1;
BA_ "GenSigSendType" SG_ 2149728256 ChgSysAudInCsStAvl 10;
BA_ "GenSigSendOnInit" SG_ 2149728256 ChgSysAudInCsStAvl 1;
BA_ "VNSigInfotainment" SG_ 2149728256 ChgSysAudInCsStAvl 1;
BA_ "SignalType" SG_ 2149728256 ChgSysAudInCsStAvl "BLN";
BA_ "SignalLongName" SG_ 2149728256 ChgSysAudInCsStAvl "Charger System Audible Indication Customization Setting Available";
BA_ "VNSigAllNodes" SG_ 2149728256 ChgSysAudInCsStAvl 1;
BA_ "GenSigSendType" SG_ 2149728256 ChgSyAudInCsCrStVa 10;
BA_ "GenSigSendOnInit" SG_ 2149728256 ChgSyAudInCsCrStVa 1;
BA_ "VNSigInfotainment" SG_ 2149728256 ChgSyAudInCsCrStVa 1;
BA_ "SignalType" SG_ 2149728256 ChgSyAudInCsCrStVa "ENM";
BA_ "SignalLongName" SG_ 2149728256 ChgSyAudInCsCrStVa "Charger System Audible Indication Customization Current Setting Value";
BA_ "VNSigAllNodes" SG_ 2149728256 ChgSyAudInCsCrStVa 1;
BA_ "SignalType" SG_ 2150023168 OffBrdVehImmbNot "ENM";
BA_ "SignalLongName" SG_ 2150023168 OffBrdVehImmbNot "Off Board Vehicle Immobilization Notification";
BA_ "VNSigAllNodes" SG_ 2150023168 OffBrdVehImmbNot 1;
BA_ "VNSigInfotainment" SG_ 2150023168 ElecPrplsnMtrTach 1;
BA_ "SignalType" SG_ 2150023168 ElecPrplsnMtrTach "UNM";
BA_ "SignalLongName" SG_ 2150023168 ElecPrplsnMtrTach "Electric Propulsion Motor Tachometer";
BA_ "VNSigAllNodes" SG_ 2150023168 ElecPrplsnMtrTach 1;
BA_ "GenSigSendOnInit" SG_ 2150023168 HVInvRatVltV 1;
BA_ "SignalType" SG_ 2150023168 HVInvRatVltV "ENM";
BA_ "SignalLongName" SG_ 2150023168 HVInvRatVltV "High Voltage Inverter Rationalized Voltage  Validity";
BA_ "VNSigAllNodes" SG_ 2150023168 HVInvRatVltV 1;
BA_ "GenSigSendOnInit" SG_ 2150023168 HVInvRatVlt 1;
BA_ "SignalType" SG_ 2150023168 HVInvRatVlt "UNM";
BA_ "SignalLongName" SG_ 2150023168 HVInvRatVlt "High Voltage Inverter Rationalized Voltage";
BA_ "VNSigAllNodes" SG_ 2150023168 HVInvRatVlt 1;
BA_ "GenSigSendOnInit" SG_ 2150023168 HybChrgMdStat 1;
BA_ "VNSigInfotainment" SG_ 2150023168 HybChrgMdStat 1;
BA_ "SignalType" SG_ 2150023168 HybChrgMdStat "ENM";
BA_ "SignalLongName" SG_ 2150023168 HybChrgMdStat "Hybrid Charge Mode State";
BA_ "VNSigAllNodes" SG_ 2150023168 HybChrgMdStat 1;
BA_ "GenSigDeltaValue" SG_ 2153988096 EUS_TtEngyUsgScrAvVal 1;
BA_ "GenSigSendType" SG_ 2153988096 EUS_TtEngyUsgScrAvVal 12;
BA_ "GenSigSendOnInit" SG_ 2153988096 EUS_TtEngyUsgScrAvVal 1;
BA_ "VNSigInfotainment" SG_ 2153988096 EUS_TtEngyUsgScrAvVal 1;
BA_ "SignalType" SG_ 2153988096 EUS_TtEngyUsgScrAvVal "SNM";
BA_ "PacketOrder" SG_ 2153988096 EUS_TtEngyUsgScrAvVal 5;
BA_ "SignalLongName" SG_ 2153988096 EUS_TtEngyUsgScrAvVal "Energy Usage Score : Total Energy Usage Score Value";
BA_ "VNSigAllNodes" SG_ 2153988096 EUS_TtEngyUsgScrAvVal 1;
BA_ "GenSigDeltaValue" SG_ 2153988096 EUS_ITEngyUsgScrAvVal 1;
BA_ "GenSigSendType" SG_ 2153988096 EUS_ITEngyUsgScrAvVal 12;
BA_ "GenSigSendOnInit" SG_ 2153988096 EUS_ITEngyUsgScrAvVal 1;
BA_ "VNSigInfotainment" SG_ 2153988096 EUS_ITEngyUsgScrAvVal 1;
BA_ "SignalType" SG_ 2153988096 EUS_ITEngyUsgScrAvVal "SNM";
BA_ "PacketOrder" SG_ 2153988096 EUS_ITEngyUsgScrAvVal 4;
BA_ "SignalLongName" SG_ 2153988096 EUS_ITEngyUsgScrAvVal "Energy Usage Score : Inside Temperature Energy Usage Score Average Value";
BA_ "VNSigAllNodes" SG_ 2153988096 EUS_ITEngyUsgScrAvVal 1;
BA_ "GenSigDeltaValue" SG_ 2153988096 EUS_OTEngyUsgScrAvVal 1;
BA_ "GenSigSendType" SG_ 2153988096 EUS_OTEngyUsgScrAvVal 12;
BA_ "GenSigSendOnInit" SG_ 2153988096 EUS_OTEngyUsgScrAvVal 1;
BA_ "VNSigInfotainment" SG_ 2153988096 EUS_OTEngyUsgScrAvVal 1;
BA_ "SignalType" SG_ 2153988096 EUS_OTEngyUsgScrAvVal "SNM";
BA_ "PacketOrder" SG_ 2153988096 EUS_OTEngyUsgScrAvVal 3;
BA_ "SignalLongName" SG_ 2153988096 EUS_OTEngyUsgScrAvVal "Energy Usage Score : Outside Temperature Energy Usage Score Average Value";
BA_ "VNSigAllNodes" SG_ 2153988096 EUS_OTEngyUsgScrAvVal 1;
BA_ "GenSigDeltaValue" SG_ 2153988096 EUS_TrEngyUsgScrAvVal 1;
BA_ "GenSigSendType" SG_ 2153988096 EUS_TrEngyUsgScrAvVal 12;
BA_ "GenSigSendOnInit" SG_ 2153988096 EUS_TrEngyUsgScrAvVal 1;
BA_ "VNSigInfotainment" SG_ 2153988096 EUS_TrEngyUsgScrAvVal 1;
BA_ "SignalType" SG_ 2153988096 EUS_TrEngyUsgScrAvVal "SNM";
BA_ "PacketOrder" SG_ 2153988096 EUS_TrEngyUsgScrAvVal 2;
BA_ "SignalLongName" SG_ 2153988096 EUS_TrEngyUsgScrAvVal "Energy Usage Score : Terrain Energy Usage Score Average Value";
BA_ "VNSigAllNodes" SG_ 2153988096 EUS_TrEngyUsgScrAvVal 1;
BA_ "GenSigDeltaValue" SG_ 2153988096 EUS_TcEngyUsgScrAvVal 1;
BA_ "GenSigSendType" SG_ 2153988096 EUS_TcEngyUsgScrAvVal 12;
BA_ "GenSigSendOnInit" SG_ 2153988096 EUS_TcEngyUsgScrAvVal 1;
BA_ "VNSigInfotainment" SG_ 2153988096 EUS_TcEngyUsgScrAvVal 1;
BA_ "SignalType" SG_ 2153988096 EUS_TcEngyUsgScrAvVal "SNM";
BA_ "PacketOrder" SG_ 2153988096 EUS_TcEngyUsgScrAvVal 1;
BA_ "SignalLongName" SG_ 2153988096 EUS_TcEngyUsgScrAvVal "Energy Usage Score : Technique Energy Usage Score Average Value";
BA_ "VNSigAllNodes" SG_ 2153988096 EUS_TcEngyUsgScrAvVal 1;
BA_ "GenSigSendType" SG_ 2153988096 PwrElecCoolLpTempM 10;
BA_ "GenSigSendOnInit" SG_ 2153988096 PwrElecCoolLpTempM 1;
BA_ "SignalType" SG_ 2153988096 PwrElecCoolLpTempM "ENM";
BA_ "SignalLongName" SG_ 2153988096 PwrElecCoolLpTempM "Power Electronics Cooling Loop Temperature Mask";
BA_ "VNSigAllNodes" SG_ 2153988096 PwrElecCoolLpTempM 1;
BA_ "GenSigSendType" SG_ 2153988096 PwrElecCoolLpTempV 10;
BA_ "GenSigSendOnInit" SG_ 2153988096 PwrElecCoolLpTempV 1;
BA_ "SignalType" SG_ 2153988096 PwrElecCoolLpTempV "ENM";
BA_ "SignalLongName" SG_ 2153988096 PwrElecCoolLpTempV "Power Electronics Cooling Loop Temperature Validity";
BA_ "VNSigAllNodes" SG_ 2153988096 PwrElecCoolLpTempV 1;
BA_ "GenSigDeltaValue" SG_ 2153988096 PwrElecCoolLpTemp 1;
BA_ "GenSigSendType" SG_ 2153988096 PwrElecCoolLpTemp 12;
BA_ "GenSigSendOnInit" SG_ 2153988096 PwrElecCoolLpTemp 1;
BA_ "SignalType" SG_ 2153988096 PwrElecCoolLpTemp "UNM";
BA_ "SignalLongName" SG_ 2153988096 PwrElecCoolLpTemp "Power Electronics Cooling Loop Temperature";
BA_ "VNSigAllNodes" SG_ 2153988096 PwrElecCoolLpTemp 1;
BA_ "GenSigSendType" SG_ 2155945984 VehStbEnhmntCurStRq 10;
BA_ "SignalType" SG_ 2155945984 VehStbEnhmntCurStRq "ENM";
BA_ "SignalLongName" SG_ 2155945984 VehStbEnhmntCurStRq "Vehicle Stability Enhancement Current State Request";
BA_ "VNSigAllNodes" SG_ 2155945984 VehStbEnhmntCurStRq 1;
BA_ "GenSigSendType" SG_ 2155945984 VehStbCmptvMdCurStRq 10;
BA_ "SignalType" SG_ 2155945984 VehStbCmptvMdCurStRq "ENM";
BA_ "SignalLongName" SG_ 2155945984 VehStbCmptvMdCurStRq "Vehicle Stability Competitive Mode Current State Request";
BA_ "VNSigAllNodes" SG_ 2155945984 VehStbCmptvMdCurStRq 1;
BA_ "GenSigSendType" SG_ 2155945984 TCSysCurStReq 10;
BA_ "SignalType" SG_ 2155945984 TCSysCurStReq "ENM";
BA_ "SignalLongName" SG_ 2155945984 TCSysCurStReq "Traction Control System Current State Request";
BA_ "VNSigAllNodes" SG_ 2155945984 TCSysCurStReq 1;
BA_ "GenSigSendType" SG_ 2155945984 JmpStrtReq 10;
BA_ "GenSigSendOnInit" SG_ 2155945984 JmpStrtReq 1;
BA_ "SignalType" SG_ 2155945984 JmpStrtReq "BLN";
BA_ "SignalLongName" SG_ 2155945984 JmpStrtReq "Jump Start Requested";
BA_ "VNSigAllNodes" SG_ 2155945984 JmpStrtReq 1;
BA_ "SignalType" SG_ 1516 DgnInf_LS5EC "UNM";
BA_ "SignalLongName" SG_ 1516 DgnInf_LS5EC "Diagnostic Information LS5EC";
BA_ "VNSigDiagnostic" SG_ 1516 DgnInf_LS5EC 1;
BA_ "VNSigAllNodes" SG_ 1516 DgnInf_LS5EC 1;
BA_ "GenSigSendType" SG_ 2155585536 StBltTgtCSRq 10;
BA_ "GenSigSendOnInit" SG_ 2155585536 StBltTgtCSRq 1;
BA_ "SignalType" SG_ 2155585536 StBltTgtCSRq "ENM";
BA_ "SignalLongName" SG_ 2155585536 StBltTgtCSRq "Seat Belt Tightening Customize Setting Request";
BA_ "VNSigAllNodes" SG_ 2155585536 StBltTgtCSRq 1;
BA_ "GenSigSendType" SG_ 2155569152 SmPhRmFunCstStReq 10;
BA_ "VNSigInfotainment" SG_ 2155569152 SmPhRmFunCstStReq 1;
BA_ "SignalType" SG_ 2155569152 SmPhRmFunCstStReq "ENM";
BA_ "SignalLongName" SG_ 2155569152 SmPhRmFunCstStReq "Smart Phone Remote Function Customization Setting Request";
BA_ "VNSigAllNodes" SG_ 2155569152 SmPhRmFunCstStReq 1;
BA_ "GenSigSendType" SG_ 2155569152 HLOCCstSetReq 10;
BA_ "SignalType" SG_ 2155569152 HLOCCstSetReq "ENM";
BA_ "SignalLongName" SG_ 2155569152 HLOCCstSetReq "Handsfree Liftgate Open Close Customization Setting Request";
BA_ "VNSigAllNodes" SG_ 2155569152 HLOCCstSetReq 1;
BA_ "GenSigSendType" SG_ 2155569152 IntDimSeldClrTypStReq 10;
BA_ "SignalType" SG_ 2155569152 IntDimSeldClrTypStReq "ENM";
BA_ "SignalLongName" SG_ 2155569152 IntDimSeldClrTypStReq "Interior Dimming Selected Color Type Setting Request";
BA_ "VNSigAllNodes" SG_ 2155569152 IntDimSeldClrTypStReq 1;
BA_ "GenSigSendType" SG_ 2155569152 IntDimSeldAnmTypStReq 10;
BA_ "SignalType" SG_ 2155569152 IntDimSeldAnmTypStReq "ENM";
BA_ "SignalLongName" SG_ 2155569152 IntDimSeldAnmTypStReq "Interior Dimming Selected Animation Type Setting Request";
BA_ "VNSigAllNodes" SG_ 2155569152 IntDimSeldAnmTypStReq 1;
BA_ "GenSigSendType" SG_ 2155569152 ExtHlStrAssCsStRq 10;
BA_ "GenSigSendOnInit" SG_ 2155569152 ExtHlStrAssCsStRq 1;
BA_ "SignalType" SG_ 2155569152 ExtHlStrAssCsStRq "ENM";
BA_ "SignalLongName" SG_ 2155569152 ExtHlStrAssCsStRq "Extended Hill Start Assist Customization Setting Request";
BA_ "VNSigAllNodes" SG_ 2155569152 ExtHlStrAssCsStRq 1;
BA_ "GenSigSendType" SG_ 2155569152 ColPrSysCustReq 10;
BA_ "GenSigSendOnInit" SG_ 2155569152 ColPrSysCustReq 1;
BA_ "SignalType" SG_ 2155569152 ColPrSysCustReq "ENM";
BA_ "SignalLongName" SG_ 2155569152 ColPrSysCustReq "Collision Preparation System Customization Setting Request";
BA_ "VNSigAllNodes" SG_ 2155569152 ColPrSysCustReq 1;
BA_ "GenSigSendType" SG_ 2155233280 InstnsFlEcnHybOvrdReq 10;
BA_ "SignalType" SG_ 2155233280 InstnsFlEcnHybOvrdReq "ENM";
BA_ "SignalLongName" SG_ 2155233280 InstnsFlEcnHybOvrdReq "Instantaneous Fuel Economy Hybrid Override Request";
BA_ "VNSigAllNodes" SG_ 2155233280 InstnsFlEcnHybOvrdReq 1;
BA_ "GenSigSendType" SG_ 2155233280 NtrlGrWrngIO 10;
BA_ "SignalType" SG_ 2155233280 NtrlGrWrngIO "BLN";
BA_ "SignalLongName" SG_ 2155233280 NtrlGrWrngIO "Neutral Gear Warning Indication On";
BA_ "VNSigAllNodes" SG_ 2155233280 NtrlGrWrngIO 1;
BA_ "GenSigSendType" SG_ 2155233280 RtBsChrgCmplnTmPrfRsp 10;
BA_ "GenSigSendOnInit" SG_ 2155233280 RtBsChrgCmplnTmPrfRsp 1;
BA_ "VNSigInfotainment" SG_ 2155233280 RtBsChrgCmplnTmPrfRsp 1;
BA_ "SignalType" SG_ 2155233280 RtBsChrgCmplnTmPrfRsp "ENM";
BA_ "SignalLongName" SG_ 2155233280 RtBsChrgCmplnTmPrfRsp "Rate Based Charge Completion Time Preference Response";
BA_ "VNSigAllNodes" SG_ 2155233280 RtBsChrgCmplnTmPrfRsp 1;
BA_ "GenSigSendType" SG_ 2155233280 EngRnngDutoVehSpdIO 10;
BA_ "SignalType" SG_ 2155233280 EngRnngDutoVehSpdIO "BLN";
BA_ "SignalLongName" SG_ 2155233280 EngRnngDutoVehSpdIO "Engine Running Due to Vehicle Speed Indication On";
BA_ "VNSigAllNodes" SG_ 2155233280 EngRnngDutoVehSpdIO 1;
BA_ "GenSigDeltaValue" SG_ 2155233280 ChrgCyclFuelEcn 1;
BA_ "GenSigSendType" SG_ 2155233280 ChrgCyclFuelEcn 12;
BA_ "GenSigSendOnInit" SG_ 2155233280 ChrgCyclFuelEcn 1;
BA_ "VNSigInfotainment" SG_ 2155233280 ChrgCyclFuelEcn 1;
BA_ "SignalType" SG_ 2155233280 ChrgCyclFuelEcn "UNM";
BA_ "SignalLongName" SG_ 2155233280 ChrgCyclFuelEcn "Charge Cycle Fuel Economy";
BA_ "VNSigAllNodes" SG_ 2155233280 ChrgCyclFuelEcn 1;
BA_ "GenSigDeltaValue" SG_ 2155233280 LiftimeFuelEcnEquiv 1;
BA_ "GenSigSendType" SG_ 2155233280 LiftimeFuelEcnEquiv 12;
BA_ "GenSigSendOnInit" SG_ 2155233280 LiftimeFuelEcnEquiv 1;
BA_ "VNSigInfotainment" SG_ 2155233280 LiftimeFuelEcnEquiv 1;
BA_ "SignalType" SG_ 2155233280 LiftimeFuelEcnEquiv "UNM";
BA_ "SignalLongName" SG_ 2155233280 LiftimeFuelEcnEquiv "Lifetime Fuel Economy Equivalent";
BA_ "VNSigAllNodes" SG_ 2155233280 LiftimeFuelEcnEquiv 1;
BA_ "GenSigSendType" SG_ 2155233280 ShftPrkIO_3B2 10;
BA_ "SignalType" SG_ 2155233280 ShftPrkIO_3B2 "BLN";
BA_ "SignalLongName" SG_ 2155233280 ShftPrkIO_3B2 "Shift to Park Indication On";
BA_ "VNSigAllNodes" SG_ 2155233280 ShftPrkIO_3B2 1;
BA_ "GenSigDeltaValue" SG_ 2155233280 LftmFuelEcon 1;
BA_ "GenSigSendType" SG_ 2155233280 LftmFuelEcon 12;
BA_ "GenSigSendOnInit" SG_ 2155233280 LftmFuelEcon 1;
BA_ "VNSigInfotainment" SG_ 2155233280 LftmFuelEcon 1;
BA_ "SignalType" SG_ 2155233280 LftmFuelEcon "UNM";
BA_ "SignalLongName" SG_ 2155233280 LftmFuelEcon "Lifetime Fuel Economy";
BA_ "VNSigAllNodes" SG_ 2155233280 LftmFuelEcon 1;
BA_ "GenSigSendType" SG_ 2155233280 FlDrOpenIndOn 10;
BA_ "VNSigInfotainment" SG_ 2155233280 FlDrOpenIndOn 1;
BA_ "SignalType" SG_ 2155233280 FlDrOpenIndOn "BLN";
BA_ "SignalLongName" SG_ 2155233280 FlDrOpenIndOn "Fuel Door Open Indication On";
BA_ "VNSigAllNodes" SG_ 2155233280 FlDrOpenIndOn 1;
BA_ "GenSigSendType" SG_ 2155233280 VehRefuelSt 10;
BA_ "VNSigInfotainment" SG_ 2155233280 VehRefuelSt 1;
BA_ "SignalType" SG_ 2155233280 VehRefuelSt "ENM";
BA_ "SignalLongName" SG_ 2155233280 VehRefuelSt "Vehicle Refueling State";
BA_ "VNSigAllNodes" SG_ 2155233280 VehRefuelSt 1;
BA_ "GenSigSendType" SG_ 2155233280 NtrlCstdwnCrtMdActvIO 10;
BA_ "SignalType" SG_ 2155233280 NtrlCstdwnCrtMdActvIO "BLN";
BA_ "SignalLongName" SG_ 2155233280 NtrlCstdwnCrtMdActvIO "Neutral Coastdown Certification Mode Active Indication On";
BA_ "VNSigAllNodes" SG_ 2155233280 NtrlCstdwnCrtMdActvIO 1;
BA_ "GenSigSendType" SG_ 2155233280 UtlChrgPopUpAct 10;
BA_ "GenSigSendOnInit" SG_ 2155233280 UtlChrgPopUpAct 1;
BA_ "VNSigInfotainment" SG_ 2155233280 UtlChrgPopUpAct 1;
BA_ "SignalType" SG_ 2155233280 UtlChrgPopUpAct "BLN";
BA_ "SignalLongName" SG_ 2155233280 UtlChrgPopUpAct "Utility Charging Interference Pop Up Active";
BA_ "VNSigAllNodes" SG_ 2155233280 UtlChrgPopUpAct 1;
BA_ "GenSigSendType" SG_ 2155233280 UtlChrgIntrfrIO 10;
BA_ "GenSigSendOnInit" SG_ 2155233280 UtlChrgIntrfrIO 1;
BA_ "VNSigInfotainment" SG_ 2155233280 UtlChrgIntrfrIO 1;
BA_ "SignalType" SG_ 2155233280 UtlChrgIntrfrIO "BLN";
BA_ "SignalLongName" SG_ 2155233280 UtlChrgIntrfrIO "Utility Charging Interference Indication On";
BA_ "VNSigAllNodes" SG_ 2155233280 UtlChrgIntrfrIO 1;
BA_ "GenSigSendType" SG_ 2152759296 PedWrnIndReq 10;
BA_ "SignalType" SG_ 2152759296 PedWrnIndReq "ENM";
BA_ "SignalLongName" SG_ 2152759296 PedWrnIndReq "Pedestrian Warning Indication Request";
BA_ "VNSigAllNodes" SG_ 2152759296 PedWrnIndReq 1;
BA_ "GenSigSendType" SG_ 2152759296 FrtRdrFldIO 10;
BA_ "SignalType" SG_ 2152759296 FrtRdrFldIO "BLN";
BA_ "SignalLongName" SG_ 2152759296 FrtRdrFldIO "Front Radar Failed Indication On";
BA_ "VNSigAllNodes" SG_ 2152759296 FrtRdrFldIO 1;
BA_ "GenSigSendType" SG_ 2152759296 FrtCmrFldIO 10;
BA_ "SignalType" SG_ 2152759296 FrtCmrFldIO "BLN";
BA_ "SignalLongName" SG_ 2152759296 FrtCmrFldIO "Front Camera Failed Indication on";
BA_ "VNSigAllNodes" SG_ 2152759296 FrtCmrFldIO 1;
BA_ "GenSigSendType" SG_ 2152759296 FrtEOCMMdlFldIO 10;
BA_ "SignalType" SG_ 2152759296 FrtEOCMMdlFldIO "BLN";
BA_ "SignalLongName" SG_ 2152759296 FrtEOCMMdlFldIO "Front External Object Calculating Module Failed Indication On";
BA_ "VNSigAllNodes" SG_ 2152759296 FrtEOCMMdlFldIO 1;
BA_ "GenSigSendType" SG_ 2152759296 FrtCmrBlckdIO 10;
BA_ "GenSigSendOnInit" SG_ 2152759296 FrtCmrBlckdIO 2;
BA_ "SignalType" SG_ 2152759296 FrtCmrBlckdIO "BLN";
BA_ "SignalLongName" SG_ 2152759296 FrtCmrBlckdIO "Front Camera Block Indication On";
BA_ "VNSigAllNodes" SG_ 2152759296 FrtCmrBlckdIO 1;
BA_ "GenSigSendType" SG_ 2152742912 ShrtRngRdrOffIO 10;
BA_ "SignalType" SG_ 2152742912 ShrtRngRdrOffIO "BLN";
BA_ "SignalLongName" SG_ 2152742912 ShrtRngRdrOffIO "Short Range Radar Off Indication On";
BA_ "VNSigAllNodes" SG_ 2152742912 ShrtRngRdrOffIO 1;
BA_ "GenSigSendType" SG_ 2152742912 RrRdrFldIO 10;
BA_ "SignalType" SG_ 2152742912 RrRdrFldIO "BLN";
BA_ "SignalLongName" SG_ 2152742912 RrRdrFldIO "Rear Radar Failed Indication On";
BA_ "VNSigAllNodes" SG_ 2152742912 RrRdrFldIO 1;
BA_ "GenSigSendType" SG_ 2152742912 RrRdrBlckdIO 10;
BA_ "GenSigSendOnInit" SG_ 2152742912 RrRdrBlckdIO 2;
BA_ "SignalType" SG_ 2152742912 RrRdrBlckdIO "BLN";
BA_ "SignalLongName" SG_ 2152742912 RrRdrBlckdIO "Rear Radar Blocked Indication On";
BA_ "VNSigAllNodes" SG_ 2152742912 RrRdrBlckdIO 1;
BA_ "GenSigSendType" SG_ 2152742912 RrEOCMMdlFldIO 10;
BA_ "SignalType" SG_ 2152742912 RrEOCMMdlFldIO "BLN";
BA_ "SignalLongName" SG_ 2152742912 RrEOCMMdlFldIO "Rear External Object Calculating Module Failed Indication On";
BA_ "VNSigAllNodes" SG_ 2152742912 RrEOCMMdlFldIO 1;
BA_ "GenSigSendType" SG_ 2150891520 RrStRmndrCstSetReq 10;
BA_ "SignalType" SG_ 2150891520 RrStRmndrCstSetReq "ENM";
BA_ "SignalLongName" SG_ 2150891520 RrStRmndrCstSetReq "Rear Seat Reminder Customization Setting Request";
BA_ "VNSigAllNodes" SG_ 2150891520 RrStRmndrCstSetReq 1;
BA_ "GenSigSendType" SG_ 2150891520 DgtlMapPsgRstrctn 10;
BA_ "SignalType" SG_ 2150891520 DgtlMapPsgRstrctn "ENM";
BA_ "SignalLongName" SG_ 2150891520 DgtlMapPsgRstrctn "Digital Map Passing Restriction";
BA_ "VNSigAllNodes" SG_ 2150891520 DgtlMapPsgRstrctn 1;
BA_ "GenSigSendType" SG_ 2150891520 DgtlMapCndlSpdLmt 10;
BA_ "SignalType" SG_ 2150891520 DgtlMapCndlSpdLmt "ENM";
BA_ "SignalLongName" SG_ 2150891520 DgtlMapCndlSpdLmt "Digital Map Conditional Speed Limit";
BA_ "VNSigAllNodes" SG_ 2150891520 DgtlMapCndlSpdLmt 1;
BA_ "GenSigSendType" SG_ 2150891520 DgtlMapCndlSpdLmtTyp 10;
BA_ "SignalType" SG_ 2150891520 DgtlMapCndlSpdLmtTyp "ENM";
BA_ "SignalLongName" SG_ 2150891520 DgtlMapCndlSpdLmtTyp "Digital Map Conditional Speed Limit Type";
BA_ "VNSigAllNodes" SG_ 2150891520 DgtlMapCndlSpdLmtTyp 1;
BA_ "GenSigSendType" SG_ 2150891520 DgtlMapEffSpdLmt 10;
BA_ "SignalType" SG_ 2150891520 DgtlMapEffSpdLmt "ENM";
BA_ "SignalLongName" SG_ 2150891520 DgtlMapEffSpdLmt "Digital Map Effective Speed Limit";
BA_ "VNSigAllNodes" SG_ 2150891520 DgtlMapEffSpdLmt 1;
BA_ "GenSigSendType" SG_ 2150891520 DgtlMapEffSpdLmtTyp 10;
BA_ "SignalType" SG_ 2150891520 DgtlMapEffSpdLmtTyp "ENM";
BA_ "SignalLongName" SG_ 2150891520 DgtlMapEffSpdLmtTyp "Digital Map Effective Speed Limit Type";
BA_ "VNSigAllNodes" SG_ 2150891520 DgtlMapEffSpdLmtTyp 1;
BA_ "GenSigSendType" SG_ 2150891520 DgtlMapSpdCat 10;
BA_ "SignalType" SG_ 2150891520 DgtlMapSpdCat "ENM";
BA_ "SignalLongName" SG_ 2150891520 DgtlMapSpdCat "Digital Map Speed Category";
BA_ "VNSigAllNodes" SG_ 2150891520 DgtlMapSpdCat 1;
BA_ "GenSigSendType" SG_ 2150891520 DgtlMapVerQtr 10;
BA_ "SignalType" SG_ 2150891520 DgtlMapVerQtr "ENM";
BA_ "SignalLongName" SG_ 2150891520 DgtlMapVerQtr "Digital Map Version Quarter";
BA_ "VNSigAllNodes" SG_ 2150891520 DgtlMapVerQtr 1;
BA_ "GenSigSendType" SG_ 2150891520 DgtlMapVerYr 10;
BA_ "SignalType" SG_ 2150891520 DgtlMapVerYr "ENM";
BA_ "SignalLongName" SG_ 2150891520 DgtlMapVerYr "Digital Map Version Year";
BA_ "VNSigAllNodes" SG_ 2150891520 DgtlMapVerYr 1;
BA_ "GenSigSendType" SG_ 2150891520 DgtlMapDrvngSd 10;
BA_ "SignalType" SG_ 2150891520 DgtlMapDrvngSd "ENM";
BA_ "SignalLongName" SG_ 2150891520 DgtlMapDrvngSd "Digital Map Driving Side";
BA_ "VNSigAllNodes" SG_ 2150891520 DgtlMapDrvngSd 1;
BA_ "GenSigSendType" SG_ 2150891520 FwdClnAlrtCustStngReq 10;
BA_ "GenSigSendOnInit" SG_ 2150891520 FwdClnAlrtCustStngReq 1;
BA_ "SignalType" SG_ 2150891520 FwdClnAlrtCustStngReq "ENM";
BA_ "SignalLongName" SG_ 2150891520 FwdClnAlrtCustStngReq "Forward Collision Alert Customization Setting Request";
BA_ "VNSigAllNodes" SG_ 2150891520 FwdClnAlrtCustStngReq 1;
BA_ "GenSigSendType" SG_ 2150891520 GNCustStngReq 10;
BA_ "GenSigSendOnInit" SG_ 2150891520 GNCustStngReq 1;
BA_ "SignalType" SG_ 2150891520 GNCustStngReq "ENM";
BA_ "SignalLongName" SG_ 2150891520 GNCustStngReq "Go Notifier Customization Setting Request";
BA_ "VNSigAllNodes" SG_ 2150891520 GNCustStngReq 1;
BA_ "GenSigSendType" SG_ 2151751680 HptcStVbnStat 10;
BA_ "SignalType" SG_ 2151751680 HptcStVbnStat "ENM";
BA_ "SignalLongName" SG_ 2151751680 HptcStVbnStat "Haptic Seat Vibration Status";
BA_ "VNSigAllNodes" SG_ 2151751680 HptcStVbnStat 1;
BA_ "GenSigSendType" SG_ 2151751680 HptcStFldIO 10;
BA_ "SignalType" SG_ 2151751680 HptcStFldIO "BLN";
BA_ "SignalLongName" SG_ 2151751680 HptcStFldIO "Haptic Seat Failed Indication On";
BA_ "VNSigAllNodes" SG_ 2151751680 HptcStFldIO 1;
BA_ "GenSigSendType" SG_ 2151751680 CrshAlrtDrvrSlctdType 10;
BA_ "GenSigSendOnInit" SG_ 2151751680 CrshAlrtDrvrSlctdType 1;
BA_ "SignalType" SG_ 2151751680 CrshAlrtDrvrSlctdType "ENM";
BA_ "SignalLongName" SG_ 2151751680 CrshAlrtDrvrSlctdType "Crash Alert Driver Selected Type";
BA_ "VNSigAllNodes" SG_ 2151751680 CrshAlrtDrvrSlctdType 1;
BA_ "GenSigSendType" SG_ 2151751680 CrshAlrtStPrsnt 10;
BA_ "GenSigSendOnInit" SG_ 2151751680 CrshAlrtStPrsnt 1;
BA_ "SignalType" SG_ 2151751680 CrshAlrtStPrsnt "BLN";
BA_ "SignalLongName" SG_ 2151751680 CrshAlrtStPrsnt "Crash Alert Seat Present";
BA_ "VNSigAllNodes" SG_ 2151751680 CrshAlrtStPrsnt 1;
BA_ "GenSigSendType" SG_ 2155536384 RevClnMtgnBrkReqAct 10;
BA_ "SignalType" SG_ 2155536384 RevClnMtgnBrkReqAct "BLN";
BA_ "SignalLongName" SG_ 2155536384 RevClnMtgnBrkReqAct "Reverse Collision Mitigation Braking Request Active";
BA_ "VNSigAllNodes" SG_ 2155536384 RevClnMtgnBrkReqAct 1;
BA_ "GenSigSendType" SG_ 2155536384 TnDrvRIMOffUnbIO 10;
BA_ "SignalType" SG_ 2155536384 TnDrvRIMOffUnbIO "BLN";
BA_ "SignalLongName" SG_ 2155536384 TnDrvRIMOffUnbIO "Teen Driver Reverse Impact Mitigation Off Unavailable Indication On";
BA_ "VNSigAllNodes" SG_ 2155536384 TnDrvRIMOffUnbIO 1;
BA_ "GenSigSendType" SG_ 2155536384 RVBUnblIO 10;
BA_ "GenSigSendOnInit" SG_ 2155536384 RVBUnblIO 2;
BA_ "SignalType" SG_ 2155536384 RVBUnblIO "BLN";
BA_ "SignalLongName" SG_ 2155536384 RVBUnblIO "Rear Virtual Bumper Unavailable Indication On";
BA_ "VNSigAllNodes" SG_ 2155536384 RVBUnblIO 1;
BA_ "GenSigSendType" SG_ 2155536384 RVBFldIO 10;
BA_ "SignalType" SG_ 2155536384 RVBFldIO "BLN";
BA_ "SignalLongName" SG_ 2155536384 RVBFldIO "Rear Virtual Bumper Failed Indication On";
BA_ "VNSigAllNodes" SG_ 2155536384 RVBFldIO 1;
BA_ "GenSigSendType" SG_ 2155536384 RVBEnbldIO 10;
BA_ "SignalType" SG_ 2155536384 RVBEnbldIO "BLN";
BA_ "SignalLongName" SG_ 2155536384 RVBEnbldIO "Rear Virtual Bumper Enabled Indication On";
BA_ "VNSigAllNodes" SG_ 2155536384 RVBEnbldIO 1;
BA_ "GenSigSendType" SG_ 2155536384 RVBDsbldIO 10;
BA_ "SignalType" SG_ 2155536384 RVBDsbldIO "BLN";
BA_ "SignalLongName" SG_ 2155536384 RVBDsbldIO "Rear Virtual Bumper Disabled Indication On";
BA_ "VNSigAllNodes" SG_ 2155536384 RVBDsbldIO 1;
BA_ "GenSigSendType" SG_ 2151481344 HdUpDsplyUnblIO 10;
BA_ "SignalType" SG_ 2151481344 HdUpDsplyUnblIO "BLN";
BA_ "SignalLongName" SG_ 2151481344 HdUpDsplyUnblIO "Head Up Display Unavailable Indication On";
BA_ "VNSigAllNodes" SG_ 2151481344 HdUpDsplyUnblIO 1;
BA_ "GenSigSendType" SG_ 2151481344 FSRACCFrstRsmPrssIO 10;
BA_ "SignalType" SG_ 2151481344 FSRACCFrstRsmPrssIO "BLN";
BA_ "SignalLongName" SG_ 2151481344 FSRACCFrstRsmPrssIO "Full Speed Range Adaptive Cruise Control First Resume Press Indication On";
BA_ "VNSigAllNodes" SG_ 2151481344 FSRACCFrstRsmPrssIO 1;
BA_ "GenSigSendType" SG_ 2151481344 FrtRdrBlckdIO 10;
BA_ "SignalType" SG_ 2151481344 FrtRdrBlckdIO "BLN";
BA_ "SignalLongName" SG_ 2151481344 FrtRdrBlckdIO "Front Radar Blocked Indication On";
BA_ "VNSigAllNodes" SG_ 2151481344 FrtRdrBlckdIO 1;
BA_ "GenSigSendType" SG_ 2151481344 ShtToPrkBfExtngVehIO 10;
BA_ "SignalType" SG_ 2151481344 ShtToPrkBfExtngVehIO "BLN";
BA_ "SignalLongName" SG_ 2151481344 ShtToPrkBfExtngVehIO "Shift to Park Before Exiting Vehicle Indication On";
BA_ "VNSigAllNodes" SG_ 2151481344 ShtToPrkBfExtngVehIO 1;
BA_ "GenSigSendType" SG_ 2151481344 AutoBrkRlsIO 10;
BA_ "SignalType" SG_ 2151481344 AutoBrkRlsIO "BLN";
BA_ "SignalLongName" SG_ 2151481344 AutoBrkRlsIO "Autonomous Brake Release Indication On";
BA_ "VNSigAllNodes" SG_ 2151481344 AutoBrkRlsIO 1;
BA_ "SignalType" SG_ 2151432192 ACCHptcStVbnRqSeqN "UNM";
BA_ "SignalLongName" SG_ 2151432192 ACCHptcStVbnRqSeqN "Adaptive Cruise Control Haptic Seat Vibration Request Sequence Number";
BA_ "VNSigAllNodes" SG_ 2151432192 ACCHptcStVbnRqSeqN 1;
BA_ "SignalType" SG_ 2151432192 ACCHptcStVbnReq "UNM";
BA_ "SignalLongName" SG_ 2151432192 ACCHptcStVbnReq "Adaptive Cruise Control Haptic Seat Vibration Request";
BA_ "VNSigAllNodes" SG_ 2151432192 ACCHptcStVbnReq 1;
BA_ "GenSigSendType" SG_ 2151415808 FrPedDetCsStAvl 10;
BA_ "GenSigSendOnInit" SG_ 2151415808 FrPedDetCsStAvl 2;
BA_ "SignalType" SG_ 2151415808 FrPedDetCsStAvl "BLN";
BA_ "SignalLongName" SG_ 2151415808 FrPedDetCsStAvl "Front Pedestrian Detection Customization Setting Available";
BA_ "VNSigAllNodes" SG_ 2151415808 FrPedDetCsStAvl 1;
BA_ "GenSigSendType" SG_ 2151415808 FrPedDetCsCrStVal 10;
BA_ "GenSigSendOnInit" SG_ 2151415808 FrPedDetCsCrStVal 2;
BA_ "SignalType" SG_ 2151415808 FrPedDetCsCrStVal "ENM";
BA_ "SignalLongName" SG_ 2151415808 FrPedDetCsCrStVal "Front Pedestrian Detection Customization Current Setting Value";
BA_ "VNSigAllNodes" SG_ 2151415808 FrPedDetCsCrStVal 1;
BA_ "GenSigDeltaValue" SG_ 2151415808 RgtLnChgThrtHptStRqSN 1;
BA_ "GenSigSendType" SG_ 2151415808 RgtLnChgThrtHptStRqSN 12;
BA_ "SignalType" SG_ 2151415808 RgtLnChgThrtHptStRqSN "UNM";
BA_ "SignalLongName" SG_ 2151415808 RgtLnChgThrtHptStRqSN "Right Lane Change Threat Haptic Seat Request Sequence Number";
BA_ "VNSigAllNodes" SG_ 2151415808 RgtLnChgThrtHptStRqSN 1;
BA_ "GenSigDeltaValue" SG_ 2151415808 RgtLnChgThrtHptStRq 1;
BA_ "GenSigSendType" SG_ 2151415808 RgtLnChgThrtHptStRq 12;
BA_ "SignalType" SG_ 2151415808 RgtLnChgThrtHptStRq "UNM";
BA_ "SignalLongName" SG_ 2151415808 RgtLnChgThrtHptStRq "Right Lane Change Threat Haptic Seat Request";
BA_ "VNSigAllNodes" SG_ 2151415808 RgtLnChgThrtHptStRq 1;
BA_ "GenSigDeltaValue" SG_ 2151415808 LftLnChgThrtHptStRqSN 1;
BA_ "GenSigSendType" SG_ 2151415808 LftLnChgThrtHptStRqSN 12;
BA_ "SignalType" SG_ 2151415808 LftLnChgThrtHptStRqSN "UNM";
BA_ "SignalLongName" SG_ 2151415808 LftLnChgThrtHptStRqSN "Left Lane Change Threat Haptic Seat Request Sequence Number";
BA_ "VNSigAllNodes" SG_ 2151415808 LftLnChgThrtHptStRqSN 1;
BA_ "GenSigDeltaValue" SG_ 2151415808 LftLnChgThrtHptStRq 1;
BA_ "GenSigSendType" SG_ 2151415808 LftLnChgThrtHptStRq 12;
BA_ "SignalType" SG_ 2151415808 LftLnChgThrtHptStRq "UNM";
BA_ "SignalLongName" SG_ 2151415808 LftLnChgThrtHptStRq "Left Lane Change Threat Haptic Seat Request";
BA_ "VNSigAllNodes" SG_ 2151415808 LftLnChgThrtHptStRq 1;
BA_ "GenSigDeltaValue" SG_ 2151415808 LDWRghtHptcStRqSN 1;
BA_ "GenSigSendType" SG_ 2151415808 LDWRghtHptcStRqSN 12;
BA_ "SignalType" SG_ 2151415808 LDWRghtHptcStRqSN "UNM";
BA_ "SignalLongName" SG_ 2151415808 LDWRghtHptcStRqSN "Lane Departure Warning Right Haptic Seat Request Sequence Number";
BA_ "VNSigAllNodes" SG_ 2151415808 LDWRghtHptcStRqSN 1;
BA_ "GenSigDeltaValue" SG_ 2151415808 LDWRghtHptcStRq 1;
BA_ "GenSigSendType" SG_ 2151415808 LDWRghtHptcStRq 12;
BA_ "SignalType" SG_ 2151415808 LDWRghtHptcStRq "UNM";
BA_ "SignalLongName" SG_ 2151415808 LDWRghtHptcStRq "Lane Departure Warning Right Haptic Seat Request";
BA_ "VNSigAllNodes" SG_ 2151415808 LDWRghtHptcStRq 1;
BA_ "GenSigDeltaValue" SG_ 2151415808 LDWLftHptcStRqSN 1;
BA_ "GenSigSendType" SG_ 2151415808 LDWLftHptcStRqSN 12;
BA_ "SignalType" SG_ 2151415808 LDWLftHptcStRqSN "UNM";
BA_ "SignalLongName" SG_ 2151415808 LDWLftHptcStRqSN "Lane Departure Warning Left Haptic Seat Request Sequence Number";
BA_ "VNSigAllNodes" SG_ 2151415808 LDWLftHptcStRqSN 1;
BA_ "GenSigDeltaValue" SG_ 2151415808 LDWLftHptcStRq 1;
BA_ "GenSigSendType" SG_ 2151415808 LDWLftHptcStRq 12;
BA_ "SignalType" SG_ 2151415808 LDWLftHptcStRq "UNM";
BA_ "SignalLongName" SG_ 2151415808 LDWLftHptcStRq "Lane Departure Warning Left Haptic Seat Request";
BA_ "VNSigAllNodes" SG_ 2151415808 LDWLftHptcStRq 1;
BA_ "GenSigDeltaValue" SG_ 2151350272 APAIconFilPctRq 1;
BA_ "GenSigSendType" SG_ 2151350272 APAIconFilPctRq 12;
BA_ "SignalType" SG_ 2151350272 APAIconFilPctRq "UNM";
BA_ "SignalLongName" SG_ 2151350272 APAIconFilPctRq "Advanced Park Assist Icon Fill Percent Request";
BA_ "VNSigAllNodes" SG_ 2151350272 APAIconFilPctRq 1;
BA_ "GenSigSendType" SG_ 2151350272 APAIconDispRq 10;
BA_ "SignalType" SG_ 2151350272 APAIconDispRq "ENM";
BA_ "SignalLongName" SG_ 2151350272 APAIconDispRq "Advanced Park Assist Icon Display Request";
BA_ "VNSigAllNodes" SG_ 2151350272 APAIconDispRq 1;
BA_ "GenSigDeltaValue" SG_ 2151350272 FPAHptcStVbnRqSeqN 1;
BA_ "GenSigSendType" SG_ 2151350272 FPAHptcStVbnRqSeqN 12;
BA_ "SignalType" SG_ 2151350272 FPAHptcStVbnRqSeqN "UNM";
BA_ "SignalLongName" SG_ 2151350272 FPAHptcStVbnRqSeqN "Front Park Assist Haptic Seat Vibration Request Sequence Number";
BA_ "VNSigAllNodes" SG_ 2151350272 FPAHptcStVbnRqSeqN 1;
BA_ "GenSigDeltaValue" SG_ 2151350272 FPAHptcStVbnReq 1;
BA_ "GenSigSendType" SG_ 2151350272 FPAHptcStVbnReq 12;
BA_ "SignalType" SG_ 2151350272 FPAHptcStVbnReq "UNM";
BA_ "SignalLongName" SG_ 2151350272 FPAHptcStVbnReq "Front Park Assist Haptic Seat Vibration Request";
BA_ "VNSigAllNodes" SG_ 2151350272 FPAHptcStVbnReq 1;
BA_ "GenSigDeltaValue" SG_ 2151333888 RPAHptcStVbRqSeqN 1;
BA_ "GenSigSendType" SG_ 2151333888 RPAHptcStVbRqSeqN 12;
BA_ "SignalType" SG_ 2151333888 RPAHptcStVbRqSeqN "UNM";
BA_ "SignalLongName" SG_ 2151333888 RPAHptcStVbRqSeqN "Rear Parking Assist Haptic Seat Vibration Request Sequence Number";
BA_ "VNSigAllNodes" SG_ 2151333888 RPAHptcStVbRqSeqN 1;
BA_ "GenSigDeltaValue" SG_ 2151333888 RPAHptcStVbnReq 1;
BA_ "GenSigSendType" SG_ 2151333888 RPAHptcStVbnReq 12;
BA_ "SignalType" SG_ 2151333888 RPAHptcStVbnReq "UNM";
BA_ "SignalLongName" SG_ 2151333888 RPAHptcStVbnReq "Rear Parking Assist Haptic Seat Vibration Request";
BA_ "VNSigAllNodes" SG_ 2151333888 RPAHptcStVbnReq 1;
BA_ "GenSigSendType" SG_ 2151522304 BrkPdLfSysDrvrRq 10;
BA_ "GenSigSendOnInit" SG_ 2151522304 BrkPdLfSysDrvrRq 1;
BA_ "SignalType" SG_ 2151522304 BrkPdLfSysDrvrRq "ENM";
BA_ "SignalLongName" SG_ 2151522304 BrkPdLfSysDrvrRq "Brake Pad Life System Driver Request";
BA_ "VNSigAllNodes" SG_ 2151522304 BrkPdLfSysDrvrRq 1;
BA_ "GenSigSendType" SG_ 2151522304 LnchCtrlRelLnLockReqd 10;
BA_ "SignalType" SG_ 2151522304 LnchCtrlRelLnLockReqd "BLN";
BA_ "SignalLongName" SG_ 2151522304 LnchCtrlRelLnLockReqd "Launch Control Release Line Lock Requested";
BA_ "VNSigAllNodes" SG_ 2151522304 LnchCtrlRelLnLockReqd 1;
BA_ "GenSigSendType" SG_ 2151522304 TCSTmpDsblReqConf 10;
BA_ "SignalType" SG_ 2151522304 TCSTmpDsblReqConf "ENM";
BA_ "SignalLongName" SG_ 2151522304 TCSTmpDsblReqConf "Traction Control System Temporary Disable Request Confirmation";
BA_ "VNSigAllNodes" SG_ 2151522304 TCSTmpDsblReqConf 1;
BA_ "GenSigSendType" SG_ 2151522304 ElEngyEconAvgRstRq 10;
BA_ "SignalType" SG_ 2151522304 ElEngyEconAvgRstRq "BLN";
BA_ "SignalLongName" SG_ 2151522304 ElEngyEconAvgRstRq "Electrical Energy Economy Average Reset Requested";
BA_ "VNSigAllNodes" SG_ 2151522304 ElEngyEconAvgRstRq 1;
BA_ "GenSigSendType" SG_ 2151522304 FuelFltLfRstRqd 10;
BA_ "GenSigSendOnInit" SG_ 2151522304 FuelFltLfRstRqd 1;
BA_ "SignalType" SG_ 2151522304 FuelFltLfRstRqd "BLN";
BA_ "SignalLongName" SG_ 2151522304 FuelFltLfRstRqd "Fuel Filter Life Reset Requested";
BA_ "VNSigAllNodes" SG_ 2151522304 FuelFltLfRstRqd 1;
BA_ "GenSigSendType" SG_ 2150629376 CVSysFlrIO 10;
BA_ "SignalType" SG_ 2150629376 CVSysFlrIO "BLN";
BA_ "SignalLongName" SG_ 2150629376 CVSysFlrIO "ControVento System Failure Indication On";
BA_ "VNSigAllNodes" SG_ 2150629376 CVSysFlrIO 1;
BA_ "SignalType" SG_ 2155929600 DslExhFldDiagWrnIdRq "ENM";
BA_ "SignalLongName" SG_ 2155929600 DslExhFldDiagWrnIdRq "Diesel Exhaust Fluid System Diagnostic Warning Indication Request";
BA_ "VNSigAllNodes" SG_ 2155929600 DslExhFldDiagWrnIdRq 1;
BA_ "SignalType" SG_ 2155929600 DslExhFluidDistTIndcmt "UNM";
BA_ "SignalLongName" SG_ 2155929600 DslExhFluidDistTIndcmt "Diesel Exhaust Fluid Distance to Inducement";
BA_ "VNSigAllNodes" SG_ 2155929600 DslExhFluidDistTIndcmt 1;
BA_ "SignalType" SG_ 2155929600 DEFWVSL_S3SpdLmt "UNM";
BA_ "PacketOrder" SG_ 2155929600 DEFWVSL_S3SpdLmt 3;
BA_ "SignalLongName" SG_ 2155929600 DEFWVSL_S3SpdLmt "Diesel Exhaust Fluid Warning Vehicle Speed Limit : Stage 3 Vehicle Speed Limit";
BA_ "VNSigAllNodes" SG_ 2155929600 DEFWVSL_S3SpdLmt 1;
BA_ "SignalType" SG_ 2155929600 DEFWVSL_S2SpdLmt "UNM";
BA_ "PacketOrder" SG_ 2155929600 DEFWVSL_S2SpdLmt 2;
BA_ "SignalLongName" SG_ 2155929600 DEFWVSL_S2SpdLmt "Diesel Exhaust Fluid Warning Vehicle Speed Limit : Stage 2 Vehicle Speed Limit";
BA_ "VNSigAllNodes" SG_ 2155929600 DEFWVSL_S2SpdLmt 1;
BA_ "SignalType" SG_ 2155929600 DEFWVSL_S1SpdLmt "UNM";
BA_ "PacketOrder" SG_ 2155929600 DEFWVSL_S1SpdLmt 1;
BA_ "SignalLongName" SG_ 2155929600 DEFWVSL_S1SpdLmt "Diesel Exhaust Fluid Warning Vehicle Speed Limit : Stage 1 Vehicle Speed Limit";
BA_ "VNSigAllNodes" SG_ 2155929600 DEFWVSL_S1SpdLmt 1;
BA_ "SignalType" SG_ 2155929600 DslExFldTpWrngIndRq "ENM";
BA_ "SignalLongName" SG_ 2155929600 DslExFldTpWrngIndRq "Diesel Exhaust Fluid Tampering Warning Indication Request";
BA_ "VNSigAllNodes" SG_ 2155929600 DslExFldTpWrngIndRq 1;
BA_ "SignalType" SG_ 2155929600 DslExhFldQlyWrngIReq "ENM";
BA_ "SignalLongName" SG_ 2155929600 DslExhFldQlyWrngIReq "Diesel Exhaust Fluid Quality Warning Indication Request";
BA_ "VNSigAllNodes" SG_ 2155929600 DslExhFldQlyWrngIReq 1;
BA_ "SignalType" SG_ 2155929600 DslExhFldWrngIdRqER "ENM";
BA_ "SignalLongName" SG_ 2155929600 DslExhFldWrngIdRqER "Diesel Exhaust Fluid Level Warning Indication Request Extended Range";
BA_ "VNSigAllNodes" SG_ 2155929600 DslExhFldWrngIdRqER 1;
BA_ "SignalType" SG_ 2155929600 DslExFldCnWrngIndRq "ENM";
BA_ "SignalLongName" SG_ 2155929600 DslExFldCnWrngIndRq "Diesel Exhaust Fluid Consumption Monitoring Warning Indication Request";
BA_ "VNSigAllNodes" SG_ 2155929600 DslExFldCnWrngIndRq 1;
BA_ "SignalType" SG_ 2155929600 DslExNxEmWrngIndRq "ENM";
BA_ "SignalLongName" SG_ 2155929600 DslExNxEmWrngIndRq "Diesel Exhaust NOx Emissions Too High Warning Indication Request";
BA_ "VNSigAllNodes" SG_ 2155929600 DslExNxEmWrngIndRq 1;
BA_ "GenSigSendType" SG_ 2154741760 RSAPrsnt 10;
BA_ "GenSigSendOnInit" SG_ 2154741760 RSAPrsnt 2;
BA_ "VNSigInfotainment" SG_ 2154741760 RSAPrsnt 1;
BA_ "SignalType" SG_ 2154741760 RSAPrsnt "BLN";
BA_ "SignalLongName" SG_ 2154741760 RSAPrsnt "Rear Seat Audio Present";
BA_ "VNSigAllNodes" SG_ 2154741760 RSAPrsnt 1;
BA_ "GenSigSendType" SG_ 2154807296 ESCMHiEleclLdReqAct 10;
BA_ "SignalType" SG_ 2154807296 ESCMHiEleclLdReqAct "BLN";
BA_ "SignalLongName" SG_ 2154807296 ESCMHiEleclLdReqAct "Energy Storage Control Module High Electrical Load Request Active";
BA_ "VNSigAllNodes" SG_ 2154807296 ESCMHiEleclLdReqAct 1;
BA_ "GenSigSendType" SG_ 2154807296 TnDrvStBltShftIntrlkCsStAvl 10;
BA_ "GenSigSendOnInit" SG_ 2154807296 TnDrvStBltShftIntrlkCsStAvl 2;
BA_ "SignalType" SG_ 2154807296 TnDrvStBltShftIntrlkCsStAvl "BLN";
BA_ "SignalLongName" SG_ 2154807296 TnDrvStBltShftIntrlkCsStAvl "Teen Driver Seat Belt Shift Interlock Customization Setting Available";
BA_ "VNSigAllNodes" SG_ 2154807296 TnDrvStBltShftIntrlkCsStAvl 1;
BA_ "GenSigSendType" SG_ 2154807296 TnDrvStBltShftIntrlkCrStVal 10;
BA_ "GenSigSendOnInit" SG_ 2154807296 TnDrvStBltShftIntrlkCrStVal 2;
BA_ "SignalType" SG_ 2154807296 TnDrvStBltShftIntrlkCrStVal "ENM";
BA_ "SignalLongName" SG_ 2154807296 TnDrvStBltShftIntrlkCrStVal "Teen Driver Seat Belt Shift Interlock Customization Current Setting Value";
BA_ "VNSigAllNodes" SG_ 2154807296 TnDrvStBltShftIntrlkCrStVal 1;
BA_ "GenSigSendType" SG_ 2154807296 StBltShftIntrlkCsStAvl 10;
BA_ "GenSigSendOnInit" SG_ 2154807296 StBltShftIntrlkCsStAvl 2;
BA_ "SignalType" SG_ 2154807296 StBltShftIntrlkCsStAvl "BLN";
BA_ "SignalLongName" SG_ 2154807296 StBltShftIntrlkCsStAvl "Seat Belt Shift Interlock Customization Setting Available";
BA_ "VNSigAllNodes" SG_ 2154807296 StBltShftIntrlkCsStAvl 1;
BA_ "GenSigSendType" SG_ 2154807296 StBltShftIntrlkCsCrStVal 10;
BA_ "GenSigSendOnInit" SG_ 2154807296 StBltShftIntrlkCsCrStVal 2;
BA_ "SignalType" SG_ 2154807296 StBltShftIntrlkCsCrStVal "ENM";
BA_ "SignalLongName" SG_ 2154807296 StBltShftIntrlkCsCrStVal "Seat Belt Shift Interlock Customization Current Setting Value";
BA_ "VNSigAllNodes" SG_ 2154807296 StBltShftIntrlkCsCrStVal 1;
BA_ "GenSigSendType" SG_ 2154807296 EASSI_UnsdRsrvd2 10;
BA_ "SignalType" SG_ 2154807296 EASSI_UnsdRsrvd2 "BLN";
BA_ "PacketOrder" SG_ 2154807296 EASSI_UnsdRsrvd2 7;
BA_ "SignalLongName" SG_ 2154807296 EASSI_UnsdRsrvd2 "Engine Auto Start Stop Information : Unused and Reserved 2";
BA_ "VNSigAllNodes" SG_ 2154807296 EASSI_UnsdRsrvd2 1;
BA_ "GenSigSendType" SG_ 2154807296 EASSI_StlDetd 10;
BA_ "SignalType" SG_ 2154807296 EASSI_StlDetd "BLN";
BA_ "PacketOrder" SG_ 2154807296 EASSI_StlDetd 5;
BA_ "SignalLongName" SG_ 2154807296 EASSI_StlDetd "Engine Auto Start Stop Information : Stall Detected";
BA_ "VNSigAllNodes" SG_ 2154807296 EASSI_StlDetd 1;
BA_ "GenSigSendType" SG_ 2154807296 EASSI_TrqDetd 10;
BA_ "SignalType" SG_ 2154807296 EASSI_TrqDetd "BLN";
BA_ "PacketOrder" SG_ 2154807296 EASSI_TrqDetd 4;
BA_ "SignalLongName" SG_ 2154807296 EASSI_TrqDetd "Engine Auto Start Stop Information : Torque Detected";
BA_ "VNSigAllNodes" SG_ 2154807296 EASSI_TrqDetd 1;
BA_ "GenSigSendType" SG_ 2154807296 EASSI_FuelReqOn 10;
BA_ "SignalType" SG_ 2154807296 EASSI_FuelReqOn "BLN";
BA_ "PacketOrder" SG_ 2154807296 EASSI_FuelReqOn 3;
BA_ "SignalLongName" SG_ 2154807296 EASSI_FuelReqOn "Engine Auto Start Stop Information : Fuel Requested On";
BA_ "VNSigAllNodes" SG_ 2154807296 EASSI_FuelReqOn 1;
BA_ "GenSigSendType" SG_ 2154807296 EASSI_StrtTyp 10;
BA_ "SignalType" SG_ 2154807296 EASSI_StrtTyp "ENM";
BA_ "PacketOrder" SG_ 2154807296 EASSI_StrtTyp 2;
BA_ "SignalLongName" SG_ 2154807296 EASSI_StrtTyp "Engine Auto Start Stop Information : Start Type";
BA_ "VNSigAllNodes" SG_ 2154807296 EASSI_StrtTyp 1;
BA_ "GenSigSendType" SG_ 2154807296 EASSI_StrtStpSt 10;
BA_ "SignalType" SG_ 2154807296 EASSI_StrtStpSt "ENM";
BA_ "PacketOrder" SG_ 2154807296 EASSI_StrtStpSt 1;
BA_ "SignalLongName" SG_ 2154807296 EASSI_StrtStpSt "Engine Auto Start Stop Information : Start Stop State";
BA_ "VNSigAllNodes" SG_ 2154807296 EASSI_StrtStpSt 1;
BA_ "GenSigSendType" SG_ 2154807296 EASSI_TorqDetdIndet 10;
BA_ "SignalType" SG_ 2154807296 EASSI_TorqDetdIndet "BLN";
BA_ "PacketOrder" SG_ 2154807296 EASSI_TorqDetdIndet 6;
BA_ "SignalLongName" SG_ 2154807296 EASSI_TorqDetdIndet "Engine Auto Start Stop Information : Torque Detected Indeterminate";
BA_ "VNSigAllNodes" SG_ 2154807296 EASSI_TorqDetdIndet 1;
BA_ "GenSigSendType" SG_ 2154807296 EngAutoStpNotProb 10;
BA_ "SignalType" SG_ 2154807296 EngAutoStpNotProb "BLN";
BA_ "SignalLongName" SG_ 2154807296 EngAutoStpNotProb "Engine Auto Stop Not Probable";
BA_ "VNSigAllNodes" SG_ 2154807296 EngAutoStpNotProb 1;
BA_ "GenSigSendType" SG_ 2154807296 AFLMnu3CstStAvl 10;
BA_ "GenSigSendOnInit" SG_ 2154807296 AFLMnu3CstStAvl 2;
BA_ "SignalType" SG_ 2154807296 AFLMnu3CstStAvl "BLN";
BA_ "SignalLongName" SG_ 2154807296 AFLMnu3CstStAvl "Adaptive Forward Lighting Menu 3 Customization Setting Available";
BA_ "VNSigAllNodes" SG_ 2154807296 AFLMnu3CstStAvl 1;
BA_ "GenSigSendType" SG_ 2154807296 AFLMnu2CstStAvl 10;
BA_ "GenSigSendOnInit" SG_ 2154807296 AFLMnu2CstStAvl 2;
BA_ "SignalType" SG_ 2154807296 AFLMnu2CstStAvl "BLN";
BA_ "SignalLongName" SG_ 2154807296 AFLMnu2CstStAvl "Adaptive Forward Lighting Menu 2 Customization Setting Available";
BA_ "VNSigAllNodes" SG_ 2154807296 AFLMnu2CstStAvl 1;
BA_ "GenSigSendType" SG_ 2154807296 AFLGPSMnu2CstStAvl 10;
BA_ "GenSigSendOnInit" SG_ 2154807296 AFLGPSMnu2CstStAvl 2;
BA_ "SignalType" SG_ 2154807296 AFLGPSMnu2CstStAvl "BLN";
BA_ "SignalLongName" SG_ 2154807296 AFLGPSMnu2CstStAvl "Adaptive Forward Lighting With GPS Menu 2 Customization Setting Avail";
BA_ "VNSigAllNodes" SG_ 2154807296 AFLGPSMnu2CstStAvl 1;
BA_ "GenSigSendType" SG_ 2154807296 AFLGPSCstStAvl 10;
BA_ "GenSigSendOnInit" SG_ 2154807296 AFLGPSCstStAvl 2;
BA_ "SignalType" SG_ 2154807296 AFLGPSCstStAvl "BLN";
BA_ "SignalLongName" SG_ 2154807296 AFLGPSCstStAvl "Adaptive Forward Lighting With GPS Customization Setting Available";
BA_ "VNSigAllNodes" SG_ 2154807296 AFLGPSCstStAvl 1;
BA_ "GenSigSendType" SG_ 2154807296 AFLGPSCstCrStVal 10;
BA_ "GenSigSendOnInit" SG_ 2154807296 AFLGPSCstCrStVal 2;
BA_ "SignalType" SG_ 2154807296 AFLGPSCstCrStVal "ENM";
BA_ "SignalLongName" SG_ 2154807296 AFLGPSCstCrStVal "Adaptive Forward Lighting With GPS Customization Current Setting Value";
BA_ "VNSigAllNodes" SG_ 2154807296 AFLGPSCstCrStVal 1;
BA_ "GenSigSendType" SG_ 2154807296 AFLCstStAvl 10;
BA_ "GenSigSendOnInit" SG_ 2154807296 AFLCstStAvl 2;
BA_ "SignalType" SG_ 2154807296 AFLCstStAvl "BLN";
BA_ "SignalLongName" SG_ 2154807296 AFLCstStAvl "Adaptive Forward Lighting Customization Setting Available";
BA_ "VNSigAllNodes" SG_ 2154807296 AFLCstStAvl 1;
BA_ "GenSigSendType" SG_ 2154807296 AFLCstCrStVal 10;
BA_ "GenSigSendOnInit" SG_ 2154807296 AFLCstCrStVal 2;
BA_ "SignalType" SG_ 2154807296 AFLCstCrStVal "ENM";
BA_ "SignalLongName" SG_ 2154807296 AFLCstCrStVal "Adaptive Forward Lighting Customization Current Setting Value";
BA_ "VNSigAllNodes" SG_ 2154807296 AFLCstCrStVal 1;
BA_ "GenSigSendType" SG_ 2151079936 PDIMPrsnt 10;
BA_ "GenSigSendOnInit" SG_ 2151079936 PDIMPrsnt 2;
BA_ "VNSigInfotainment" SG_ 2151079936 PDIMPrsnt 1;
BA_ "SignalType" SG_ 2151079936 PDIMPrsnt "BLN";
BA_ "SignalLongName" SG_ 2151079936 PDIMPrsnt "Preferred Device Interface Module Present";
BA_ "GenSigStartValue" SG_ 2151079936 PDIMPrsnt 1;
BA_ "VNSigAllNodes" SG_ 2151079936 PDIMPrsnt 1;
BA_ "GenSigSendType" SG_ 2155364352 CstmrUsblSOCV 10;
BA_ "GenSigSendOnInit" SG_ 2155364352 CstmrUsblSOCV 1;
BA_ "VNSigInfotainment" SG_ 2155364352 CstmrUsblSOCV 1;
BA_ "SignalType" SG_ 2155364352 CstmrUsblSOCV "ENM";
BA_ "SignalLongName" SG_ 2155364352 CstmrUsblSOCV "Customer Usable State of Charge Validity";
BA_ "VNSigAllNodes" SG_ 2155364352 CstmrUsblSOCV 1;
BA_ "GenSigDeltaValue" SG_ 2155364352 InstDrvEff 1;
BA_ "GenSigSendType" SG_ 2155364352 InstDrvEff 12;
BA_ "GenSigSendOnInit" SG_ 2155364352 InstDrvEff 1;
BA_ "VNSigInfotainment" SG_ 2155364352 InstDrvEff 1;
BA_ "SignalType" SG_ 2155364352 InstDrvEff "SNM";
BA_ "SignalLongName" SG_ 2155364352 InstDrvEff "Instantaneous Drive Efficiency";
BA_ "VNSigAllNodes" SG_ 2155364352 InstDrvEff 1;
BA_ "GenSigSendType" SG_ 2155364352 BattCntrlPrcssrVDA 10;
BA_ "GenSigSendOnInit" SG_ 2155364352 BattCntrlPrcssrVDA 1;
BA_ "VNSigInfotainment" SG_ 2155364352 BattCntrlPrcssrVDA 1;
BA_ "SignalType" SG_ 2155364352 BattCntrlPrcssrVDA "ENM";
BA_ "SignalLongName" SG_ 2155364352 BattCntrlPrcssrVDA "Battery Control Processor Virtual Device Availability";
BA_ "GenSigStartValue" SG_ 2155364352 BattCntrlPrcssrVDA 1;
BA_ "VNSigAllNodes" SG_ 2155364352 BattCntrlPrcssrVDA 1;
BA_ "GenSigSendType" SG_ 2155364352 JmpStrtStat 10;
BA_ "GenSigSendOnInit" SG_ 2155364352 JmpStrtStat 1;
BA_ "VNSigInfotainment" SG_ 2155364352 JmpStrtStat 1;
BA_ "SignalType" SG_ 2155364352 JmpStrtStat "ENM";
BA_ "SignalLongName" SG_ 2155364352 JmpStrtStat "Jump Start Status";
BA_ "VNSigAllNodes" SG_ 2155364352 JmpStrtStat 1;
BA_ "GenSigDeltaValue" SG_ 2155364352 CstmrUsblSOC 1;
BA_ "GenSigSendType" SG_ 2155364352 CstmrUsblSOC 12;
BA_ "GenSigSendOnInit" SG_ 2155364352 CstmrUsblSOC 1;
BA_ "VNSigInfotainment" SG_ 2155364352 CstmrUsblSOC 1;
BA_ "SignalType" SG_ 2155364352 CstmrUsblSOC "UNM";
BA_ "SignalLongName" SG_ 2155364352 CstmrUsblSOC "Customer Usable State of Charge";
BA_ "VNSigAllNodes" SG_ 2155364352 CstmrUsblSOC 1;
BA_ "GenSigSendType" SG_ 2155364352 SvcHybridSysIO 10;
BA_ "GenSigSendOnInit" SG_ 2155364352 SvcHybridSysIO 1;
BA_ "VNSigInfotainment" SG_ 2155364352 SvcHybridSysIO 1;
BA_ "SignalType" SG_ 2155364352 SvcHybridSysIO "BLN";
BA_ "SignalLongName" SG_ 2155364352 SvcHybridSysIO "Service Hybrid System Indication On";
BA_ "VNSigAllNodes" SG_ 2155364352 SvcHybridSysIO 1;
BA_ "GenSigSendType" SG_ 2155364352 HybMdDisp 10;
BA_ "GenSigSendOnInit" SG_ 2155364352 HybMdDisp 1;
BA_ "VNSigInfotainment" SG_ 2155364352 HybMdDisp 1;
BA_ "SignalType" SG_ 2155364352 HybMdDisp "ENM";
BA_ "SignalLongName" SG_ 2155364352 HybMdDisp "Hybrid Mode Display";
BA_ "VNSigAllNodes" SG_ 2155364352 HybMdDisp 1;
BA_ "GenSigDeltaValue" SG_ 2155364352 ClntCrcFlwRtEst 1;
BA_ "GenSigSendType" SG_ 2155364352 ClntCrcFlwRtEst 12;
BA_ "GenSigSendOnInit" SG_ 2155364352 ClntCrcFlwRtEst 1;
BA_ "VNSigInfotainment" SG_ 2155364352 ClntCrcFlwRtEst 1;
BA_ "SignalType" SG_ 2155364352 ClntCrcFlwRtEst "UNM";
BA_ "SignalLongName" SG_ 2155364352 ClntCrcFlwRtEst "Coolant Circulation Flow Rate Estimated";
BA_ "VNSigAllNodes" SG_ 2155364352 ClntCrcFlwRtEst 1;
BA_ "GenSigSendType" SG_ 2154979328 FrntStVoltBstModReq 10;
BA_ "SignalType" SG_ 2154979328 FrntStVoltBstModReq "BLN";
BA_ "SignalLongName" SG_ 2154979328 FrntStVoltBstModReq "Front Seat Voltage Boost Mode Requested";
BA_ "VNSigAllNodes" SG_ 2154979328 FrntStVoltBstModReq 1;
BA_ "GenSigSendType" SG_ 2155282432 RrStVoltBstModReq 10;
BA_ "SignalType" SG_ 2155282432 RrStVoltBstModReq "BLN";
BA_ "SignalLongName" SG_ 2155282432 RrStVoltBstModReq "Rear Seat Voltage Boost Mode Requested";
BA_ "VNSigAllNodes" SG_ 2155282432 RrStVoltBstModReq 1;
BA_ "SignalType" SG_ 2151505920 PTExPrtclFltManRgnDispPrsnt "BLN";
BA_ "SignalLongName" SG_ 2151505920 PTExPrtclFltManRgnDispPrsnt "Powertrain Exhaust Particle Filter Manual Regen Display Present";
BA_ "VNSigAllNodes" SG_ 2151505920 PTExPrtclFltManRgnDispPrsnt 1;
BA_ "SignalType" SG_ 2151505920 Trp2OdomtrV "ENM";
BA_ "SignalLongName" SG_ 2151505920 Trp2OdomtrV "Trip 2 Odometer Validity";
BA_ "VNSigAllNodes" SG_ 2151505920 Trp2OdomtrV 1;
BA_ "GenSigDeltaValue" SG_ 2151505920 Trp2Odomtr 1;
BA_ "SignalType" SG_ 2151505920 Trp2Odomtr "UNM";
BA_ "SignalLongName" SG_ 2151505920 Trp2Odomtr "Trip 2 Odometer";
BA_ "VNSigAllNodes" SG_ 2151505920 Trp2Odomtr 1;
BA_ "SignalType" SG_ 2151505920 Trp1OdomtrV "ENM";
BA_ "SignalLongName" SG_ 2151505920 Trp1OdomtrV "Trip 1 Odometer Validity";
BA_ "VNSigAllNodes" SG_ 2151505920 Trp1OdomtrV 1;
BA_ "GenSigDeltaValue" SG_ 2151505920 Trp1Odomtr 1;
BA_ "SignalType" SG_ 2151505920 Trp1Odomtr "UNM";
BA_ "SignalLongName" SG_ 2151505920 Trp1Odomtr "Trip 1 Odometer";
BA_ "VNSigAllNodes" SG_ 2151505920 Trp1Odomtr 1;
BA_ "GenSigSendType" SG_ 2151505920 PTExPrtclFltManRgnRqd 10;
BA_ "SignalType" SG_ 2151505920 PTExPrtclFltManRgnRqd "BLN";
BA_ "SignalLongName" SG_ 2151505920 PTExPrtclFltManRgnRqd "Powertrain Exhaust Particle Filter Manual Regeneration Requested";
BA_ "VNSigAllNodes" SG_ 2151505920 PTExPrtclFltManRgnRqd 1;
BA_ "GenSigSendType" SG_ 2151505920 AutoMdSpdLmtCnfrmd 10;
BA_ "SignalType" SG_ 2151505920 AutoMdSpdLmtCnfrmd "BLN";
BA_ "SignalLongName" SG_ 2151505920 AutoMdSpdLmtCnfrmd "Auto Mode Speed Limit Confirmed";
BA_ "VNSigAllNodes" SG_ 2151505920 AutoMdSpdLmtCnfrmd 1;
BA_ "GenSigSendType" SG_ 2151505920 ACCSettingType 10;
BA_ "SignalType" SG_ 2151505920 ACCSettingType "ENM";
BA_ "SignalLongName" SG_ 2151505920 ACCSettingType "Adaptive Cruise Control Setting Type";
BA_ "VNSigAllNodes" SG_ 2151505920 ACCSettingType 1;
BA_ "GenSigSendType" SG_ 2151505920 TrlrBrkDsplyAct 10;
BA_ "GenSigSendOnInit" SG_ 2151505920 TrlrBrkDsplyAct 1;
BA_ "SignalType" SG_ 2151505920 TrlrBrkDsplyAct "BLN";
BA_ "SignalLongName" SG_ 2151505920 TrlrBrkDsplyAct "Trailer Brake Display Active";
BA_ "VNSigAllNodes" SG_ 2151505920 TrlrBrkDsplyAct 1;
BA_ "GenSigSendType" SG_ 2151505920 SpdCurvAdvSysEnbld 10;
BA_ "SignalType" SG_ 2151505920 SpdCurvAdvSysEnbld "BLN";
BA_ "SignalLongName" SG_ 2151505920 SpdCurvAdvSysEnbld "Speed and Curve Advisory System Enabled";
BA_ "VNSigAllNodes" SG_ 2151505920 SpdCurvAdvSysEnbld 1;
BA_ "SignalType" SG_ 2155896832 FuelAlcoholCompV "ENM";
BA_ "SignalLongName" SG_ 2155896832 FuelAlcoholCompV "Fuel Alcohol Composition Validity";
BA_ "VNSigAllNodes" SG_ 2155896832 FuelAlcoholCompV 1;
BA_ "SignalType" SG_ 2155896832 FuelAlchlCompAdptnPrg "BLN";
BA_ "SignalLongName" SG_ 2155896832 FuelAlchlCompAdptnPrg "Fuel Alcohol Composition Adaptation in Progress";
BA_ "VNSigAllNodes" SG_ 2155896832 FuelAlchlCompAdptnPrg 1;
BA_ "SignalType" SG_ 2155896832 FuelAlcoholComp "UNM";
BA_ "SignalLongName" SG_ 2155896832 FuelAlcoholComp "Fuel Alcohol Composition";
BA_ "VNSigAllNodes" SG_ 2155896832 FuelAlcoholComp 1;
BA_ "SignalType" SG_ 2155896832 FuelMdStat "ENM";
BA_ "SignalLongName" SG_ 2155896832 FuelMdStat "Fuel Mode Status";
BA_ "VNSigAllNodes" SG_ 2155896832 FuelMdStat 1;
BA_ "SignalType" SG_ 2155896832 FuelTotCapTnk2 "UNM";
BA_ "SignalLongName" SG_ 2155896832 FuelTotCapTnk2 "Fuel Total Capacity Tank 2";
BA_ "VNSigAllNodes" SG_ 2155896832 FuelTotCapTnk2 1;
BA_ "SignalType" SG_ 2155896832 FlLvlTank2PctV "ENM";
BA_ "SignalLongName" SG_ 2155896832 FlLvlTank2PctV "Fuel Level Tank 2 Percent Validity";
BA_ "VNSigAllNodes" SG_ 2155896832 FlLvlTank2PctV 1;
BA_ "SignalType" SG_ 2155896832 FlLvlTank2Pct "UNM";
BA_ "SignalLongName" SG_ 2155896832 FlLvlTank2Pct "Fuel Level Tank 2 Percent";
BA_ "VNSigAllNodes" SG_ 2155896832 FlLvlTank2Pct 1;
BA_ "SignalType" SG_ 2155896832 AltFuelPHeatAct "BLN";
BA_ "SignalLongName" SG_ 2155896832 AltFuelPHeatAct "Alternative Fuel Pre-heating Active";
BA_ "VNSigAllNodes" SG_ 2155896832 AltFuelPHeatAct 1;
BA_ "SignalType" SG_ 2155896832 AltFuelMdReqDndIO "BLN";
BA_ "SignalLongName" SG_ 2155896832 AltFuelMdReqDndIO "Alternative Fuel Mode Request Denied Indication On";
BA_ "VNSigAllNodes" SG_ 2155896832 AltFuelMdReqDndIO 1;
BA_ "SignalType" SG_ 2155896832 AltFuelLvlLo "BLN";
BA_ "SignalLongName" SG_ 2155896832 AltFuelLvlLo "Alternative Fuel Level Low";
BA_ "VNSigAllNodes" SG_ 2155896832 AltFuelLvlLo 1;
BA_ "SignalType" SG_ 2155896832 AltFuelAccWrnngAct "BLN";
BA_ "SignalLongName" SG_ 2155896832 AltFuelAccWrnngAct "Alternative Fuel Acceleration Warning Active";
BA_ "VNSigAllNodes" SG_ 2155896832 AltFuelAccWrnngAct 1;
BA_ "GenSigSendType" SG_ 2155552768 PsvEntCmftWndRq 10;
BA_ "SignalType" SG_ 2155552768 PsvEntCmftWndRq "ENM";
BA_ "SignalLongName" SG_ 2155552768 PsvEntCmftWndRq "Passive Entry Comfort Window Request";
BA_ "VNSigAllNodes" SG_ 2155552768 PsvEntCmftWndRq 1;
BA_ "GenSigSendType" SG_ 2154496000 ShftrUnlkdBrkToShftIO 10;
BA_ "GenSigSendOnInit" SG_ 2154496000 ShftrUnlkdBrkToShftIO 2;
BA_ "SignalType" SG_ 2154496000 ShftrUnlkdBrkToShftIO "BLN";
BA_ "SignalLongName" SG_ 2154496000 ShftrUnlkdBrkToShftIO "Shifter Unlocked Brake To Shift Indication On";
BA_ "VNSigAllNodes" SG_ 2154496000 ShftrUnlkdBrkToShftIO 1;
BA_ "GenSigSendType" SG_ 2154496000 ShftrLkdBklDrvStbltIO 10;
BA_ "GenSigSendOnInit" SG_ 2154496000 ShftrLkdBklDrvStbltIO 2;
BA_ "SignalType" SG_ 2154496000 ShftrLkdBklDrvStbltIO "BLN";
BA_ "SignalLongName" SG_ 2154496000 ShftrLkdBklDrvStbltIO "Shifter Locked Buckle Driver Seatbelt Indication On";
BA_ "VNSigAllNodes" SG_ 2154496000 ShftrLkdBklDrvStbltIO 1;
BA_ "GenSigSendType" SG_ 2154496000 ShftrLkdBklPsnStbltIO 10;
BA_ "GenSigSendOnInit" SG_ 2154496000 ShftrLkdBklPsnStbltIO 2;
BA_ "SignalType" SG_ 2154496000 ShftrLkdBklPsnStbltIO "BLN";
BA_ "SignalLongName" SG_ 2154496000 ShftrLkdBklPsnStbltIO "Shifter Locked Buckle Passenger Seatbelt Indication On";
BA_ "VNSigAllNodes" SG_ 2154496000 ShftrLkdBklPsnStbltIO 1;
BA_ "GenSigSendType" SG_ 2154496000 TargaTopStateV 10;
BA_ "GenSigSendOnInit" SG_ 2154496000 TargaTopStateV 2;
BA_ "SignalType" SG_ 2154496000 TargaTopStateV "ENM";
BA_ "SignalLongName" SG_ 2154496000 TargaTopStateV "Targa Top State Validity";
BA_ "VNSigAllNodes" SG_ 2154496000 TargaTopStateV 1;
BA_ "GenSigSendType" SG_ 2154496000 TargaTopState 10;
BA_ "GenSigSendOnInit" SG_ 2154496000 TargaTopState 2;
BA_ "SignalType" SG_ 2154496000 TargaTopState "ENM";
BA_ "SignalLongName" SG_ 2154496000 TargaTopState "Targa Top State";
BA_ "VNSigAllNodes" SG_ 2154496000 TargaTopState 1;
BA_ "GenSigSendType" SG_ 2154496000 CmpSftTopMotBfrOpTrnkIO 10;
BA_ "GenSigSendOnInit" SG_ 2154496000 CmpSftTopMotBfrOpTrnkIO 2;
BA_ "SignalType" SG_ 2154496000 CmpSftTopMotBfrOpTrnkIO "BLN";
BA_ "SignalLongName" SG_ 2154496000 CmpSftTopMotBfrOpTrnkIO "Complete Soft Top Motion Before Open Trunk Indication On";
BA_ "VNSigAllNodes" SG_ 2154496000 CmpSftTopMotBfrOpTrnkIO 1;
BA_ "GenSigSendType" SG_ 2155208704 SftTpPlsDnWrngIndOn 10;
BA_ "SignalType" SG_ 2155208704 SftTpPlsDnWrngIndOn "BLN";
BA_ "SignalLongName" SG_ 2155208704 SftTpPlsDnWrngIndOn "Soft Top Pulse Down Warning Indication On";
BA_ "VNSigAllNodes" SG_ 2155208704 SftTpPlsDnWrngIndOn 1;
BA_ "GenSigSendType" SG_ 2155208704 SftTpPlsDnSrtdIndOn 10;
BA_ "SignalType" SG_ 2155208704 SftTpPlsDnSrtdIndOn "BLN";
BA_ "SignalLongName" SG_ 2155208704 SftTpPlsDnSrtdIndOn "Soft Top Pulse Down Started Indication On";
BA_ "VNSigAllNodes" SG_ 2155208704 SftTpPlsDnSrtdIndOn 1;
BA_ "GenSigSendType" SG_ 2155208704 VltSwAtvIndOn 10;
BA_ "SignalType" SG_ 2155208704 VltSwAtvIndOn "BLN";
BA_ "SignalLongName" SG_ 2155208704 VltSwAtvIndOn "Valet Switch Active Indication On";
BA_ "VNSigAllNodes" SG_ 2155208704 VltSwAtvIndOn 1;
BA_ "GenSigSendType" SG_ 2155208704 SftTpVltLwIO 10;
BA_ "SignalType" SG_ 2155208704 SftTpVltLwIO "BLN";
BA_ "SignalLongName" SG_ 2155208704 SftTpVltLwIO "Soft Top Voltage Low Indication On";
BA_ "VNSigAllNodes" SG_ 2155208704 SftTpVltLwIO 1;
BA_ "GenSigSendType" SG_ 2155208704 SftTpVehOvSpdIndOn 10;
BA_ "SignalType" SG_ 2155208704 SftTpVehOvSpdIndOn "BLN";
BA_ "SignalLongName" SG_ 2155208704 SftTpVehOvSpdIndOn "Soft Top Vehicle Overspeed Indication On";
BA_ "VNSigAllNodes" SG_ 2155208704 SftTpVehOvSpdIndOn 1;
BA_ "GenSigSendType" SG_ 2155208704 SftTpTneuCvrIO 10;
BA_ "SignalType" SG_ 2155208704 SftTpTneuCvrIO "BLN";
BA_ "SignalLongName" SG_ 2155208704 SftTpTneuCvrIO "Soft Top Tonneau Cover Indication On";
BA_ "VNSigAllNodes" SG_ 2155208704 SftTpTneuCvrIO 1;
BA_ "GenSigSendType" SG_ 2155208704 SftTpTmpLwIO 10;
BA_ "SignalType" SG_ 2155208704 SftTpTmpLwIO "BLN";
BA_ "SignalLongName" SG_ 2155208704 SftTpTmpLwIO "Soft Top Temperature Low Indication On";
BA_ "VNSigAllNodes" SG_ 2155208704 SftTpTmpLwIO 1;
BA_ "GenSigSendType" SG_ 2155208704 SftTpStrIO 10;
BA_ "SignalType" SG_ 2155208704 SftTpStrIO "BLN";
BA_ "SignalLongName" SG_ 2155208704 SftTpStrIO "Soft Top Storage Indication On";
BA_ "VNSigAllNodes" SG_ 2155208704 SftTpStrIO 1;
BA_ "GenSigSendType" SG_ 2155208704 SftTpRmCrgCrrIO 10;
BA_ "SignalType" SG_ 2155208704 SftTpRmCrgCrrIO "BLN";
BA_ "SignalLongName" SG_ 2155208704 SftTpRmCrgCrrIO "Soft Top Remove Cargo Carrier Indication On";
BA_ "VNSigAllNodes" SG_ 2155208704 SftTpRmCrgCrrIO 1;
BA_ "GenSigSendType" SG_ 2155208704 SftTpMnlLtchIndOn 10;
BA_ "SignalType" SG_ 2155208704 SftTpMnlLtchIndOn "BLN";
BA_ "SignalLongName" SG_ 2155208704 SftTpMnlLtchIndOn "Soft Top Manual Latch Indication On";
BA_ "VNSigAllNodes" SG_ 2155208704 SftTpMnlLtchIndOn 1;
BA_ "GenSigSendType" SG_ 2155208704 SftTpMchnOvhtIO 10;
BA_ "SignalType" SG_ 2155208704 SftTpMchnOvhtIO "BLN";
BA_ "SignalLongName" SG_ 2155208704 SftTpMchnOvhtIO "Soft Top Mechanism Overheated Indication On";
BA_ "VNSigAllNodes" SG_ 2155208704 SftTpMchnOvhtIO 1;
BA_ "GenSigSendType" SG_ 2155208704 SftTpLtcIO 10;
BA_ "SignalType" SG_ 2155208704 SftTpLtcIO "BLN";
BA_ "SignalLongName" SG_ 2155208704 SftTpLtcIO "Soft Top Latch Indication On";
BA_ "VNSigAllNodes" SG_ 2155208704 SftTpLtcIO 1;
BA_ "GenSigSendType" SG_ 2155208704 SftTpFlrIO 10;
BA_ "SignalType" SG_ 2155208704 SftTpFlrIO "BLN";
BA_ "SignalLongName" SG_ 2155208704 SftTpFlrIO "Soft Top Failure Indication On";
BA_ "VNSigAllNodes" SG_ 2155208704 SftTpFlrIO 1;
BA_ "GenSigSendType" SG_ 2155208704 SftTpAbvWrngSpdIndOn 10;
BA_ "SignalType" SG_ 2155208704 SftTpAbvWrngSpdIndOn "BLN";
BA_ "SignalLongName" SG_ 2155208704 SftTpAbvWrngSpdIndOn "Soft Top Above Warning Speed Indication On";
BA_ "VNSigAllNodes" SG_ 2155208704 SftTpAbvWrngSpdIndOn 1;
BA_ "GenSigSendType" SG_ 2155208704 FldngTpSt 10;
BA_ "GenSigSendOnInit" SG_ 2155208704 FldngTpSt 1;
BA_ "SignalType" SG_ 2155208704 FldngTpSt "ENM";
BA_ "SignalLongName" SG_ 2155208704 FldngTpSt "Folding Top State";
BA_ "VNSigAllNodes" SG_ 2155208704 FldngTpSt 1;
BA_ "GenSigSendType" SG_ 2155208704 ClsTrnkLidIO 10;
BA_ "SignalType" SG_ 2155208704 ClsTrnkLidIO "BLN";
BA_ "SignalLongName" SG_ 2155208704 ClsTrnkLidIO "Close Trunk Lid Indication On";
BA_ "VNSigAllNodes" SG_ 2155208704 ClsTrnkLidIO 1;
BA_ "GenSigSendType" SG_ 2155208704 CkSoftTpIO 10;
BA_ "SignalType" SG_ 2155208704 CkSoftTpIO "BLN";
BA_ "SignalLongName" SG_ 2155208704 CkSoftTpIO "Check Soft Top Indication On";
BA_ "VNSigAllNodes" SG_ 2155208704 CkSoftTpIO 1;
BA_ "GenSigSendType" SG_ 2155208704 SftTpTrnLmpsRqd 10;
BA_ "SignalType" SG_ 2155208704 SftTpTrnLmpsRqd "BLN";
BA_ "SignalLongName" SG_ 2155208704 SftTpTrnLmpsRqd "Soft Top Turn Lamps Requested";
BA_ "VNSigAllNodes" SG_ 2155208704 SftTpTrnLmpsRqd 1;
BA_ "GenSigSendType" SG_ 2155208704 FldngTpWndCmftRq 10;
BA_ "SignalType" SG_ 2155208704 FldngTpWndCmftRq "ENM";
BA_ "SignalLongName" SG_ 2155208704 FldngTpWndCmftRq "Folding Top Window Comfort Request";
BA_ "VNSigAllNodes" SG_ 2155208704 FldngTpWndCmftRq 1;
BA_ "GenSigSendType" SG_ 2155208704 FTUpdWndPsLmtEnbld 10;
BA_ "GenSigSendOnInit" SG_ 2155208704 FTUpdWndPsLmtEnbld 1;
BA_ "SignalType" SG_ 2155208704 FTUpdWndPsLmtEnbld "BLN";
BA_ "SignalLongName" SG_ 2155208704 FTUpdWndPsLmtEnbld "Folding Top Upward Window Position Limit Enable";
BA_ "VNSigAllNodes" SG_ 2155208704 FTUpdWndPsLmtEnbld 1;
BA_ "GenSigSendType" SG_ 2153390080 RrClosOpenSwAct_2D1V 10;
BA_ "SignalType" SG_ 2153390080 RrClosOpenSwAct_2D1V "ENM";
BA_ "SignalLongName" SG_ 2153390080 RrClosOpenSwAct_2D1V "Rear Closure Open Switch Active 2D1 Validity";
BA_ "VNSigAllNodes" SG_ 2153390080 RrClosOpenSwAct_2D1V 1;
BA_ "GenSigSendType" SG_ 2153390080 RrClosOpenSwAct_2D1 10;
BA_ "GenSigSendOnInit" SG_ 2153390080 RrClosOpenSwAct_2D1 2;
BA_ "SignalType" SG_ 2153390080 RrClosOpenSwAct_2D1 "BLN";
BA_ "SignalLongName" SG_ 2153390080 RrClosOpenSwAct_2D1 "Rear Closure Open Switch Active 2D1";
BA_ "VNSigAllNodes" SG_ 2153390080 RrClosOpenSwAct_2D1 1;
BA_ "GenSigSendType" SG_ 2155175936 AdptCrsLKALDWSwAct 10;
BA_ "SignalType" SG_ 2155175936 AdptCrsLKALDWSwAct "BLN";
BA_ "SignalLongName" SG_ 2155175936 AdptCrsLKALDWSwAct "Adaptive Cruise LKA LDW Switch Active";
BA_ "VNSigAllNodes" SG_ 2155175936 AdptCrsLKALDWSwAct 1;
BA_ "GenSigSendType" SG_ 2155175936 AdptCrsGapSwAct 10;
BA_ "SignalType" SG_ 2155175936 AdptCrsGapSwAct "ENM";
BA_ "SignalLongName" SG_ 2155175936 AdptCrsGapSwAct "Adaptive Cruise Control Gap Switch Activation";
BA_ "VNSigAllNodes" SG_ 2155175936 AdptCrsGapSwAct 1;
BA_ "GenSigSendType" SG_ 2156806144 CellNtwrkDtTmAvl 10;
BA_ "GenSigSendOnInit" SG_ 2156806144 CellNtwrkDtTmAvl 1;
BA_ "SignalType" SG_ 2156806144 CellNtwrkDtTmAvl "BLN";
BA_ "SignalLongName" SG_ 2156806144 CellNtwrkDtTmAvl "Cellular Network Date and Time Available";
BA_ "VNSigAllNodes" SG_ 2156806144 CellNtwrkDtTmAvl 1;
BA_ "GenSigSendType" SG_ 2156806144 SecCmpstdValV 10;
BA_ "SignalType" SG_ 2156806144 SecCmpstdValV "ENM";
BA_ "SignalLongName" SG_ 2156806144 SecCmpstdValV "Seconds Compensated Value Validity";
BA_ "VNSigAllNodes" SG_ 2156806144 SecCmpstdValV 1;
BA_ "GenSigDeltaValue" SG_ 2156806144 SecCmpstdVal 1;
BA_ "GenSigSendType" SG_ 2156806144 SecCmpstdVal 12;
BA_ "SignalType" SG_ 2156806144 SecCmpstdVal "UNM";
BA_ "SignalLongName" SG_ 2156806144 SecCmpstdVal "Seconds Compensated Value";
BA_ "VNSigAllNodes" SG_ 2156806144 SecCmpstdVal 1;
BA_ "GenSigSendType" SG_ 2156806144 MinsCmpstdValV 10;
BA_ "SignalType" SG_ 2156806144 MinsCmpstdValV "ENM";
BA_ "SignalLongName" SG_ 2156806144 MinsCmpstdValV "Minutes Compensated Value Validity";
BA_ "VNSigAllNodes" SG_ 2156806144 MinsCmpstdValV 1;
BA_ "GenSigDeltaValue" SG_ 2156806144 MinsCmpstdVal 1;
BA_ "GenSigSendType" SG_ 2156806144 MinsCmpstdVal 12;
BA_ "SignalType" SG_ 2156806144 MinsCmpstdVal "UNM";
BA_ "SignalLongName" SG_ 2156806144 MinsCmpstdVal "Minutes Compensated Value";
BA_ "VNSigAllNodes" SG_ 2156806144 MinsCmpstdVal 1;
BA_ "GenSigSendType" SG_ 2156806144 HrsCmpstdValV 10;
BA_ "SignalType" SG_ 2156806144 HrsCmpstdValV "ENM";
BA_ "SignalLongName" SG_ 2156806144 HrsCmpstdValV "Hours Compensated Value Validity";
BA_ "VNSigAllNodes" SG_ 2156806144 HrsCmpstdValV 1;
BA_ "GenSigDeltaValue" SG_ 2156806144 HrsCmpstdVal 1;
BA_ "GenSigSendType" SG_ 2156806144 HrsCmpstdVal 12;
BA_ "SignalType" SG_ 2156806144 HrsCmpstdVal "UNM";
BA_ "SignalLongName" SG_ 2156806144 HrsCmpstdVal "Hours Compensated Value";
BA_ "VNSigAllNodes" SG_ 2156806144 HrsCmpstdVal 1;
BA_ "GenSigDeltaValue" SG_ 2156806144 CldrYrCmpstdVal 1;
BA_ "GenSigSendType" SG_ 2156806144 CldrYrCmpstdVal 12;
BA_ "SignalType" SG_ 2156806144 CldrYrCmpstdVal "UNM";
BA_ "SignalLongName" SG_ 2156806144 CldrYrCmpstdVal "Calendar Year Compensated Value";
BA_ "VNSigAllNodes" SG_ 2156806144 CldrYrCmpstdVal 1;
BA_ "GenSigSendType" SG_ 2156806144 CldrMthCmpstdVal 10;
BA_ "SignalType" SG_ 2156806144 CldrMthCmpstdVal "ENM";
BA_ "SignalLongName" SG_ 2156806144 CldrMthCmpstdVal "Calendar Month Compensated Value";
BA_ "VNSigAllNodes" SG_ 2156806144 CldrMthCmpstdVal 1;
BA_ "GenSigDeltaValue" SG_ 2156806144 CldrDayCmpstdVal 1;
BA_ "GenSigSendType" SG_ 2156806144 CldrDayCmpstdVal 12;
BA_ "SignalType" SG_ 2156806144 CldrDayCmpstdVal "UNM";
BA_ "SignalLongName" SG_ 2156806144 CldrDayCmpstdVal "Calendar Day Compensated Value";
BA_ "VNSigAllNodes" SG_ 2156806144 CldrDayCmpstdVal 1;
BA_ "GenSigSendType" SG_ 2154078208 RRWndPosStat 10;
BA_ "GenSigSendOnInit" SG_ 2154078208 RRWndPosStat 2;
BA_ "SignalType" SG_ 2154078208 RRWndPosStat "ENM";
BA_ "SignalLongName" SG_ 2154078208 RRWndPosStat "Right Rear Window Position Status";
BA_ "VNSigAllNodes" SG_ 2154078208 RRWndPosStat 1;
BA_ "GenSigSendType" SG_ 2154078208 PsWndPosStat 10;
BA_ "GenSigSendOnInit" SG_ 2154078208 PsWndPosStat 2;
BA_ "SignalType" SG_ 2154078208 PsWndPosStat "ENM";
BA_ "SignalLongName" SG_ 2154078208 PsWndPosStat "Passenger Window Position Status";
BA_ "VNSigAllNodes" SG_ 2154078208 PsWndPosStat 1;
BA_ "GenSigSendType" SG_ 2154078208 LRWndPosStat 10;
BA_ "GenSigSendOnInit" SG_ 2154078208 LRWndPosStat 2;
BA_ "SignalType" SG_ 2154078208 LRWndPosStat "ENM";
BA_ "SignalLongName" SG_ 2154078208 LRWndPosStat "Left Rear Window Position Status";
BA_ "VNSigAllNodes" SG_ 2154078208 LRWndPosStat 1;
BA_ "GenSigSendType" SG_ 2154078208 DrvWndPosStat 10;
BA_ "GenSigSendOnInit" SG_ 2154078208 DrvWndPosStat 2;
BA_ "SignalType" SG_ 2154078208 DrvWndPosStat "ENM";
BA_ "SignalLongName" SG_ 2154078208 DrvWndPosStat "Driver Window Position Status";
BA_ "VNSigAllNodes" SG_ 2154078208 DrvWndPosStat 1;
BA_ "GenSigDeltaValue" SG_ 2159058944 ODIEI_MultiFrRetCh 1;
BA_ "GenSigSendType" SG_ 2159058944 ODIEI_MultiFrRetCh 12;
BA_ "VNSigInfotainment" SG_ 2159058944 ODIEI_MultiFrRetCh 1;
BA_ "SignalType" SG_ 2159058944 ODIEI_MultiFrRetCh "UNM";
BA_ "PacketOrder" SG_ 2159058944 ODIEI_MultiFrRetCh 3;
BA_ "SignalLongName" SG_ 2159058944 ODIEI_MultiFrRetCh "Open Display Interface Event Packet IPC : MultiFrameReturnChannel";
BA_ "VNSigAllNodes" SG_ 2159058944 ODIEI_MultiFrRetCh 1;
BA_ "GenSigDeltaValue" SG_ 2159058944 ODIEI_FUCID 1;
BA_ "GenSigSendType" SG_ 2159058944 ODIEI_FUCID 12;
BA_ "VNSigInfotainment" SG_ 2159058944 ODIEI_FUCID 1;
BA_ "SignalType" SG_ 2159058944 ODIEI_FUCID "UNM";
BA_ "PacketOrder" SG_ 2159058944 ODIEI_FUCID 2;
BA_ "SignalLongName" SG_ 2159058944 ODIEI_FUCID "Open Display Interface Event Packet IPC : Functional Unit Class ID";
BA_ "VNSigAllNodes" SG_ 2159058944 ODIEI_FUCID 1;
BA_ "GenSigDeltaValue" SG_ 2159058944 ODIEI_EvID 1;
BA_ "GenSigSendType" SG_ 2159058944 ODIEI_EvID 12;
BA_ "VNSigInfotainment" SG_ 2159058944 ODIEI_EvID 1;
BA_ "SignalType" SG_ 2159058944 ODIEI_EvID "UNM";
BA_ "PacketOrder" SG_ 2159058944 ODIEI_EvID 1;
BA_ "SignalLongName" SG_ 2159058944 ODIEI_EvID "Open Display Interface Event Packet IPC : Event ID";
BA_ "VNSigAllNodes" SG_ 2159058944 ODIEI_EvID 1;
BA_ "GenSigDeltaValue" SG_ 2159042560 ODDI_DataVal 1;
BA_ "GenSigSendType" SG_ 2159042560 ODDI_DataVal 12;
BA_ "VNSigInfotainment" SG_ 2159042560 ODDI_DataVal 1;
BA_ "SignalType" SG_ 2159042560 ODDI_DataVal "UNM";
BA_ "PacketOrder" SG_ 2159042560 ODDI_DataVal 5;
BA_ "SignalLongName" SG_ 2159042560 ODDI_DataVal "Open Display Interface Dynamic Data IPC : Data Value";
BA_ "VNSigAllNodes" SG_ 2159042560 ODDI_DataVal 1;
BA_ "GenSigDeltaValue" SG_ 2159042560 ODDI_DataId 1;
BA_ "GenSigSendType" SG_ 2159042560 ODDI_DataId 12;
BA_ "VNSigInfotainment" SG_ 2159042560 ODDI_DataId 1;
BA_ "SignalType" SG_ 2159042560 ODDI_DataId "UNM";
BA_ "PacketOrder" SG_ 2159042560 ODDI_DataId 4;
BA_ "SignalLongName" SG_ 2159042560 ODDI_DataId "Open Display Interface Dynamic Data IPC : Data ID";
BA_ "VNSigAllNodes" SG_ 2159042560 ODDI_DataId 1;
BA_ "GenSigDeltaValue" SG_ 2159042560 ODDI_FUCID 1;
BA_ "GenSigSendType" SG_ 2159042560 ODDI_FUCID 12;
BA_ "VNSigInfotainment" SG_ 2159042560 ODDI_FUCID 1;
BA_ "SignalType" SG_ 2159042560 ODDI_FUCID "UNM";
BA_ "PacketOrder" SG_ 2159042560 ODDI_FUCID 3;
BA_ "SignalLongName" SG_ 2159042560 ODDI_FUCID "Open Display Interface Dynamic Data IPC : Functional Unit Class ID";
BA_ "VNSigAllNodes" SG_ 2159042560 ODDI_FUCID 1;
BA_ "GenSigSendType" SG_ 2159042560 ODDI_InvldData 10;
BA_ "VNSigInfotainment" SG_ 2159042560 ODDI_InvldData 1;
BA_ "SignalType" SG_ 2159042560 ODDI_InvldData "BLN";
BA_ "PacketOrder" SG_ 2159042560 ODDI_InvldData 2;
BA_ "SignalLongName" SG_ 2159042560 ODDI_InvldData "Open Display Interface Dynamic Data IPC : Invalid Data";
BA_ "VNSigAllNodes" SG_ 2159042560 ODDI_InvldData 1;
BA_ "GenSigSendType" SG_ 2159042560 ODDI_DataType 10;
BA_ "VNSigInfotainment" SG_ 2159042560 ODDI_DataType 1;
BA_ "SignalType" SG_ 2159042560 ODDI_DataType "ENM";
BA_ "PacketOrder" SG_ 2159042560 ODDI_DataType 1;
BA_ "SignalLongName" SG_ 2159042560 ODDI_DataType "Open Display Interface Dynamic Data IPC : Data Type";
BA_ "VNSigAllNodes" SG_ 2159042560 ODDI_DataType 1;
BA_ "GenSigSendType" SG_ 2150006784 SysPwrMdPshbtnActV 10;
BA_ "GenSigSendOnInit" SG_ 2150006784 SysPwrMdPshbtnActV 1;
BA_ "SignalType" SG_ 2150006784 SysPwrMdPshbtnActV "ENM";
BA_ "SignalLongName" SG_ 2150006784 SysPwrMdPshbtnActV "System Power Mode Pushbutton Active Validity";
BA_ "VNSigAllNodes" SG_ 2150006784 SysPwrMdPshbtnActV 1;
BA_ "GenSigSendType" SG_ 2150006784 SysPwrMdPshbtnAct 10;
BA_ "GenSigSendOnInit" SG_ 2150006784 SysPwrMdPshbtnAct 1;
BA_ "SignalType" SG_ 2150006784 SysPwrMdPshbtnAct "BLN";
BA_ "SignalLongName" SG_ 2150006784 SysPwrMdPshbtnAct "System Power Mode Pushbutton Active";
BA_ "VNSigAllNodes" SG_ 2150006784 SysPwrMdPshbtnAct 1;
BA_ "GenSigSendType" SG_ 2150006784 PEPSRunCrnkRlyDctd 10;
BA_ "SignalType" SG_ 2150006784 PEPSRunCrnkRlyDctd "BLN";
BA_ "SignalLongName" SG_ 2150006784 PEPSRunCrnkRlyDctd "PEPS Run Crank Relay Deactivated";
BA_ "VNSigAllNodes" SG_ 2150006784 PEPSRunCrnkRlyDctd 1;
BA_ "GenSigSendType" SG_ 2155216896 DgtlMapPstdSpdLimAsrd 10;
BA_ "GenSigSendOnInit" SG_ 2155216896 DgtlMapPstdSpdLimAsrd 1;
BA_ "SignalType" SG_ 2155216896 DgtlMapPstdSpdLimAsrd "BLN";
BA_ "SignalLongName" SG_ 2155216896 DgtlMapPstdSpdLimAsrd "Digital Map Posted Speed Limit Assured";
BA_ "VNSigAllNodes" SG_ 2155216896 DgtlMapPstdSpdLimAsrd 1;
BA_ "GenSigSendType" SG_ 2155216896 SpdLmtPstdSpdM 10;
BA_ "SignalType" SG_ 2155216896 SpdLmtPstdSpdM "ENM";
BA_ "SignalLongName" SG_ 2155216896 SpdLmtPstdSpdM "Speed Limit Posted Speed Mask";
BA_ "VNSigAllNodes" SG_ 2155216896 SpdLmtPstdSpdM 1;
BA_ "GenSigSendType" SG_ 2155216896 ISA2CCC_ScndCdChr 10;
BA_ "SignalType" SG_ 2155216896 ISA2CCC_ScndCdChr "ENM";
BA_ "PacketOrder" SG_ 2155216896 ISA2CCC_ScndCdChr 2;
BA_ "SignalLongName" SG_ 2155216896 ISA2CCC_ScndCdChr "International Standard Alpha 2 Coded Country Code : Second Code Character";
BA_ "VNSigAllNodes" SG_ 2155216896 ISA2CCC_ScndCdChr 1;
BA_ "GenSigSendType" SG_ 2155216896 ISA2CCC_FrstCdChr 10;
BA_ "SignalType" SG_ 2155216896 ISA2CCC_FrstCdChr "ENM";
BA_ "PacketOrder" SG_ 2155216896 ISA2CCC_FrstCdChr 1;
BA_ "SignalLongName" SG_ 2155216896 ISA2CCC_FrstCdChr "International Standard Alpha 2 Coded Country Code : First Code Character";
BA_ "VNSigAllNodes" SG_ 2155216896 ISA2CCC_FrstCdChr 1;
BA_ "GenSigSendType" SG_ 2155216896 CurvAdvInd 10;
BA_ "SignalType" SG_ 2155216896 CurvAdvInd "ENM";
BA_ "SignalLongName" SG_ 2155216896 CurvAdvInd "Curve Advisory Indication";
BA_ "VNSigAllNodes" SG_ 2155216896 CurvAdvInd 1;
BA_ "GenSigSendType" SG_ 2155216896 SpdLmtUnits 10;
BA_ "SignalType" SG_ 2155216896 SpdLmtUnits "ENM";
BA_ "SignalLongName" SG_ 2155216896 SpdLmtUnits "Speed Limit Units";
BA_ "VNSigAllNodes" SG_ 2155216896 SpdLmtUnits 1;
BA_ "GenSigDeltaValue" SG_ 2155216896 SpdLmtRecmndSpd 1;
BA_ "GenSigSendType" SG_ 2155216896 SpdLmtRecmndSpd 12;
BA_ "SignalType" SG_ 2155216896 SpdLmtRecmndSpd "UNM";
BA_ "SignalLongName" SG_ 2155216896 SpdLmtRecmndSpd "Speed Limit Recommended Speed";
BA_ "VNSigAllNodes" SG_ 2155216896 SpdLmtRecmndSpd 1;
BA_ "GenSigDeltaValue" SG_ 2155216896 SpdLmtPstdSpd 1;
BA_ "GenSigSendType" SG_ 2155216896 SpdLmtPstdSpd 12;
BA_ "SignalType" SG_ 2155216896 SpdLmtPstdSpd "UNM";
BA_ "SignalLongName" SG_ 2155216896 SpdLmtPstdSpd "Speed Limit Posted Speed";
BA_ "VNSigAllNodes" SG_ 2155216896 SpdLmtPstdSpd 1;
BA_ "GenSigSendType" SG_ 2155216896 LnCat 10;
BA_ "GenSigSendOnInit" SG_ 2155216896 LnCat 1;
BA_ "SignalType" SG_ 2155216896 LnCat "ENM";
BA_ "SignalLongName" SG_ 2155216896 LnCat "Lane Category";
BA_ "VNSigAllNodes" SG_ 2155216896 LnCat 1;
BA_ "GenSigSendType" SG_ 2155216896 RdSpdCatType 10;
BA_ "GenSigSendOnInit" SG_ 2155216896 RdSpdCatType 1;
BA_ "SignalType" SG_ 2155216896 RdSpdCatType "ENM";
BA_ "SignalLongName" SG_ 2155216896 RdSpdCatType "Road Speed Category Type";
BA_ "VNSigAllNodes" SG_ 2155216896 RdSpdCatType 1;
BA_ "GenSigSendType" SG_ 2155216896 FncRdClass 10;
BA_ "GenSigSendOnInit" SG_ 2155216896 FncRdClass 1;
BA_ "SignalType" SG_ 2155216896 FncRdClass "ENM";
BA_ "SignalLongName" SG_ 2155216896 FncRdClass "Functional Road Class";
BA_ "VNSigAllNodes" SG_ 2155216896 FncRdClass 1;
BA_ "GenSigSendType" SG_ 2155216896 SprtLnRd 10;
BA_ "GenSigSendOnInit" SG_ 2155216896 SprtLnRd 1;
BA_ "SignalType" SG_ 2155216896 SprtLnRd "BLN";
BA_ "SignalLongName" SG_ 2155216896 SprtLnRd "Separate Lane Road";
BA_ "VNSigAllNodes" SG_ 2155216896 SprtLnRd 1;
BA_ "GenSigSendType" SG_ 2155216896 CntrldAccRd 10;
BA_ "GenSigSendOnInit" SG_ 2155216896 CntrldAccRd 1;
BA_ "SignalType" SG_ 2155216896 CntrldAccRd "BLN";
BA_ "SignalLongName" SG_ 2155216896 CntrldAccRd "Controlled Access Road";
BA_ "VNSigAllNodes" SG_ 2155216896 CntrldAccRd 1;
BA_ "GenSigSendType" SG_ 2155216896 BldUpArDet 10;
BA_ "GenSigSendOnInit" SG_ 2155216896 BldUpArDet 1;
BA_ "SignalType" SG_ 2155216896 BldUpArDet "BLN";
BA_ "SignalLongName" SG_ 2155216896 BldUpArDet "Build Up Area Detected";
BA_ "VNSigAllNodes" SG_ 2155216896 BldUpArDet 1;
BA_ "GenSigSendType" SG_ 2155216896 MpDataAvlbl 10;
BA_ "GenSigSendOnInit" SG_ 2155216896 MpDataAvlbl 1;
BA_ "SignalType" SG_ 2155216896 MpDataAvlbl "BLN";
BA_ "SignalLongName" SG_ 2155216896 MpDataAvlbl "Map Data Available";
BA_ "VNSigAllNodes" SG_ 2155216896 MpDataAvlbl 1;
BA_ "GenSigSendType" SG_ 2156216320 TxtTelephoneDevPr 10;
BA_ "GenSigSendOnInit" SG_ 2156216320 TxtTelephoneDevPr 2;
BA_ "VNSigInfotainment" SG_ 2156216320 TxtTelephoneDevPr 1;
BA_ "SignalType" SG_ 2156216320 TxtTelephoneDevPr "BLN";
BA_ "SignalLongName" SG_ 2156216320 TxtTelephoneDevPr "Text Telephone Device Present";
BA_ "VNSigAllNodes" SG_ 2156216320 TxtTelephoneDevPr 1;
BA_ "GenSigSendType" SG_ 2158813184 ODIIIPC_ODIInd56 10;
BA_ "GenSigSendOnInit" SG_ 2158813184 ODIIIPC_ODIInd56 1;
BA_ "VNSigInfotainment" SG_ 2158813184 ODIIIPC_ODIInd56 1;
BA_ "SignalType" SG_ 2158813184 ODIIIPC_ODIInd56 "BLN";
BA_ "PacketOrder" SG_ 2158813184 ODIIIPC_ODIInd56 57;
BA_ "SignalLongName" SG_ 2158813184 ODIIIPC_ODIInd56 "Open Display Interface Indication IPC : Open Display Interface Indication 56";
BA_ "VNSigAllNodes" SG_ 2158813184 ODIIIPC_ODIInd56 1;
BA_ "GenSigSendType" SG_ 2158813184 ODIIIPC_ODIInd55 10;
BA_ "GenSigSendOnInit" SG_ 2158813184 ODIIIPC_ODIInd55 1;
BA_ "VNSigInfotainment" SG_ 2158813184 ODIIIPC_ODIInd55 1;
BA_ "SignalType" SG_ 2158813184 ODIIIPC_ODIInd55 "BLN";
BA_ "PacketOrder" SG_ 2158813184 ODIIIPC_ODIInd55 56;
BA_ "SignalLongName" SG_ 2158813184 ODIIIPC_ODIInd55 "Open Display Interface Indication IPC : Open Display Interface Indication 55";
BA_ "VNSigAllNodes" SG_ 2158813184 ODIIIPC_ODIInd55 1;
BA_ "GenSigSendType" SG_ 2158813184 ODIIIPC_ODIInd54 10;
BA_ "GenSigSendOnInit" SG_ 2158813184 ODIIIPC_ODIInd54 1;
BA_ "VNSigInfotainment" SG_ 2158813184 ODIIIPC_ODIInd54 1;
BA_ "SignalType" SG_ 2158813184 ODIIIPC_ODIInd54 "BLN";
BA_ "PacketOrder" SG_ 2158813184 ODIIIPC_ODIInd54 55;
BA_ "SignalLongName" SG_ 2158813184 ODIIIPC_ODIInd54 "Open Display Interface Indication IPC : Open Display Interface Indication 54";
BA_ "VNSigAllNodes" SG_ 2158813184 ODIIIPC_ODIInd54 1;
BA_ "GenSigSendType" SG_ 2158813184 ODIIIPC_ODIInd53 10;
BA_ "GenSigSendOnInit" SG_ 2158813184 ODIIIPC_ODIInd53 1;
BA_ "VNSigInfotainment" SG_ 2158813184 ODIIIPC_ODIInd53 1;
BA_ "SignalType" SG_ 2158813184 ODIIIPC_ODIInd53 "BLN";
BA_ "PacketOrder" SG_ 2158813184 ODIIIPC_ODIInd53 54;
BA_ "SignalLongName" SG_ 2158813184 ODIIIPC_ODIInd53 "Open Display Interface Indication IPC : Open Display Interface Indication 53";
BA_ "VNSigAllNodes" SG_ 2158813184 ODIIIPC_ODIInd53 1;
BA_ "GenSigSendType" SG_ 2158813184 ODIIIPC_ODIInd52 10;
BA_ "GenSigSendOnInit" SG_ 2158813184 ODIIIPC_ODIInd52 1;
BA_ "VNSigInfotainment" SG_ 2158813184 ODIIIPC_ODIInd52 1;
BA_ "SignalType" SG_ 2158813184 ODIIIPC_ODIInd52 "BLN";
BA_ "PacketOrder" SG_ 2158813184 ODIIIPC_ODIInd52 53;
BA_ "SignalLongName" SG_ 2158813184 ODIIIPC_ODIInd52 "Open Display Interface Indication IPC : Open Display Interface Indication 52";
BA_ "VNSigAllNodes" SG_ 2158813184 ODIIIPC_ODIInd52 1;
BA_ "GenSigSendType" SG_ 2158813184 ODIIIPC_ODIInd51 10;
BA_ "GenSigSendOnInit" SG_ 2158813184 ODIIIPC_ODIInd51 1;
BA_ "VNSigInfotainment" SG_ 2158813184 ODIIIPC_ODIInd51 1;
BA_ "SignalType" SG_ 2158813184 ODIIIPC_ODIInd51 "BLN";
BA_ "PacketOrder" SG_ 2158813184 ODIIIPC_ODIInd51 52;
BA_ "SignalLongName" SG_ 2158813184 ODIIIPC_ODIInd51 "Open Display Interface Indication IPC : Open Display Interface Indication 51";
BA_ "VNSigAllNodes" SG_ 2158813184 ODIIIPC_ODIInd51 1;
BA_ "GenSigSendType" SG_ 2158813184 ODIIIPC_ODIInd50 10;
BA_ "GenSigSendOnInit" SG_ 2158813184 ODIIIPC_ODIInd50 1;
BA_ "VNSigInfotainment" SG_ 2158813184 ODIIIPC_ODIInd50 1;
BA_ "SignalType" SG_ 2158813184 ODIIIPC_ODIInd50 "BLN";
BA_ "PacketOrder" SG_ 2158813184 ODIIIPC_ODIInd50 51;
BA_ "SignalLongName" SG_ 2158813184 ODIIIPC_ODIInd50 "Open Display Interface Indication IPC : Open Display Interface Indication 50";
BA_ "VNSigAllNodes" SG_ 2158813184 ODIIIPC_ODIInd50 1;
BA_ "GenSigSendType" SG_ 2158813184 ODIIIPC_ODIInd49 10;
BA_ "GenSigSendOnInit" SG_ 2158813184 ODIIIPC_ODIInd49 1;
BA_ "VNSigInfotainment" SG_ 2158813184 ODIIIPC_ODIInd49 1;
BA_ "SignalType" SG_ 2158813184 ODIIIPC_ODIInd49 "BLN";
BA_ "PacketOrder" SG_ 2158813184 ODIIIPC_ODIInd49 50;
BA_ "SignalLongName" SG_ 2158813184 ODIIIPC_ODIInd49 "Open Display Interface Indication IPC : Open Display Interface Indication 49";
BA_ "VNSigAllNodes" SG_ 2158813184 ODIIIPC_ODIInd49 1;
BA_ "GenSigSendType" SG_ 2158813184 ODIIIPC_ODIInd48 10;
BA_ "GenSigSendOnInit" SG_ 2158813184 ODIIIPC_ODIInd48 1;
BA_ "VNSigInfotainment" SG_ 2158813184 ODIIIPC_ODIInd48 1;
BA_ "SignalType" SG_ 2158813184 ODIIIPC_ODIInd48 "BLN";
BA_ "PacketOrder" SG_ 2158813184 ODIIIPC_ODIInd48 49;
BA_ "SignalLongName" SG_ 2158813184 ODIIIPC_ODIInd48 "Open Display Interface Indication IPC : Open Display Interface Indication 48";
BA_ "VNSigAllNodes" SG_ 2158813184 ODIIIPC_ODIInd48 1;
BA_ "GenSigSendType" SG_ 2158813184 ODIIIPC_ODIInd47 10;
BA_ "GenSigSendOnInit" SG_ 2158813184 ODIIIPC_ODIInd47 1;
BA_ "VNSigInfotainment" SG_ 2158813184 ODIIIPC_ODIInd47 1;
BA_ "SignalType" SG_ 2158813184 ODIIIPC_ODIInd47 "BLN";
BA_ "PacketOrder" SG_ 2158813184 ODIIIPC_ODIInd47 48;
BA_ "SignalLongName" SG_ 2158813184 ODIIIPC_ODIInd47 "Open Display Interface Indication IPC : Open Display Interface Indication 47";
BA_ "VNSigAllNodes" SG_ 2158813184 ODIIIPC_ODIInd47 1;
BA_ "GenSigSendType" SG_ 2158813184 ODIIIPC_ODIInd46 10;
BA_ "GenSigSendOnInit" SG_ 2158813184 ODIIIPC_ODIInd46 1;
BA_ "VNSigInfotainment" SG_ 2158813184 ODIIIPC_ODIInd46 1;
BA_ "SignalType" SG_ 2158813184 ODIIIPC_ODIInd46 "BLN";
BA_ "PacketOrder" SG_ 2158813184 ODIIIPC_ODIInd46 47;
BA_ "SignalLongName" SG_ 2158813184 ODIIIPC_ODIInd46 "Open Display Interface Indication IPC : Open Display Interface Indication 46";
BA_ "VNSigAllNodes" SG_ 2158813184 ODIIIPC_ODIInd46 1;
BA_ "GenSigSendType" SG_ 2158813184 ODIIIPC_ODIInd45 10;
BA_ "GenSigSendOnInit" SG_ 2158813184 ODIIIPC_ODIInd45 1;
BA_ "VNSigInfotainment" SG_ 2158813184 ODIIIPC_ODIInd45 1;
BA_ "SignalType" SG_ 2158813184 ODIIIPC_ODIInd45 "BLN";
BA_ "PacketOrder" SG_ 2158813184 ODIIIPC_ODIInd45 46;
BA_ "SignalLongName" SG_ 2158813184 ODIIIPC_ODIInd45 "Open Display Interface Indication IPC : Open Display Interface Indication 45";
BA_ "VNSigAllNodes" SG_ 2158813184 ODIIIPC_ODIInd45 1;
BA_ "GenSigSendType" SG_ 2158813184 ODIIIPC_ODIInd44 10;
BA_ "GenSigSendOnInit" SG_ 2158813184 ODIIIPC_ODIInd44 1;
BA_ "VNSigInfotainment" SG_ 2158813184 ODIIIPC_ODIInd44 1;
BA_ "SignalType" SG_ 2158813184 ODIIIPC_ODIInd44 "BLN";
BA_ "PacketOrder" SG_ 2158813184 ODIIIPC_ODIInd44 45;
BA_ "SignalLongName" SG_ 2158813184 ODIIIPC_ODIInd44 "Open Display Interface Indication IPC : Open Display Interface Indication 44";
BA_ "VNSigAllNodes" SG_ 2158813184 ODIIIPC_ODIInd44 1;
BA_ "GenSigSendType" SG_ 2158813184 ODIIIPC_ODIInd43 10;
BA_ "GenSigSendOnInit" SG_ 2158813184 ODIIIPC_ODIInd43 1;
BA_ "VNSigInfotainment" SG_ 2158813184 ODIIIPC_ODIInd43 1;
BA_ "SignalType" SG_ 2158813184 ODIIIPC_ODIInd43 "BLN";
BA_ "PacketOrder" SG_ 2158813184 ODIIIPC_ODIInd43 44;
BA_ "SignalLongName" SG_ 2158813184 ODIIIPC_ODIInd43 "Open Display Interface Indication IPC : Open Display Interface Indication 43";
BA_ "VNSigAllNodes" SG_ 2158813184 ODIIIPC_ODIInd43 1;
BA_ "GenSigSendType" SG_ 2158813184 ODIIIPC_ODIInd42 10;
BA_ "GenSigSendOnInit" SG_ 2158813184 ODIIIPC_ODIInd42 1;
BA_ "VNSigInfotainment" SG_ 2158813184 ODIIIPC_ODIInd42 1;
BA_ "SignalType" SG_ 2158813184 ODIIIPC_ODIInd42 "BLN";
BA_ "PacketOrder" SG_ 2158813184 ODIIIPC_ODIInd42 43;
BA_ "SignalLongName" SG_ 2158813184 ODIIIPC_ODIInd42 "Open Display Interface Indication IPC : Open Display Interface Indication 42";
BA_ "VNSigAllNodes" SG_ 2158813184 ODIIIPC_ODIInd42 1;
BA_ "GenSigSendType" SG_ 2158813184 ODIIIPC_ODIInd41 10;
BA_ "GenSigSendOnInit" SG_ 2158813184 ODIIIPC_ODIInd41 1;
BA_ "VNSigInfotainment" SG_ 2158813184 ODIIIPC_ODIInd41 1;
BA_ "SignalType" SG_ 2158813184 ODIIIPC_ODIInd41 "BLN";
BA_ "PacketOrder" SG_ 2158813184 ODIIIPC_ODIInd41 42;
BA_ "SignalLongName" SG_ 2158813184 ODIIIPC_ODIInd41 "Open Display Interface Indication IPC : Open Display Interface Indication 41";
BA_ "VNSigAllNodes" SG_ 2158813184 ODIIIPC_ODIInd41 1;
BA_ "GenSigSendType" SG_ 2158813184 ODIIIPC_ODIInd40 10;
BA_ "GenSigSendOnInit" SG_ 2158813184 ODIIIPC_ODIInd40 1;
BA_ "VNSigInfotainment" SG_ 2158813184 ODIIIPC_ODIInd40 1;
BA_ "SignalType" SG_ 2158813184 ODIIIPC_ODIInd40 "BLN";
BA_ "PacketOrder" SG_ 2158813184 ODIIIPC_ODIInd40 41;
BA_ "SignalLongName" SG_ 2158813184 ODIIIPC_ODIInd40 "Open Display Interface Indication IPC : Open Display Interface Indication 40";
BA_ "VNSigAllNodes" SG_ 2158813184 ODIIIPC_ODIInd40 1;
BA_ "GenSigSendType" SG_ 2158813184 ODIIIPC_ODIInd39 10;
BA_ "GenSigSendOnInit" SG_ 2158813184 ODIIIPC_ODIInd39 1;
BA_ "VNSigInfotainment" SG_ 2158813184 ODIIIPC_ODIInd39 1;
BA_ "SignalType" SG_ 2158813184 ODIIIPC_ODIInd39 "BLN";
BA_ "PacketOrder" SG_ 2158813184 ODIIIPC_ODIInd39 40;
BA_ "SignalLongName" SG_ 2158813184 ODIIIPC_ODIInd39 "Open Display Interface Indication IPC : Open Display Interface Indication 39";
BA_ "VNSigAllNodes" SG_ 2158813184 ODIIIPC_ODIInd39 1;
BA_ "GenSigSendType" SG_ 2158813184 ODIIIPC_ODIInd38 10;
BA_ "GenSigSendOnInit" SG_ 2158813184 ODIIIPC_ODIInd38 1;
BA_ "VNSigInfotainment" SG_ 2158813184 ODIIIPC_ODIInd38 1;
BA_ "SignalType" SG_ 2158813184 ODIIIPC_ODIInd38 "BLN";
BA_ "PacketOrder" SG_ 2158813184 ODIIIPC_ODIInd38 39;
BA_ "SignalLongName" SG_ 2158813184 ODIIIPC_ODIInd38 "Open Display Interface Indication IPC : Open Display Interface Indication 38";
BA_ "VNSigAllNodes" SG_ 2158813184 ODIIIPC_ODIInd38 1;
BA_ "GenSigSendType" SG_ 2158813184 ODIIIPC_ODIInd9 10;
BA_ "GenSigSendOnInit" SG_ 2158813184 ODIIIPC_ODIInd9 1;
BA_ "VNSigInfotainment" SG_ 2158813184 ODIIIPC_ODIInd9 1;
BA_ "SignalType" SG_ 2158813184 ODIIIPC_ODIInd9 "BLN";
BA_ "PacketOrder" SG_ 2158813184 ODIIIPC_ODIInd9 10;
BA_ "SignalLongName" SG_ 2158813184 ODIIIPC_ODIInd9 "Open Display Interface Indication IPC : Open Display Interface Indication 9";
BA_ "VNSigAllNodes" SG_ 2158813184 ODIIIPC_ODIInd9 1;
BA_ "GenSigSendType" SG_ 2158813184 ODIIIPC_ODIInd8 10;
BA_ "GenSigSendOnInit" SG_ 2158813184 ODIIIPC_ODIInd8 1;
BA_ "VNSigInfotainment" SG_ 2158813184 ODIIIPC_ODIInd8 1;
BA_ "SignalType" SG_ 2158813184 ODIIIPC_ODIInd8 "BLN";
BA_ "PacketOrder" SG_ 2158813184 ODIIIPC_ODIInd8 9;
BA_ "SignalLongName" SG_ 2158813184 ODIIIPC_ODIInd8 "Open Display Interface Indication IPC : Open Display Interface Indication 8";
BA_ "VNSigAllNodes" SG_ 2158813184 ODIIIPC_ODIInd8 1;
BA_ "GenSigSendType" SG_ 2158813184 ODIIIPC_ODIInd7 10;
BA_ "GenSigSendOnInit" SG_ 2158813184 ODIIIPC_ODIInd7 1;
BA_ "VNSigInfotainment" SG_ 2158813184 ODIIIPC_ODIInd7 1;
BA_ "SignalType" SG_ 2158813184 ODIIIPC_ODIInd7 "BLN";
BA_ "PacketOrder" SG_ 2158813184 ODIIIPC_ODIInd7 8;
BA_ "SignalLongName" SG_ 2158813184 ODIIIPC_ODIInd7 "Open Display Interface Indication IPC : Open Display Interface Indication 7";
BA_ "VNSigAllNodes" SG_ 2158813184 ODIIIPC_ODIInd7 1;
BA_ "GenSigSendType" SG_ 2158813184 ODIIIPC_ODIInd6 10;
BA_ "GenSigSendOnInit" SG_ 2158813184 ODIIIPC_ODIInd6 1;
BA_ "VNSigInfotainment" SG_ 2158813184 ODIIIPC_ODIInd6 1;
BA_ "SignalType" SG_ 2158813184 ODIIIPC_ODIInd6 "BLN";
BA_ "PacketOrder" SG_ 2158813184 ODIIIPC_ODIInd6 7;
BA_ "SignalLongName" SG_ 2158813184 ODIIIPC_ODIInd6 "Open Display Interface Indication IPC : Open Display Interface Indication 6";
BA_ "VNSigAllNodes" SG_ 2158813184 ODIIIPC_ODIInd6 1;
BA_ "GenSigSendType" SG_ 2158813184 ODIIIPC_ODIInd5 10;
BA_ "GenSigSendOnInit" SG_ 2158813184 ODIIIPC_ODIInd5 1;
BA_ "VNSigInfotainment" SG_ 2158813184 ODIIIPC_ODIInd5 1;
BA_ "SignalType" SG_ 2158813184 ODIIIPC_ODIInd5 "BLN";
BA_ "PacketOrder" SG_ 2158813184 ODIIIPC_ODIInd5 6;
BA_ "SignalLongName" SG_ 2158813184 ODIIIPC_ODIInd5 "Open Display Interface Indication IPC : Open Display Interface Indication 5";
BA_ "VNSigAllNodes" SG_ 2158813184 ODIIIPC_ODIInd5 1;
BA_ "GenSigSendType" SG_ 2158813184 ODIIIPC_ODIInd4 10;
BA_ "GenSigSendOnInit" SG_ 2158813184 ODIIIPC_ODIInd4 1;
BA_ "VNSigInfotainment" SG_ 2158813184 ODIIIPC_ODIInd4 1;
BA_ "SignalType" SG_ 2158813184 ODIIIPC_ODIInd4 "BLN";
BA_ "PacketOrder" SG_ 2158813184 ODIIIPC_ODIInd4 5;
BA_ "SignalLongName" SG_ 2158813184 ODIIIPC_ODIInd4 "Open Display Interface Indication IPC : Open Display Interface Indication 4";
BA_ "VNSigAllNodes" SG_ 2158813184 ODIIIPC_ODIInd4 1;
BA_ "GenSigSendType" SG_ 2158813184 ODIIIPC_ODIInd3 10;
BA_ "GenSigSendOnInit" SG_ 2158813184 ODIIIPC_ODIInd3 1;
BA_ "VNSigInfotainment" SG_ 2158813184 ODIIIPC_ODIInd3 1;
BA_ "SignalType" SG_ 2158813184 ODIIIPC_ODIInd3 "BLN";
BA_ "PacketOrder" SG_ 2158813184 ODIIIPC_ODIInd3 4;
BA_ "SignalLongName" SG_ 2158813184 ODIIIPC_ODIInd3 "Open Display Interface Indication IPC : Open Display Interface Indication 3";
BA_ "VNSigAllNodes" SG_ 2158813184 ODIIIPC_ODIInd3 1;
BA_ "GenSigSendType" SG_ 2158813184 ODIIIPC_ODIInd37 10;
BA_ "GenSigSendOnInit" SG_ 2158813184 ODIIIPC_ODIInd37 1;
BA_ "VNSigInfotainment" SG_ 2158813184 ODIIIPC_ODIInd37 1;
BA_ "SignalType" SG_ 2158813184 ODIIIPC_ODIInd37 "BLN";
BA_ "PacketOrder" SG_ 2158813184 ODIIIPC_ODIInd37 38;
BA_ "SignalLongName" SG_ 2158813184 ODIIIPC_ODIInd37 "Open Display Interface Indication IPC : Open Display Interface Indication 37";
BA_ "VNSigAllNodes" SG_ 2158813184 ODIIIPC_ODIInd37 1;
BA_ "GenSigSendType" SG_ 2158813184 ODIIIPC_ODIInd36 10;
BA_ "GenSigSendOnInit" SG_ 2158813184 ODIIIPC_ODIInd36 1;
BA_ "VNSigInfotainment" SG_ 2158813184 ODIIIPC_ODIInd36 1;
BA_ "SignalType" SG_ 2158813184 ODIIIPC_ODIInd36 "BLN";
BA_ "PacketOrder" SG_ 2158813184 ODIIIPC_ODIInd36 37;
BA_ "SignalLongName" SG_ 2158813184 ODIIIPC_ODIInd36 "Open Display Interface Indication IPC : Open Display Interface Indication 36";
BA_ "VNSigAllNodes" SG_ 2158813184 ODIIIPC_ODIInd36 1;
BA_ "GenSigSendType" SG_ 2158813184 ODIIIPC_ODIInd35 10;
BA_ "GenSigSendOnInit" SG_ 2158813184 ODIIIPC_ODIInd35 1;
BA_ "VNSigInfotainment" SG_ 2158813184 ODIIIPC_ODIInd35 1;
BA_ "SignalType" SG_ 2158813184 ODIIIPC_ODIInd35 "BLN";
BA_ "PacketOrder" SG_ 2158813184 ODIIIPC_ODIInd35 36;
BA_ "SignalLongName" SG_ 2158813184 ODIIIPC_ODIInd35 "Open Display Interface Indication IPC : Open Display Interface Indication 35";
BA_ "VNSigAllNodes" SG_ 2158813184 ODIIIPC_ODIInd35 1;
BA_ "GenSigSendType" SG_ 2158813184 ODIIIPC_ODIInd34 10;
BA_ "GenSigSendOnInit" SG_ 2158813184 ODIIIPC_ODIInd34 1;
BA_ "VNSigInfotainment" SG_ 2158813184 ODIIIPC_ODIInd34 1;
BA_ "SignalType" SG_ 2158813184 ODIIIPC_ODIInd34 "BLN";
BA_ "PacketOrder" SG_ 2158813184 ODIIIPC_ODIInd34 35;
BA_ "SignalLongName" SG_ 2158813184 ODIIIPC_ODIInd34 "Open Display Interface Indication IPC : Open Display Interface Indication 34";
BA_ "VNSigAllNodes" SG_ 2158813184 ODIIIPC_ODIInd34 1;
BA_ "GenSigSendType" SG_ 2158813184 ODIIIPC_ODIInd33 10;
BA_ "GenSigSendOnInit" SG_ 2158813184 ODIIIPC_ODIInd33 1;
BA_ "VNSigInfotainment" SG_ 2158813184 ODIIIPC_ODIInd33 1;
BA_ "SignalType" SG_ 2158813184 ODIIIPC_ODIInd33 "BLN";
BA_ "PacketOrder" SG_ 2158813184 ODIIIPC_ODIInd33 34;
BA_ "SignalLongName" SG_ 2158813184 ODIIIPC_ODIInd33 "Open Display Interface Indication IPC : Open Display Interface Indication 33";
BA_ "VNSigAllNodes" SG_ 2158813184 ODIIIPC_ODIInd33 1;
BA_ "GenSigSendType" SG_ 2158813184 ODIIIPC_ODIInd32 10;
BA_ "GenSigSendOnInit" SG_ 2158813184 ODIIIPC_ODIInd32 1;
BA_ "VNSigInfotainment" SG_ 2158813184 ODIIIPC_ODIInd32 1;
BA_ "SignalType" SG_ 2158813184 ODIIIPC_ODIInd32 "BLN";
BA_ "PacketOrder" SG_ 2158813184 ODIIIPC_ODIInd32 33;
BA_ "SignalLongName" SG_ 2158813184 ODIIIPC_ODIInd32 "Open Display Interface Indication IPC : Open Display Interface Indication 32";
BA_ "VNSigAllNodes" SG_ 2158813184 ODIIIPC_ODIInd32 1;
BA_ "GenSigSendType" SG_ 2158813184 ODIIIPC_ODIInd31 10;
BA_ "GenSigSendOnInit" SG_ 2158813184 ODIIIPC_ODIInd31 1;
BA_ "VNSigInfotainment" SG_ 2158813184 ODIIIPC_ODIInd31 1;
BA_ "SignalType" SG_ 2158813184 ODIIIPC_ODIInd31 "BLN";
BA_ "PacketOrder" SG_ 2158813184 ODIIIPC_ODIInd31 32;
BA_ "SignalLongName" SG_ 2158813184 ODIIIPC_ODIInd31 "Open Display Interface Indication IPC : Open Display Interface Indication 31";
BA_ "VNSigAllNodes" SG_ 2158813184 ODIIIPC_ODIInd31 1;
BA_ "GenSigSendType" SG_ 2158813184 ODIIIPC_ODIInd30 10;
BA_ "GenSigSendOnInit" SG_ 2158813184 ODIIIPC_ODIInd30 1;
BA_ "VNSigInfotainment" SG_ 2158813184 ODIIIPC_ODIInd30 1;
BA_ "SignalType" SG_ 2158813184 ODIIIPC_ODIInd30 "BLN";
BA_ "PacketOrder" SG_ 2158813184 ODIIIPC_ODIInd30 31;
BA_ "SignalLongName" SG_ 2158813184 ODIIIPC_ODIInd30 "Open Display Interface Indication IPC : Open Display Interface Indication 30";
BA_ "VNSigAllNodes" SG_ 2158813184 ODIIIPC_ODIInd30 1;
BA_ "GenSigSendType" SG_ 2158813184 ODIIIPC_ODIInd29 10;
BA_ "GenSigSendOnInit" SG_ 2158813184 ODIIIPC_ODIInd29 1;
BA_ "VNSigInfotainment" SG_ 2158813184 ODIIIPC_ODIInd29 1;
BA_ "SignalType" SG_ 2158813184 ODIIIPC_ODIInd29 "BLN";
BA_ "PacketOrder" SG_ 2158813184 ODIIIPC_ODIInd29 30;
BA_ "SignalLongName" SG_ 2158813184 ODIIIPC_ODIInd29 "Open Display Interface Indication IPC : Open Display Interface Indication 29";
BA_ "VNSigAllNodes" SG_ 2158813184 ODIIIPC_ODIInd29 1;
BA_ "GenSigSendType" SG_ 2158813184 ODIIIPC_ODIInd28 10;
BA_ "GenSigSendOnInit" SG_ 2158813184 ODIIIPC_ODIInd28 1;
BA_ "VNSigInfotainment" SG_ 2158813184 ODIIIPC_ODIInd28 1;
BA_ "SignalType" SG_ 2158813184 ODIIIPC_ODIInd28 "BLN";
BA_ "PacketOrder" SG_ 2158813184 ODIIIPC_ODIInd28 29;
BA_ "SignalLongName" SG_ 2158813184 ODIIIPC_ODIInd28 "Open Display Interface Indication IPC : Open Display Interface Indication 28";
BA_ "VNSigAllNodes" SG_ 2158813184 ODIIIPC_ODIInd28 1;
BA_ "GenSigSendType" SG_ 2158813184 ODIIIPC_ODIInd27 10;
BA_ "GenSigSendOnInit" SG_ 2158813184 ODIIIPC_ODIInd27 1;
BA_ "VNSigInfotainment" SG_ 2158813184 ODIIIPC_ODIInd27 1;
BA_ "SignalType" SG_ 2158813184 ODIIIPC_ODIInd27 "BLN";
BA_ "PacketOrder" SG_ 2158813184 ODIIIPC_ODIInd27 28;
BA_ "SignalLongName" SG_ 2158813184 ODIIIPC_ODIInd27 "Open Display Interface Indication IPC : Open Display Interface Indication 27";
BA_ "VNSigAllNodes" SG_ 2158813184 ODIIIPC_ODIInd27 1;
BA_ "GenSigSendType" SG_ 2158813184 ODIIIPC_ODIInd26 10;
BA_ "GenSigSendOnInit" SG_ 2158813184 ODIIIPC_ODIInd26 1;
BA_ "VNSigInfotainment" SG_ 2158813184 ODIIIPC_ODIInd26 1;
BA_ "SignalType" SG_ 2158813184 ODIIIPC_ODIInd26 "BLN";
BA_ "PacketOrder" SG_ 2158813184 ODIIIPC_ODIInd26 27;
BA_ "SignalLongName" SG_ 2158813184 ODIIIPC_ODIInd26 "Open Display Interface Indication IPC : Open Display Interface Indication 26";
BA_ "VNSigAllNodes" SG_ 2158813184 ODIIIPC_ODIInd26 1;
BA_ "GenSigSendType" SG_ 2158813184 ODIIIPC_ODIInd25 10;
BA_ "GenSigSendOnInit" SG_ 2158813184 ODIIIPC_ODIInd25 1;
BA_ "VNSigInfotainment" SG_ 2158813184 ODIIIPC_ODIInd25 1;
BA_ "SignalType" SG_ 2158813184 ODIIIPC_ODIInd25 "BLN";
BA_ "PacketOrder" SG_ 2158813184 ODIIIPC_ODIInd25 26;
BA_ "SignalLongName" SG_ 2158813184 ODIIIPC_ODIInd25 "Open Display Interface Indication IPC : Open Display Interface Indication 25";
BA_ "VNSigAllNodes" SG_ 2158813184 ODIIIPC_ODIInd25 1;
BA_ "GenSigSendType" SG_ 2158813184 ODIIIPC_ODIInd24 10;
BA_ "GenSigSendOnInit" SG_ 2158813184 ODIIIPC_ODIInd24 1;
BA_ "VNSigInfotainment" SG_ 2158813184 ODIIIPC_ODIInd24 1;
BA_ "SignalType" SG_ 2158813184 ODIIIPC_ODIInd24 "BLN";
BA_ "PacketOrder" SG_ 2158813184 ODIIIPC_ODIInd24 25;
BA_ "SignalLongName" SG_ 2158813184 ODIIIPC_ODIInd24 "Open Display Interface Indication IPC : Open Display Interface Indication 24";
BA_ "VNSigAllNodes" SG_ 2158813184 ODIIIPC_ODIInd24 1;
BA_ "GenSigSendType" SG_ 2158813184 ODIIIPC_ODIInd23 10;
BA_ "GenSigSendOnInit" SG_ 2158813184 ODIIIPC_ODIInd23 1;
BA_ "VNSigInfotainment" SG_ 2158813184 ODIIIPC_ODIInd23 1;
BA_ "SignalType" SG_ 2158813184 ODIIIPC_ODIInd23 "BLN";
BA_ "PacketOrder" SG_ 2158813184 ODIIIPC_ODIInd23 24;
BA_ "SignalLongName" SG_ 2158813184 ODIIIPC_ODIInd23 "Open Display Interface Indication IPC : Open Display Interface Indication 23";
BA_ "VNSigAllNodes" SG_ 2158813184 ODIIIPC_ODIInd23 1;
BA_ "GenSigSendType" SG_ 2158813184 ODIIIPC_ODIInd22 10;
BA_ "GenSigSendOnInit" SG_ 2158813184 ODIIIPC_ODIInd22 1;
BA_ "VNSigInfotainment" SG_ 2158813184 ODIIIPC_ODIInd22 1;
BA_ "SignalType" SG_ 2158813184 ODIIIPC_ODIInd22 "BLN";
BA_ "PacketOrder" SG_ 2158813184 ODIIIPC_ODIInd22 23;
BA_ "SignalLongName" SG_ 2158813184 ODIIIPC_ODIInd22 "Open Display Interface Indication IPC : Open Display Interface Indication 22";
BA_ "VNSigAllNodes" SG_ 2158813184 ODIIIPC_ODIInd22 1;
BA_ "GenSigSendType" SG_ 2158813184 ODIIIPC_ODIInd21 10;
BA_ "GenSigSendOnInit" SG_ 2158813184 ODIIIPC_ODIInd21 1;
BA_ "VNSigInfotainment" SG_ 2158813184 ODIIIPC_ODIInd21 1;
BA_ "SignalType" SG_ 2158813184 ODIIIPC_ODIInd21 "BLN";
BA_ "PacketOrder" SG_ 2158813184 ODIIIPC_ODIInd21 22;
BA_ "SignalLongName" SG_ 2158813184 ODIIIPC_ODIInd21 "Open Display Interface Indication IPC : Open Display Interface Indication 21";
BA_ "VNSigAllNodes" SG_ 2158813184 ODIIIPC_ODIInd21 1;
BA_ "GenSigSendType" SG_ 2158813184 ODIIIPC_ODIInd20 10;
BA_ "GenSigSendOnInit" SG_ 2158813184 ODIIIPC_ODIInd20 1;
BA_ "VNSigInfotainment" SG_ 2158813184 ODIIIPC_ODIInd20 1;
BA_ "SignalType" SG_ 2158813184 ODIIIPC_ODIInd20 "BLN";
BA_ "PacketOrder" SG_ 2158813184 ODIIIPC_ODIInd20 21;
BA_ "SignalLongName" SG_ 2158813184 ODIIIPC_ODIInd20 "Open Display Interface Indication IPC : Open Display Interface Indication 20";
BA_ "VNSigAllNodes" SG_ 2158813184 ODIIIPC_ODIInd20 1;
BA_ "GenSigSendType" SG_ 2158813184 ODIIIPC_ODIInd19 10;
BA_ "GenSigSendOnInit" SG_ 2158813184 ODIIIPC_ODIInd19 1;
BA_ "VNSigInfotainment" SG_ 2158813184 ODIIIPC_ODIInd19 1;
BA_ "SignalType" SG_ 2158813184 ODIIIPC_ODIInd19 "BLN";
BA_ "PacketOrder" SG_ 2158813184 ODIIIPC_ODIInd19 20;
BA_ "SignalLongName" SG_ 2158813184 ODIIIPC_ODIInd19 "Open Display Interface Indication IPC : Open Display Interface Indication 19";
BA_ "VNSigAllNodes" SG_ 2158813184 ODIIIPC_ODIInd19 1;
BA_ "GenSigSendType" SG_ 2158813184 ODIIIPC_ODIInd18 10;
BA_ "GenSigSendOnInit" SG_ 2158813184 ODIIIPC_ODIInd18 1;
BA_ "VNSigInfotainment" SG_ 2158813184 ODIIIPC_ODIInd18 1;
BA_ "SignalType" SG_ 2158813184 ODIIIPC_ODIInd18 "BLN";
BA_ "PacketOrder" SG_ 2158813184 ODIIIPC_ODIInd18 19;
BA_ "SignalLongName" SG_ 2158813184 ODIIIPC_ODIInd18 "Open Display Interface Indication IPC : Open Display Interface Indication 18";
BA_ "VNSigAllNodes" SG_ 2158813184 ODIIIPC_ODIInd18 1;
BA_ "GenSigSendType" SG_ 2158813184 ODIIIPC_ODIInd17 10;
BA_ "GenSigSendOnInit" SG_ 2158813184 ODIIIPC_ODIInd17 1;
BA_ "VNSigInfotainment" SG_ 2158813184 ODIIIPC_ODIInd17 1;
BA_ "SignalType" SG_ 2158813184 ODIIIPC_ODIInd17 "BLN";
BA_ "PacketOrder" SG_ 2158813184 ODIIIPC_ODIInd17 18;
BA_ "SignalLongName" SG_ 2158813184 ODIIIPC_ODIInd17 "Open Display Interface Indication IPC : Open Display Interface Indication 17";
BA_ "VNSigAllNodes" SG_ 2158813184 ODIIIPC_ODIInd17 1;
BA_ "GenSigSendType" SG_ 2158813184 ODIIIPC_ODIInd16 10;
BA_ "GenSigSendOnInit" SG_ 2158813184 ODIIIPC_ODIInd16 1;
BA_ "VNSigInfotainment" SG_ 2158813184 ODIIIPC_ODIInd16 1;
BA_ "SignalType" SG_ 2158813184 ODIIIPC_ODIInd16 "BLN";
BA_ "PacketOrder" SG_ 2158813184 ODIIIPC_ODIInd16 17;
BA_ "SignalLongName" SG_ 2158813184 ODIIIPC_ODIInd16 "Open Display Interface Indication IPC : Open Display Interface Indication 16";
BA_ "VNSigAllNodes" SG_ 2158813184 ODIIIPC_ODIInd16 1;
BA_ "GenSigSendType" SG_ 2158813184 ODIIIPC_ODIInd15 10;
BA_ "GenSigSendOnInit" SG_ 2158813184 ODIIIPC_ODIInd15 1;
BA_ "VNSigInfotainment" SG_ 2158813184 ODIIIPC_ODIInd15 1;
BA_ "SignalType" SG_ 2158813184 ODIIIPC_ODIInd15 "BLN";
BA_ "PacketOrder" SG_ 2158813184 ODIIIPC_ODIInd15 16;
BA_ "SignalLongName" SG_ 2158813184 ODIIIPC_ODIInd15 "Open Display Interface Indication IPC : Open Display Interface Indication 15";
BA_ "VNSigAllNodes" SG_ 2158813184 ODIIIPC_ODIInd15 1;
BA_ "GenSigSendType" SG_ 2158813184 ODIIIPC_ODIInd14 10;
BA_ "GenSigSendOnInit" SG_ 2158813184 ODIIIPC_ODIInd14 1;
BA_ "VNSigInfotainment" SG_ 2158813184 ODIIIPC_ODIInd14 1;
BA_ "SignalType" SG_ 2158813184 ODIIIPC_ODIInd14 "BLN";
BA_ "PacketOrder" SG_ 2158813184 ODIIIPC_ODIInd14 15;
BA_ "SignalLongName" SG_ 2158813184 ODIIIPC_ODIInd14 "Open Display Interface Indication IPC : Open Display Interface Indication 14";
BA_ "VNSigAllNodes" SG_ 2158813184 ODIIIPC_ODIInd14 1;
BA_ "GenSigSendType" SG_ 2158813184 ODIIIPC_ODIInd13 10;
BA_ "GenSigSendOnInit" SG_ 2158813184 ODIIIPC_ODIInd13 1;
BA_ "VNSigInfotainment" SG_ 2158813184 ODIIIPC_ODIInd13 1;
BA_ "SignalType" SG_ 2158813184 ODIIIPC_ODIInd13 "BLN";
BA_ "PacketOrder" SG_ 2158813184 ODIIIPC_ODIInd13 14;
BA_ "SignalLongName" SG_ 2158813184 ODIIIPC_ODIInd13 "Open Display Interface Indication IPC : Open Display Interface Indication 13";
BA_ "VNSigAllNodes" SG_ 2158813184 ODIIIPC_ODIInd13 1;
BA_ "GenSigSendType" SG_ 2158813184 ODIIIPC_ODIInd12 10;
BA_ "GenSigSendOnInit" SG_ 2158813184 ODIIIPC_ODIInd12 1;
BA_ "VNSigInfotainment" SG_ 2158813184 ODIIIPC_ODIInd12 1;
BA_ "SignalType" SG_ 2158813184 ODIIIPC_ODIInd12 "BLN";
BA_ "PacketOrder" SG_ 2158813184 ODIIIPC_ODIInd12 13;
BA_ "SignalLongName" SG_ 2158813184 ODIIIPC_ODIInd12 "Open Display Interface Indication IPC : Open Display Interface Indication 12";
BA_ "VNSigAllNodes" SG_ 2158813184 ODIIIPC_ODIInd12 1;
BA_ "GenSigSendType" SG_ 2158813184 ODIIIPC_ODIInd11 10;
BA_ "GenSigSendOnInit" SG_ 2158813184 ODIIIPC_ODIInd11 1;
BA_ "VNSigInfotainment" SG_ 2158813184 ODIIIPC_ODIInd11 1;
BA_ "SignalType" SG_ 2158813184 ODIIIPC_ODIInd11 "BLN";
BA_ "PacketOrder" SG_ 2158813184 ODIIIPC_ODIInd11 12;
BA_ "SignalLongName" SG_ 2158813184 ODIIIPC_ODIInd11 "Open Display Interface Indication IPC : Open Display Interface Indication 11";
BA_ "VNSigAllNodes" SG_ 2158813184 ODIIIPC_ODIInd11 1;
BA_ "GenSigSendType" SG_ 2158813184 ODIIIPC_ODIInd10 10;
BA_ "GenSigSendOnInit" SG_ 2158813184 ODIIIPC_ODIInd10 1;
BA_ "VNSigInfotainment" SG_ 2158813184 ODIIIPC_ODIInd10 1;
BA_ "SignalType" SG_ 2158813184 ODIIIPC_ODIInd10 "BLN";
BA_ "PacketOrder" SG_ 2158813184 ODIIIPC_ODIInd10 11;
BA_ "SignalLongName" SG_ 2158813184 ODIIIPC_ODIInd10 "Open Display Interface Indication IPC : Open Display Interface Indication 10";
BA_ "VNSigAllNodes" SG_ 2158813184 ODIIIPC_ODIInd10 1;
BA_ "GenSigSendType" SG_ 2158813184 ODIIIPC_ODIInd2 10;
BA_ "GenSigSendOnInit" SG_ 2158813184 ODIIIPC_ODIInd2 1;
BA_ "VNSigInfotainment" SG_ 2158813184 ODIIIPC_ODIInd2 1;
BA_ "SignalType" SG_ 2158813184 ODIIIPC_ODIInd2 "BLN";
BA_ "PacketOrder" SG_ 2158813184 ODIIIPC_ODIInd2 3;
BA_ "SignalLongName" SG_ 2158813184 ODIIIPC_ODIInd2 "Open Display Interface Indication IPC : Open Display Interface Indication 2";
BA_ "VNSigAllNodes" SG_ 2158813184 ODIIIPC_ODIInd2 1;
BA_ "GenSigSendType" SG_ 2158813184 ODIIIPC_ODIInd1 10;
BA_ "GenSigSendOnInit" SG_ 2158813184 ODIIIPC_ODIInd1 1;
BA_ "VNSigInfotainment" SG_ 2158813184 ODIIIPC_ODIInd1 1;
BA_ "SignalType" SG_ 2158813184 ODIIIPC_ODIInd1 "BLN";
BA_ "PacketOrder" SG_ 2158813184 ODIIIPC_ODIInd1 2;
BA_ "SignalLongName" SG_ 2158813184 ODIIIPC_ODIInd1 "Open Display Interface Indication IPC : Open Display Interface Indication 1";
BA_ "VNSigAllNodes" SG_ 2158813184 ODIIIPC_ODIInd1 1;
BA_ "GenSigSendType" SG_ 2158813184 ODIIIPC_FUCID 12;
BA_ "GenSigSendOnInit" SG_ 2158813184 ODIIIPC_FUCID 1;
BA_ "VNSigInfotainment" SG_ 2158813184 ODIIIPC_FUCID 1;
BA_ "SignalType" SG_ 2158813184 ODIIIPC_FUCID "UNM";
BA_ "PacketOrder" SG_ 2158813184 ODIIIPC_FUCID 1;
BA_ "SignalLongName" SG_ 2158813184 ODIIIPC_FUCID "Open Display Interface Indication IPC : Functional Unit Class ID";
BA_ "VNSigAllNodes" SG_ 2158813184 ODIIIPC_FUCID 1;
BA_REL_ "GenSigSuprvResp" BU_SG_REL_ VIS2_LS SG_ 2151948288 DrvDrowDetCstStRq 1;
BA_REL_ "GenSigSuprvResp" BU_SG_REL_ FCM_LS SG_ 2151948288 DrvDrowDetCstStRq 1;
BA_REL_ "GenSigSuprvResp" BU_SG_REL_ BCM_LS SG_ 2149728256 PrtyChrgStPnt 1;
BA_REL_ "GenSigSuprvResp" BU_SG_REL_ IPC_LS SG_ 2149728256 PrtyChrgStPnt 1;
BA_REL_ "GenSigSuprvResp" BU_SG_REL_ CSM_LS SG_ 2149728256 PrtyChrgStPnt 1;
BA_REL_ "GenSigSuprvResp" BU_SG_REL_ RadioHead_LS SG_ 2149728256 PrtyChrgStPnt 1;
BA_REL_ "GenSigSuprvResp" BU_SG_REL_ BCM_LS SG_ 2149728256 PrtyChrgActIO 1;
BA_REL_ "GenSigSuprvResp" BU_SG_REL_ IPC_LS SG_ 2149728256 PrtyChrgActIO 1;
BA_REL_ "GenSigSuprvResp" BU_SG_REL_ BCM_LS SG_ 2149728256 PrtyChrgAct 1;
BA_REL_ "GenSigSuprvResp" BU_SG_REL_ CSM_LS SG_ 2149728256 PrtyChrgAct 1;
BA_REL_ "GenSigSuprvResp" BU_SG_REL_ RadioHead_LS SG_ 2149728256 PrtyChrgAct 1;
BA_REL_ "GenSigSuprvResp" BU_SG_REL_ BCM_LS SG_ 2149728256 HVChrgPwrLvl 1;
BA_REL_ "GenSigSuprvResp" BU_SG_REL_ CSM_LS SG_ 2149728256 HVChrgPwrLvl 1;
BA_REL_ "GenSigSuprvResp" BU_SG_REL_ RadioHead_LS SG_ 2149728256 HVChrgPwrLvl 1;
BA_REL_ "GenSigSuprvResp" BU_SG_REL_ RadioHead_LS SG_ 2149728256 HVChrgPwrLvl 1;
BA_REL_ "GenSigSuprvResp" BU_SG_REL_ IPC_LS SG_ 2149728256 HVChrgPwrLvl 1;
BA_REL_ "GenSigSuprvResp" BU_SG_REL_ CSM_LS SG_ 2149728256 ChgCdTfAlCzStAvbl 1;
BA_REL_ "GenSigSuprvResp" BU_SG_REL_ RadioHead_LS SG_ 2149728256 ChgCdTfAlCzStAvbl 1;
BA_REL_ "GenSigSuprvResp" BU_SG_REL_ RadioHead_LS SG_ 2149728256 ChgCdTfAlCzStAvbl 1;
BA_REL_ "GenSigSuprvResp" BU_SG_REL_ CSM_LS SG_ 2149728256 ChgCdTfAlCzCrStVal 1;
BA_REL_ "GenSigSuprvResp" BU_SG_REL_ RadioHead_LS SG_ 2149728256 ChgCdTfAlCzCrStVal 1;
BA_REL_ "GenSigSuprvResp" BU_SG_REL_ RadioHead_LS SG_ 2149728256 ChgCdTfAlCzCrStVal 1;
BA_REL_ "GenSigSuprvResp" BU_SG_REL_ CSM_LS SG_ 2149728256 ChgPwLsAlCzStAvbl 1;
BA_REL_ "GenSigSuprvResp" BU_SG_REL_ RadioHead_LS SG_ 2149728256 ChgPwLsAlCzStAvbl 1;
BA_REL_ "GenSigSuprvResp" BU_SG_REL_ RadioHead_LS SG_ 2149728256 ChgPwLsAlCzStAvbl 1;
BA_REL_ "GenSigSuprvResp" BU_SG_REL_ CSM_LS SG_ 2149728256 ChgPwLsAlCzCrStVal 1;
BA_REL_ "GenSigSuprvResp" BU_SG_REL_ RadioHead_LS SG_ 2149728256 ChgPwLsAlCzCrStVal 1;
BA_REL_ "GenSigSuprvResp" BU_SG_REL_ RadioHead_LS SG_ 2149728256 ChgPwLsAlCzCrStVal 1;
BA_REL_ "GenSigSuprvResp" BU_SG_REL_ TCP_LS SG_ 2150023168 OffBrdVehImmbNot 1;
BA_REL_ "GenSigSuprvResp" BU_SG_REL_ TCP_LS SG_ 2150023168 OffBrdVehImmbNot 1;
BA_REL_ "GenSigSuprvResp" BU_SG_REL_ ONSTAR_LS SG_ 2150023168 OffBrdVehImmbNot 1;
BA_REL_ "GenSigSuprvResp" BU_SG_REL_ ONSTAR_LS SG_ 2150023168 OffBrdVehImmbNot 1;
BA_REL_ "GenSigSuprvResp" BU_SG_REL_ IPC_LS SG_ 2150023168 ElecPrplsnMtrTach 1;
BA_REL_ "GenSigSuprvResp" BU_SG_REL_ CSM_LS SG_ 2153988096 EUS_TtEngyUsgScrAvVal 1;
BA_REL_ "GenSigSuprvResp" BU_SG_REL_ RadioHead_LS SG_ 2153988096 EUS_TtEngyUsgScrAvVal 1;
BA_REL_ "GenSigSuprvResp" BU_SG_REL_ CSM_LS SG_ 2153988096 EUS_ITEngyUsgScrAvVal 1;
BA_REL_ "GenSigSuprvResp" BU_SG_REL_ RadioHead_LS SG_ 2153988096 EUS_ITEngyUsgScrAvVal 1;
BA_REL_ "GenSigSuprvResp" BU_SG_REL_ CSM_LS SG_ 2153988096 EUS_OTEngyUsgScrAvVal 1;
BA_REL_ "GenSigSuprvResp" BU_SG_REL_ RadioHead_LS SG_ 2153988096 EUS_OTEngyUsgScrAvVal 1;
BA_REL_ "GenSigSuprvResp" BU_SG_REL_ CSM_LS SG_ 2153988096 EUS_TrEngyUsgScrAvVal 1;
BA_REL_ "GenSigSuprvResp" BU_SG_REL_ RadioHead_LS SG_ 2153988096 EUS_TrEngyUsgScrAvVal 1;
BA_REL_ "GenSigSuprvResp" BU_SG_REL_ CSM_LS SG_ 2153988096 EUS_TcEngyUsgScrAvVal 1;
BA_REL_ "GenSigSuprvResp" BU_SG_REL_ RadioHead_LS SG_ 2153988096 EUS_TcEngyUsgScrAvVal 1;
BA_REL_ "GenSigSuprvResp" BU_SG_REL_ IPC_LS SG_ 2155233280 NtrlGrWrngIO 1;
BA_REL_ "GenSigSuprvResp" BU_SG_REL_ CSM_LS SG_ 2155233280 RtBsChrgCmplnTmPrfRsp 1;
BA_REL_ "GenSigSuprvResp" BU_SG_REL_ RadioHead_LS SG_ 2155233280 RtBsChrgCmplnTmPrfRsp 1;
BA_REL_ "GenSigSuprvResp" BU_SG_REL_ IPC_LS SG_ 2155233280 EngRnngDutoVehSpdIO 1;
BA_REL_ "GenSigSuprvResp" BU_SG_REL_ CSM_LS SG_ 2155233280 ChrgCyclFuelEcn 1;
BA_REL_ "GenSigSuprvResp" BU_SG_REL_ RadioHead_LS SG_ 2155233280 ChrgCyclFuelEcn 1;
BA_REL_ "GenSigSuprvResp" BU_SG_REL_ CSM_LS SG_ 2155233280 LiftimeFuelEcnEquiv 1;
BA_REL_ "GenSigSuprvResp" BU_SG_REL_ RadioHead_LS SG_ 2155233280 LiftimeFuelEcnEquiv 1;
BA_REL_ "GenSigSuprvResp" BU_SG_REL_ IPC_LS SG_ 2155233280 ShftPrkIO_3B2 1;
BA_REL_ "GenSigSuprvResp" BU_SG_REL_ CSM_LS SG_ 2155233280 LftmFuelEcon 1;
BA_REL_ "GenSigSuprvResp" BU_SG_REL_ RadioHead_LS SG_ 2155233280 LftmFuelEcon 1;
BA_REL_ "GenSigSuprvResp" BU_SG_REL_ RadioHead_LS SG_ 2155233280 LftmFuelEcon 1;
BA_REL_ "GenSigSuprvResp" BU_SG_REL_ IPC_LS SG_ 2155233280 NtrlCstdwnCrtMdActvIO 1;
BA_REL_ "GenSigSuprvResp" BU_SG_REL_ IPC_LS SG_ 2152759296 PedWrnIndReq 1;
BA_REL_ "GenSigSuprvResp" BU_SG_REL_ IPC_LS SG_ 2152759296 FrtCmrBlckdIO 1;
BA_REL_ "GenSigSuprvResp" BU_SG_REL_ VIS2_LS SG_ 2150891520 DgtlMapEffSpdLmt 1;
BA_REL_ "GenSigSuprvResp" BU_SG_REL_ FCM_LS SG_ 2150891520 DgtlMapEffSpdLmt 1;
BA_REL_ "GenSigSuprvResp" BU_SG_REL_ VIS2_LS SG_ 2150891520 DgtlMapEffSpdLmtTyp 1;
BA_REL_ "GenSigSuprvResp" BU_SG_REL_ FCM_LS SG_ 2150891520 DgtlMapEffSpdLmtTyp 1;
BA_REL_ "GenSigSuprvResp" BU_SG_REL_ VIS2_LS SG_ 2150891520 DgtlMapSpdCat 1;
BA_REL_ "GenSigSuprvResp" BU_SG_REL_ FCM_LS SG_ 2150891520 DgtlMapSpdCat 1;
BA_REL_ "GenSigSuprvResp" BU_SG_REL_ VIS2_LS SG_ 2150891520 DgtlMapVerQtr 1;
BA_REL_ "GenSigSuprvResp" BU_SG_REL_ FCM_LS SG_ 2150891520 DgtlMapVerQtr 1;
BA_REL_ "GenSigSuprvResp" BU_SG_REL_ VIS2_LS SG_ 2150891520 DgtlMapVerYr 1;
BA_REL_ "GenSigSuprvResp" BU_SG_REL_ FCM_LS SG_ 2150891520 DgtlMapVerYr 1;
BA_REL_ "GenSigSuprvResp" BU_SG_REL_ VIS2_LS SG_ 2150891520 DgtlMapDrvngSd 1;
BA_REL_ "GenSigSuprvResp" BU_SG_REL_ FCM_LS SG_ 2150891520 DgtlMapDrvngSd 1;
BA_REL_ "GenSigSuprvResp" BU_SG_REL_ V2V_LS SG_ 2151751680 HptcStVbnStat 1;
BA_REL_ "GenSigSuprvResp" BU_SG_REL_ VPM_LS SG_ 2151751680 HptcStVbnStat 1;
BA_REL_ "GenSigSuprvResp" BU_SG_REL_ SBZA_R_LS SG_ 2151751680 HptcStVbnStat 1;
BA_REL_ "GenSigSuprvResp" BU_SG_REL_ SBZA_L_LS SG_ 2151751680 HptcStVbnStat 1;
BA_REL_ "GenSigSuprvResp" BU_SG_REL_ UPA_LS SG_ 2151751680 HptcStVbnStat 1;
BA_REL_ "GenSigSuprvResp" BU_SG_REL_ APA_LS SG_ 2151751680 HptcStVbnStat 1;
BA_REL_ "GenSigSuprvResp" BU_SG_REL_ VIS2_LS SG_ 2151751680 HptcStVbnStat 1;
BA_REL_ "GenSigSuprvResp" BU_SG_REL_ VIS2_LS SG_ 2151751680 HptcStVbnStat 1;
BA_REL_ "GenSigSuprvResp" BU_SG_REL_ FCM_LS SG_ 2151751680 HptcStVbnStat 1;
BA_REL_ "GenSigSuprvResp" BU_SG_REL_ FCM_LS SG_ 2151751680 HptcStVbnStat 1;
BA_REL_ "GenSigSuprvResp" BU_SG_REL_ FCM_LS SG_ 2151751680 HptcStVbnStat 1;
BA_REL_ "GenSigSuprvResp" BU_SG_REL_ EOCM_F_LS SG_ 2151751680 HptcStVbnStat 1;
BA_REL_ "GenSigSuprvResp" BU_SG_REL_ EOCM_F_LS SG_ 2151751680 HptcStVbnStat 1;
BA_REL_ "GenSigSuprvResp" BU_SG_REL_ EOCM_F_LS SG_ 2151751680 HptcStVbnStat 1;
BA_REL_ "GenSigSuprvResp" BU_SG_REL_ EOCM_F_LS SG_ 2151751680 HptcStVbnStat 1;
BA_REL_ "GenSigSuprvResp" BU_SG_REL_ EOCM_F_LS SG_ 2151751680 HptcStVbnStat 1;
BA_REL_ "GenSigSuprvResp" BU_SG_REL_ EOCM_F_LS SG_ 2151751680 HptcStVbnStat 1;
BA_REL_ "GenSigSuprvResp" BU_SG_REL_ BCM_LS SG_ 2151751680 HptcStVbnStat 1;
BA_REL_ "GenSigSuprvResp" BU_SG_REL_ V2V_LS SG_ 2151751680 HptcStFldIO 1;
BA_REL_ "GenSigSuprvResp" BU_SG_REL_ VIS2_LS SG_ 2151751680 HptcStFldIO 1;
BA_REL_ "GenSigSuprvResp" BU_SG_REL_ IPC_LS SG_ 2151751680 HptcStFldIO 1;
BA_REL_ "GenSigSuprvResp" BU_SG_REL_ FCM_LS SG_ 2151751680 HptcStFldIO 1;
BA_REL_ "GenSigSuprvResp" BU_SG_REL_ EOCM2A_K2_LS SG_ 2151751680 CrshAlrtDrvrSlctdType 1;
BA_REL_ "GenSigSuprvResp" BU_SG_REL_ EOCM2B_K2_LS SG_ 2151751680 CrshAlrtDrvrSlctdType 1;
BA_REL_ "GenSigSuprvResp" BU_SG_REL_ V2V_LS SG_ 2151751680 CrshAlrtDrvrSlctdType 1;
BA_REL_ "GenSigSuprvResp" BU_SG_REL_ VPM_LS SG_ 2151751680 CrshAlrtDrvrSlctdType 1;
BA_REL_ "GenSigSuprvResp" BU_SG_REL_ BCM_LS SG_ 2151751680 CrshAlrtDrvrSlctdType 1;
BA_REL_ "GenSigSuprvResp" BU_SG_REL_ EOCM_F_LS SG_ 2151751680 CrshAlrtDrvrSlctdType 1;
BA_REL_ "GenSigSuprvResp" BU_SG_REL_ EOCM_F_LS SG_ 2151751680 CrshAlrtDrvrSlctdType 1;
BA_REL_ "GenSigSuprvResp" BU_SG_REL_ EOCM_F_LS SG_ 2151751680 CrshAlrtDrvrSlctdType 1;
BA_REL_ "GenSigSuprvResp" BU_SG_REL_ EOCM_F_LS SG_ 2151751680 CrshAlrtDrvrSlctdType 1;
BA_REL_ "GenSigSuprvResp" BU_SG_REL_ EOCM_F_LS SG_ 2151751680 CrshAlrtDrvrSlctdType 1;
BA_REL_ "GenSigSuprvResp" BU_SG_REL_ EOCM_F_LS SG_ 2151751680 CrshAlrtDrvrSlctdType 1;
BA_REL_ "GenSigSuprvResp" BU_SG_REL_ EOCM2A_K2_LS SG_ 2151751680 CrshAlrtStPrsnt 1;
BA_REL_ "GenSigSuprvResp" BU_SG_REL_ EOCM2B_K2_LS SG_ 2151751680 CrshAlrtStPrsnt 1;
BA_REL_ "GenSigSuprvResp" BU_SG_REL_ V2V_LS SG_ 2151751680 CrshAlrtStPrsnt 1;
BA_REL_ "GenSigSuprvResp" BU_SG_REL_ EOCM_F_LS SG_ 2151751680 CrshAlrtStPrsnt 1;
BA_REL_ "GenSigSuprvResp" BU_SG_REL_ EOCM_F_LS SG_ 2151751680 CrshAlrtStPrsnt 1;
BA_REL_ "GenSigSuprvResp" BU_SG_REL_ BCM_LS SG_ 2155536384 RevClnMtgnBrkReqAct 1;
BA_REL_ "GenSigSuprvResp" BU_SG_REL_ IPC_LS SG_ 2155536384 TnDrvRIMOffUnbIO 1;
BA_REL_ "GenSigSuprvResp" BU_SG_REL_ MSM_P_LS SG_ 2151432192 ACCHptcStVbnRqSeqN 1;
BA_REL_ "GenSigSuprvResp" BU_SG_REL_ MSM_LS SG_ 2151432192 ACCHptcStVbnRqSeqN 1;
BA_REL_ "GenSigSuprvResp" BU_SG_REL_ MSM_P_LS SG_ 2151432192 ACCHptcStVbnReq 1;
BA_REL_ "GenSigSuprvResp" BU_SG_REL_ MSM_LS SG_ 2151432192 ACCHptcStVbnReq 1;
BA_REL_ "GenSigSuprvResp" BU_SG_REL_ MSM_P_LS SG_ 2151415808 RgtLnChgThrtHptStRqSN 1;
BA_REL_ "GenSigSuprvResp" BU_SG_REL_ MSM_LS SG_ 2151415808 RgtLnChgThrtHptStRqSN 1;
BA_REL_ "GenSigSuprvResp" BU_SG_REL_ MSM_P_LS SG_ 2151415808 RgtLnChgThrtHptStRq 1;
BA_REL_ "GenSigSuprvResp" BU_SG_REL_ MSM_LS SG_ 2151415808 RgtLnChgThrtHptStRq 1;
BA_REL_ "GenSigSuprvResp" BU_SG_REL_ MSM_P_LS SG_ 2151415808 LftLnChgThrtHptStRqSN 1;
BA_REL_ "GenSigSuprvResp" BU_SG_REL_ MSM_LS SG_ 2151415808 LftLnChgThrtHptStRqSN 1;
BA_REL_ "GenSigSuprvResp" BU_SG_REL_ MSM_P_LS SG_ 2151415808 LftLnChgThrtHptStRq 1;
BA_REL_ "GenSigSuprvResp" BU_SG_REL_ MSM_LS SG_ 2151415808 LftLnChgThrtHptStRq 1;
BA_REL_ "GenSigSuprvResp" BU_SG_REL_ MSM_P_LS SG_ 2151415808 LDWRghtHptcStRqSN 1;
BA_REL_ "GenSigSuprvResp" BU_SG_REL_ MSM_LS SG_ 2151415808 LDWRghtHptcStRqSN 1;
BA_REL_ "GenSigSuprvResp" BU_SG_REL_ BCM_LS SG_ 2151415808 LDWRghtHptcStRq 1;
BA_REL_ "GenSigSuprvResp" BU_SG_REL_ MSM_P_LS SG_ 2151415808 LDWRghtHptcStRq 1;
BA_REL_ "GenSigSuprvResp" BU_SG_REL_ MSM_LS SG_ 2151415808 LDWRghtHptcStRq 1;
BA_REL_ "GenSigSuprvResp" BU_SG_REL_ MSM_P_LS SG_ 2151415808 LDWLftHptcStRqSN 1;
BA_REL_ "GenSigSuprvResp" BU_SG_REL_ MSM_LS SG_ 2151415808 LDWLftHptcStRqSN 1;
BA_REL_ "GenSigSuprvResp" BU_SG_REL_ BCM_LS SG_ 2151415808 LDWLftHptcStRq 1;
BA_REL_ "GenSigSuprvResp" BU_SG_REL_ MSM_P_LS SG_ 2151415808 LDWLftHptcStRq 1;
BA_REL_ "GenSigSuprvResp" BU_SG_REL_ MSM_LS SG_ 2151415808 LDWLftHptcStRq 1;
BA_REL_ "GenSigSuprvResp" BU_SG_REL_ MSM_P_LS SG_ 2151350272 FPAHptcStVbnRqSeqN 1;
BA_REL_ "GenSigSuprvResp" BU_SG_REL_ MSM_LS SG_ 2151350272 FPAHptcStVbnRqSeqN 1;
BA_REL_ "GenSigSuprvResp" BU_SG_REL_ MSM_P_LS SG_ 2151350272 FPAHptcStVbnReq 1;
BA_REL_ "GenSigSuprvResp" BU_SG_REL_ MSM_LS SG_ 2151350272 FPAHptcStVbnReq 1;
BA_REL_ "GenSigSuprvResp" BU_SG_REL_ MSM_P_LS SG_ 2151333888 RPAHptcStVbRqSeqN 1;
BA_REL_ "GenSigSuprvResp" BU_SG_REL_ MSM_LS SG_ 2151333888 RPAHptcStVbRqSeqN 1;
BA_REL_ "GenSigSuprvResp" BU_SG_REL_ MSM_P_LS SG_ 2151333888 RPAHptcStVbnReq 1;
BA_REL_ "GenSigSuprvResp" BU_SG_REL_ MSM_LS SG_ 2151333888 RPAHptcStVbnReq 1;
BA_REL_ "GenSigSuprvResp" BU_SG_REL_ BSM_LS SG_ 2151522304 ElEngyEconAvgRstRq 1;
BA_REL_ "GenSigSuprvResp" BU_SG_REL_ VICM_LS SG_ 2151522304 ElEngyEconAvgRstRq 1;
BA_REL_ "GenSigSuprvResp" BU_SG_REL_ IPC_LS SG_ 2155929600 DslExhFldDiagWrnIdRq 1;
BA_REL_ "GenSigSuprvResp" BU_SG_REL_ IPC_LS SG_ 2155929600 DslExhFluidDistTIndcmt 1;
BA_REL_ "GenSigSuprvResp" BU_SG_REL_ RadioHead_LS SG_ 2154741760 RSAPrsnt 1;
BA_REL_ "GenSigSuprvResp" BU_SG_REL_ RadioHead_LS SG_ 2154741760 RSAPrsnt 1;
BA_REL_ "GenSigSuprvResp" BU_SG_REL_ ECC_LS SG_ 2154807296 ESCMHiEleclLdReqAct 1;
BA_REL_ "GenSigSuprvResp" BU_SG_REL_ ECC_LS SG_ 2154807296 EASSI_UnsdRsrvd2 1;
BA_REL_ "GenSigSuprvResp" BU_SG_REL_ ECC_LS SG_ 2154807296 EASSI_StlDetd 1;
BA_REL_ "GenSigSuprvResp" BU_SG_REL_ ECC_LS SG_ 2154807296 EASSI_TrqDetd 1;
BA_REL_ "GenSigSuprvResp" BU_SG_REL_ ECC_LS SG_ 2154807296 EASSI_FuelReqOn 1;
BA_REL_ "GenSigSuprvResp" BU_SG_REL_ ECC_LS SG_ 2154807296 EASSI_StrtTyp 1;
BA_REL_ "GenSigSuprvResp" BU_SG_REL_ ECC_LS SG_ 2154807296 EASSI_StrtStpSt 1;
BA_REL_ "GenSigSuprvResp" BU_SG_REL_ ECC_LS SG_ 2154807296 EASSI_TorqDetdIndet 1;
BA_REL_ "GenSigSuprvResp" BU_SG_REL_ ECC_LS SG_ 2154807296 EngAutoStpNotProb 1;
BA_REL_ "GenSigSuprvResp" BU_SG_REL_ CSM_LS SG_ 2154807296 AFLMnu3CstStAvl 1;
BA_REL_ "GenSigSuprvResp" BU_SG_REL_ RadioHead_LS SG_ 2154807296 AFLMnu3CstStAvl 1;
BA_REL_ "GenSigSuprvResp" BU_SG_REL_ CSM_LS SG_ 2154807296 AFLMnu2CstStAvl 1;
BA_REL_ "GenSigSuprvResp" BU_SG_REL_ RadioHead_LS SG_ 2154807296 AFLMnu2CstStAvl 1;
BA_REL_ "GenSigSuprvResp" BU_SG_REL_ CSM_LS SG_ 2154807296 AFLGPSMnu2CstStAvl 1;
BA_REL_ "GenSigSuprvResp" BU_SG_REL_ RadioHead_LS SG_ 2154807296 AFLGPSMnu2CstStAvl 1;
BA_REL_ "GenSigSuprvResp" BU_SG_REL_ CSM_LS SG_ 2154807296 AFLGPSCstStAvl 1;
BA_REL_ "GenSigSuprvResp" BU_SG_REL_ RadioHead_LS SG_ 2154807296 AFLGPSCstStAvl 1;
BA_REL_ "GenSigSuprvResp" BU_SG_REL_ CSM_LS SG_ 2154807296 AFLGPSCstCrStVal 1;
BA_REL_ "GenSigSuprvResp" BU_SG_REL_ RadioHead_LS SG_ 2154807296 AFLGPSCstCrStVal 1;
BA_REL_ "GenSigSuprvResp" BU_SG_REL_ CSM_LS SG_ 2154807296 AFLCstStAvl 1;
BA_REL_ "GenSigSuprvResp" BU_SG_REL_ RadioHead_LS SG_ 2154807296 AFLCstStAvl 1;
BA_REL_ "GenSigSuprvResp" BU_SG_REL_ CSM_LS SG_ 2154807296 AFLCstCrStVal 1;
BA_REL_ "GenSigSuprvResp" BU_SG_REL_ RadioHead_LS SG_ 2154807296 AFLCstCrStVal 1;
BA_REL_ "GenSigSuprvResp" BU_SG_REL_ RadioHead_LS SG_ 2151079936 PDIMPrsnt 1;
BA_REL_ "GenSigSuprvResp" BU_SG_REL_ CSM_LS SG_ 2155364352 InstDrvEff 1;
BA_REL_ "GenSigSuprvResp" BU_SG_REL_ RadioHead_LS SG_ 2155364352 InstDrvEff 1;
BA_REL_ "GenSigSuprvResp" BU_SG_REL_ CSM_LS SG_ 2155364352 CstmrUsblSOC 1;
BA_REL_ "GenSigSuprvResp" BU_SG_REL_ RadioHead_LS SG_ 2155364352 CstmrUsblSOC 1;
BA_REL_ "GenSigSuprvResp" BU_SG_REL_ RadioHead_LS SG_ 2155364352 CstmrUsblSOC 1;
BA_REL_ "GenSigSuprvResp" BU_SG_REL_ IPC_LS SG_ 2155364352 CstmrUsblSOC 1;
BA_REL_ "GenSigSuprvResp" BU_SG_REL_ CSM_LS SG_ 2155364352 HybMdDisp 1;
BA_REL_ "GenSigSuprvResp" BU_SG_REL_ RadioHead_LS SG_ 2155364352 HybMdDisp 1;
BA_REL_ "GenSigSuprvResp" BU_SG_REL_ RadioHead_LS SG_ 2155364352 HybMdDisp 1;
BA_REL_ "GenSigSuprvResp" BU_SG_REL_ IPC_LS SG_ 2155364352 HybMdDisp 1;
BA_REL_ "GenSigSuprvResp" BU_SG_REL_ BCM_LS SG_ 2151505920 AutoMdSpdLmtCnfrmd 1;
BA_REL_ "GenSigSuprvResp" BU_SG_REL_ VIS2_LS SG_ 2151505920 ACCSettingType 1;
BA_REL_ "GenSigSuprvResp" BU_SG_REL_ BCM_LS SG_ 2151505920 ACCSettingType 1;
BA_REL_ "GenSigSuprvResp" BU_SG_REL_ BCM_LS SG_ 2151505920 TrlrBrkDsplyAct 1;
BA_REL_ "GenSigSuprvResp" BU_SG_REL_ ISRVM_LS SG_ 2154496000 TargaTopState 1;
BA_REL_ "GenSigSuprvResp" BU_SG_REL_ CSM_LS SG_ 2154496000 TargaTopState 1;
BA_REL_ "GenSigSuprvResp" BU_SG_REL_ RadioHead_LS SG_ 2154496000 TargaTopState 1;
BA_REL_ "GenSigSuprvResp" BU_SG_REL_ RadioHead_LS SG_ 2154496000 TargaTopState 1;
BA_REL_ "GenSigSuprvResp" BU_SG_REL_ IPC_LS SG_ 2155208704 SftTpPlsDnWrngIndOn 1;
BA_REL_ "GenSigSuprvResp" BU_SG_REL_ IPC_LS SG_ 2155208704 SftTpPlsDnSrtdIndOn 1;
BA_REL_ "GenSigSuprvResp" BU_SG_REL_ LCM_LS SG_ 2155208704 FldngTpSt 1;
BA_REL_ "GenSigSuprvResp" BU_SG_REL_ ISRVM_LS SG_ 2155208704 FldngTpSt 1;
BA_REL_ "GenSigSuprvResp" BU_SG_REL_ IPC_LS SG_ 2155208704 FldngTpSt 1;
BA_REL_ "GenSigSuprvResp" BU_SG_REL_ V2V_LS SG_ 2155208704 ClsTrnkLidIO 1;
BA_REL_ "GenSigVBitResp" BU_SG_REL_ IPC_LS SG_ 2153390080 RrClosOpenSwAct_2D1 1;
BA_REL_ "GenSigSuprvResp" BU_SG_REL_ IPC_LS SG_ 2153390080 RrClosOpenSwAct_2D1 1;
BA_REL_ "GenSigSuprvResp" BU_SG_REL_ FCM_LS SG_ 2155175936 AdptCrsLKALDWSwAct 1;
BA_REL_ "GenSigSuprvResp" BU_SG_REL_ CSM_LS SG_ 2156806144 CellNtwrkDtTmAvl 1;
BA_REL_ "GenSigSuprvResp" BU_SG_REL_ RadioHead_LS SG_ 2156806144 CellNtwrkDtTmAvl 1;
BA_REL_ "GenSigSuprvResp" BU_SG_REL_ LCM_LS SG_ 2154078208 RRWndPosStat 1;
BA_REL_ "GenSigSuprvResp" BU_SG_REL_ PTM_LS SG_ 2154078208 RRWndPosStat 1;
BA_REL_ "GenSigSuprvResp" BU_SG_REL_ LCM_LS SG_ 2154078208 PsWndPosStat 1;
BA_REL_ "GenSigSuprvResp" BU_SG_REL_ PTM_LS SG_ 2154078208 PsWndPosStat 1;
BA_REL_ "GenSigSuprvResp" BU_SG_REL_ LCM_LS SG_ 2154078208 LRWndPosStat 1;
BA_REL_ "GenSigSuprvResp" BU_SG_REL_ PTM_LS SG_ 2154078208 LRWndPosStat 1;
BA_REL_ "GenSigSuprvResp" BU_SG_REL_ LCM_LS SG_ 2154078208 DrvWndPosStat 1;
BA_REL_ "GenSigSuprvResp" BU_SG_REL_ PTM_LS SG_ 2154078208 DrvWndPosStat 1;
BA_REL_ "GenSigSuprvResp" BU_SG_REL_ VKM_LS SG_ 2150006784 SysPwrMdPshbtnAct 1;
BA_REL_ "GenSigSuprvResp" BU_SG_REL_ BCM_LS SG_ 2150006784 SysPwrMdPshbtnAct 1;
BA_REL_ "GenSigSuprvResp" BU_SG_REL_ FCM_LS SG_ 2155216896 DgtlMapPstdSpdLimAsrd 1;
BA_REL_ "GenSigSuprvResp" BU_SG_REL_ VIS2_LS SG_ 2155216896 DgtlMapPstdSpdLimAsrd 1;
BA_REL_ "GenSigSuprvResp" BU_SG_REL_ BCM_LS SG_ 2155216896 ISA2CCC_ScndCdChr 1;
BA_REL_ "GenSigSuprvResp" BU_SG_REL_ BCM_LS SG_ 2155216896 ISA2CCC_FrstCdChr 1;
BA_REL_ "GenSigSuprvResp" BU_SG_REL_ BCM_LS SG_ 2155216896 SpdLmtUnits 1;
BA_REL_ "GenSigSuprvResp" BU_SG_REL_ EOCM_F_LS SG_ 2155216896 RdSpdCatType 1;
BA_REL_ "GenSigSuprvResp" BU_SG_REL_ EOCM_F_LS SG_ 2155216896 FncRdClass 1;
BA_REL_ "GenSigSuprvResp" BU_SG_REL_ EOCM_F_LS SG_ 2155216896 BldUpArDet 1;
BA_REL_ "GenSigSuprvResp" BU_SG_REL_ EOCM_F_LS SG_ 2155216896 MpDataAvlbl 1;
BA_REL_ "GenSigSuprvResp" BU_SG_REL_ TCP_LS SG_ 2156216320 TxtTelephoneDevPr 1;
BA_REL_ "GenSigSuprvResp" BU_SG_REL_ ONSTAR_LS SG_ 2156216320 TxtTelephoneDevPr 1;
VAL_ 2158034944 VidSrcCompFormatER 8 "ATSC" 7 "DMB" 6 "DTMB" 5 "ISBD-T" 4 "DVB-T" 3 "SECAM" 2 "PAL" 1 "NTSC" ;
VAL_ 2158034944 CurntTVStnServc 0 "No Data" 1 "General Subscription" 2 "Pay per use" 3 "Promotion" 4 "Unsubscribed" 5 "Other" ;
VAL_ 2158034944 CurntTVStnQual 0 "Insufficient Signal" 1 "Sufficient Signal" ;
VAL_ 2158034944 VidSrcType 3 "Auxiliary Device" 2 "Rear Camera" 1 "Television" ;
VAL_ 2158034944 VidSrcStatCode 4 "Producing Blank" 3 "Producing Video" 2 "Video Not Available" 1 "Video Available" 0 "Device Present" ;
VAL_ 2158034944 TVTunerPres 1 "true" 0 "false" ;
VAL_ 2158034944 RmtRcvrTunStat 1 "Tuning" 0 "Tuned" ;
VAL_ 2158034944 RemRcvrSrcInpStat 3 "Auxiliary Jack 2" 2 "Auxiliary Jack 1" 1 "Television" 0 "No Action" ;
VAL_ 2158034944 RmtRecvtDataTyp 7 "Unknown" 3 "Video" 2 "Data" 1 "Audio" 0 "No Update" ;
VAL_ 2158034944 RmtRcvrCmndStat 3 "Out of Range" 2 "Not Supported" 1 "Valid Command" 0 "No Update" ;
VAL_ 2156838912 WSR_WiFiAssnStat 0 "No Action" 1 "Available" 2 "Service Set Identifier Request" 3 "Passphrase Request" 4 "Security Type Request" 5 "Encryption Request" 6 "All Request" ;
VAL_ 2156822528 WAPD_EncrptnType 0 "Open" 1 "AES (Advanced Encryption Standard)" 2 "TKIP (Temporal Key Integrity Protocol)" 3 "AES or TKIP" ;
VAL_ 2156822528 WAPD_SecurityType 3 "WPA2 (WiFi Protected Access 2)" 4 "IEEE802.1X (Institute of Electrical and Electronics Engineers)" 0 "Open" 1 "WEP (Wired Equivalent Privacy)" 2 "WPA (WiFi Protected Access)" ;
VAL_ 2156822528 WAPD_IHUWiFiEnStat 0 "Disabled" 1 "Enabled" ;
VAL_ 2151948288 RunBrdOpMdCstStReq 7 "Unused and Reserved 4" 6 "Unused and Reserved 3" 5 "Unused and Reserved 2" 4 "Unused and Reserved 1" 3 "Extended" 2 "On" 1 "Off" 0 "No Action" ;
VAL_ 2151948288 DrvDrowDetCstStRq 0 "No Action" 1 "Off" 2 "On" 3 "Reserved1" 4 "Reserved2" 5 "Reserved3" 6 "Reserved4" 7 "Reserved5" ;
VAL_ 2158002176 SrvcPrvdr 2 "Sirius" 1 "XM (company name)" 0 "Not Available" ;
VAL_ 2158002176 CurntStnServc 5 "Other" 4 "Unsubscribed" 3 "Promotion" 2 "Pay per Use" 1 "General Subscription" 0 "No Data" ;
VAL_ 2149728256 PrtyChrgActIO 1 "true" 0 "false" ;
VAL_ 2149728256 PrtyChrgAct 1 "true" 0 "false" ;
VAL_ 2149728256 EngAstHtPlgInCsStAvl 1 "true" 0 "false" ;
VAL_ 2149728256 EngAstHtPlgInCsCrStVl 0 "No Action" 1 "Off" 2 "On" ;
VAL_ 2149728256 EngAstHtCsStAvl 1 "true" 0 "false" ;
VAL_ 2149728256 EngAstHtCsCrStVal 3 "Off" 0 "No Action" 1 "On" 2 "Deferred" ;
VAL_ 2149728256 HghVltgPropState 0 "Generator Available" 1 "Generator Unavailable and Electric Propulsion OK" 2 "Generator Unavailable and Electric Propulsion Low" 3 "Generator Unavailable and No Electric Propulsion" ;
VAL_ 2149728256 HVChrgPwrLvl 0 "Unavailable" 1 "AC Level1" 2 "AC Level2" 3 "DC" ;
VAL_ 2149728256 ChrgPrtDrStat 0 "Inactive" 1 "Open Park" 2 "Open Moving" 3 "Fault" ;
VAL_ 2149728256 ChgCdTfAlCzStAvbl 1 "true" 0 "false" ;
VAL_ 2149728256 ChgCdTfAlCzCrStVal 0 "No Action" 1 "Off" 2 "On" 3 "Reserved 1" 4 "Reserved 2" 5 "Reserved 3" 6 "Reserved 4" 7 "Reserved 5" ;
VAL_ 2149728256 ChrgSysTrnsShftLckRq 1 "true" 0 "false" ;
VAL_ 2149728256 ChgPwLsAlCzStAvbl 1 "true" 0 "false" ;
VAL_ 2149728256 ChgPwLsAlCzCrStVal 0 "No Action" 1 "Off" 2 "On" 3 "Reserved 1" 4 "Reserved 2" 5 "Reserved 3" 6 "Reserved 4" 7 "Reserved 5" ;
VAL_ 2149728256 ChgSysAudInCsStAvl 1 "true" 0 "false" ;
VAL_ 2149728256 ChgSyAudInCsCrStVa 0 "No Action" 1 "Off" 2 "On" ;
VAL_ 2150023168 OffBrdVehImmbNot 0 "No Action" 1 "Immobilization State 1" 2 "Immobilization State 2" ;
VAL_ 2150023168 HVInvRatVltV 1 "Invalid" 0 "Valid" ;
VAL_ 2150023168 HybChrgMdStat 3 "Unused and reserved 2" 2 "Unused and reserved 1" 1 "Charge Sustaining" 0 "Charge Depleting" ;
VAL_ 2153988096 PwrElecCoolLpTempM 0 "Don't Use Data" 1 "Use Data" ;
VAL_ 2153988096 PwrElecCoolLpTempV 1 "Invalid" 0 "Valid" ;
VAL_ 2155945984 VehStbEnhmntCurStRq 2 "On" 1 "Off" 0 "No Action" ;
VAL_ 2155945984 VehStbCmptvMdCurStRq 2 "On" 1 "Off" 0 "No Action" ;
VAL_ 2155945984 TCSysCurStReq 2 "On" 1 "Off" 0 "No Action" ;
VAL_ 2155945984 JmpStrtReq 1 "true" 0 "false" ;
VAL_ 2155585536 StBltTgtCSRq 0 "No Action" 1 "Low" 2 "Normal" 3 "Performance" 4 "Locked" ;
VAL_ 2155569152 SmPhRmFunCstStReq 7 "Unused and Reserved 5" 6 "Unused and Reserved 4" 5 "Unused and Reserved 3" 4 "Unused and Reserved 2" 3 "Unused and Reserved 1" 2 "On" 1 "Off" 0 "No Action" ;
VAL_ 2155569152 HLOCCstSetReq 3 "On Open Only" 2 "On" 1 "Off" 0 "No Action" ;
VAL_ 2155569152 IntDimSeldClrTypStReq 31 "Color Type 30" 30 "Color Type 29" 29 "Color Type 28" 28 "Color Type 27" 27 "Color Type 26" 26 "Color Type 25" 25 "Color Type 24" 24 "Color Type 23" 23 "Color Type 22" 22 "Color Type 21" 21 "Color Type 20" 20 "Color Type 19" 19 "Color Type 18" 18 "Color Type 17" 17 "Color Type 16" 16 "Color Type 15" 15 "Color Type 14" 14 "Color Type 13" 13 "Color Type 12" 12 "Color Type 11" 11 "Color Type 10" 10 "Color Type 9" 9 "Color Type 8" 8 "Color Type 7" 7 "Color Type 6" 6 "Color Type 5" 5 "Color Type 4" 4 "Color Type 3" 3 "Color Type 2" 2 "Color Type 1" 1 "Off" 0 "No Action" ;
VAL_ 2155569152 IntDimSeldAnmTypStReq 15 "Animation Type 14" 14 "Animation Type 13" 13 "Animation Type 12" 12 "Animation Type 11" 11 "Animation Type 10" 10 "Animation Type 9" 9 "Animation Type 8" 8 "Animation Type 7" 7 "Animation Type 6" 6 "Animation Type 5" 5 "Animation Type 4" 4 "Animation Type 3" 3 "Animation Type 2" 2 "Animation Type 1" 1 "Off" 0 "No Action" ;
VAL_ 2155569152 ExtHlStrAssCsStRq 2 "Standard Hold" 1 "Extended Hold" 0 "No Action" ;
VAL_ 2155569152 ColPrSysCustReq 4 "Alert and Brake and Steer" 0 "No Action" 1 "Off" 2 "Alert" 3 "Alert and Brake" ;
VAL_ 2155233280 InstnsFlEcnHybOvrdReq 7 "Unused and Reserved 3" 6 "Unused and Reserved 2" 5 "Unused and Reserved 1" 4 "EV" 3 "Auto Stop" 2 "Max Fuel Economy" 1 "Min Fuel Economy" 0 "No Action" ;
VAL_ 2155233280 NtrlGrWrngIO 1 "true" 0 "false" ;
VAL_ 2155233280 RtBsChrgCmplnTmPrfRsp 2 "Latest Possible" 1 "Earliest Possible" 0 "No Action" ;
VAL_ 2155233280 EngRnngDutoVehSpdIO 1 "true" 0 "false" ;
VAL_ 2155233280 ShftPrkIO_3B2 1 "true" 0 "false" ;
VAL_ 2155233280 FlDrOpenIndOn 1 "true" 0 "false" ;
VAL_ 2155233280 VehRefuelSt 7 "Unused and Reserved 4" 6 "Unused and Reserved 3" 5 "Unused and Reserved 2" 4 "Unused and Reserved 1" 3 "Close Fuel Door" 2 "Ready To Refuel" 1 "Wait To Refuel" 0 "Inactive" ;
VAL_ 2155233280 NtrlCstdwnCrtMdActvIO 1 "true" 0 "false" ;
VAL_ 2155233280 UtlChrgPopUpAct 1 "true" 0 "false" ;
VAL_ 2155233280 UtlChrgIntrfrIO 1 "true" 0 "false" ;
VAL_ 2152759296 PedWrnIndReq 3 "Reserved " 2 "Pedestrian alert" 1 "Pedestrian detected" 0 "None" ;
VAL_ 2152759296 FrtRdrFldIO 1 "true" 0 "false" ;
VAL_ 2152759296 FrtCmrFldIO 1 "true" 0 "false" ;
VAL_ 2152759296 FrtEOCMMdlFldIO 1 "true" 0 "false" ;
VAL_ 2152759296 FrtCmrBlckdIO 1 "true" 0 "false" ;
VAL_ 2152742912 ShrtRngRdrOffIO 1 "true" 0 "false" ;
VAL_ 2152742912 RrRdrFldIO 1 "true" 0 "false" ;
VAL_ 2152742912 RrRdrBlckdIO 1 "true" 0 "false" ;
VAL_ 2152742912 RrEOCMMdlFldIO 1 "true" 0 "false" ;
VAL_ 2150891520 RrStRmndrCstSetReq 2 "On" 1 "Off" 0 "No Action" ;
VAL_ 2150891520 DgtlMapPsgRstrctn 7 "Unknown Condition" 6 "Conditional When Snow" 5 "Conditional When Wet" 4 "Condtnl Tractors Allowed  Overtake" 3 "Condtnl Passenger Car With Trailer" 2 "LED Signs" 1 "General No Overtake" 0 "No Passing Restrictions" ;
VAL_ 2150891520 DgtlMapCndlSpdLmt 31 "Not Available" 30 "Unlimited" 29 "160 kmh_mph" 28 "150 kmh_mph" 27 "140 kmh_mph" 26 "130 kmh_mph" 25 "120 kmh_mph" 24 "115 kmh_mph" 23 "110 kmh_mph" 22 "105 kmh_mph" 21 "100 kmh_mph" 20 "95 kmh_mph" 19 "90 kmh_mph" 18 "85 kmh_mph" 17 "80 kmh_mph" 16 "75 kmh_mph" 15 "70 kmh_mph" 14 "65 kmh_mph" 13 "60 kmh_mph" 12 "55 kmh_mph" 11 "50 kmh_mph" 10 "45 kmh_mph" 9 "40 kmh_mph" 8 "35 kmh_mph" 7 "30 kmh_mph" 6 "25 kmh_mph" 5 "20 kmh_mph" 4 "15 kmh_mph" 3 "10 kmh_mph" 2 "7 kmh_mph" 1 "Less Than Or Equal To 5 km/h [mph]" 0 "Unknown" ;
VAL_ 2150891520 DgtlMapCndlSpdLmtTyp 5 "Condtnl Speed Limit Only By Rain" 4 "Condtnl Speed Limit By Time Of Day" 3 "Conditional Speed Limit Only By Day" 2 "Condtnl Speed Limit Only By Night" 1 "Conditional Speed Limit Only By Fog" 0 "Condtnl Speed Limit Lane Dependent" 7 "Unknown Conditional Speed Limit" 6 "Condtnl Speed Limit Only By Snow" ;
VAL_ 2150891520 DgtlMapEffSpdLmt 0 "Unknown" 1 "<= 5 km/h [mph]" 2 "7 km/h [mph]" 3 "10 km/h [mph]" 4 "15 km/h [mph]" 5 "20 km/h [mph]" 6 "25 km/h [mph]" 7 "30 km/h [mph]" 8 "35 km/h [mph]" 9 "40 km/h [mph]" 10 "45 km/h [mph]" 11 "50 km/h [mph]" 12 "55 km/h [mph]" 13 "60 km/h [mph]" 14 "65 km/h [mph]" 15 "70 km/h [mph]" 16 "75 km/h [mph]" 17 "80 km/h [mph]" 18 "85 km/h [mph]" 19 "90 km/h [mph]" 20 "95 km/h [mph]" 21 "100 km/h [mph]" 22 "105 km/h [mph]" 23 "110 km/h [mph]" 24 "115 km/h [mph]" 25 "120 km/h [mph]" 26 "130 km/h [mph]" 27 "140 km/h [mph]" 28 "150 km/h [mph]" 29 "160 km/h [mph]" 30 "Unlimited" 31 "Not Available" ;
VAL_ 2150891520 DgtlMapEffSpdLmtTyp 0 "Implicit" 1 "Explicit on Traffic Sign" 2 "Explicit Only by Night" 3 "Explicit Only by Day" 4 "Explicit Time of Day" 5 "Explicit Only by Rain" 6 "Explicit Only by Snow" 7 "Unknown" ;
VAL_ 2150891520 DgtlMapSpdCat 0 ">130 km/h" 1 "101-130 km/h" 2 "91-100 km/h" 3 "71-90  km/h" 4 "51-70 km/h" 5 "31-50 km/h" 6 "11-30 km/h" 7 "<11 km/h" ;
VAL_ 2150891520 DgtlMapVerQtr 0 "Quarter 1" 1 "Quarter 2" 2 "Quarter 3" 3 "Quarter 4" ;
VAL_ 2150891520 DgtlMapVerYr 0 "2000" 1 "2001" 2 "2002" 3 "2003" 4 "2004" 5 "2005" 6 "2006" 7 "2007" 8 "2008" 9 "2009" 10 "2010" 11 "2011" 12 "2012" 13 "2013" 14 "2014" 15 "2015" 16 "2016" 17 "2017" 18 "2018" 19 "2019" 20 "2020" 21 "2021" 22 "2022" 23 "2023" 24 "2024" 25 "2025" 26 "2026" 27 "2027" 28 "2028" 29 "2029" 30 "2030" 31 "2031" 32 "2032" 33 "2033" 34 "2034" 35 "2035" 36 "2036" 37 "2037" 38 "2038" 39 "2039" 40 "2040" 41 "2041" 42 "2042" 43 "2043" 44 "2044" 45 "2045" 46 "2046" 47 "2047" 48 "2048" 49 "2049" 50 "2050" 51 "2051" 52 "2052" 53 "2053" 54 "2054" 55 "2055" 56 "2056" 57 "2057" 58 "2058" 59 "2059" 60 "2060" 61 "2061" 62 "2062" 63 "N/A" ;
VAL_ 2150891520 DgtlMapDrvngSd 0 "Driving Side Left" 1 "Driving Side Right" ;
VAL_ 2150891520 FwdClnAlrtCustStngReq 0 "No Action" 1 "Off" 2 "On" ;
VAL_ 2150891520 GNCustStngReq 0 "No Action" 1 "Off" 2 "On" ;
VAL_ 2151751680 HptcStVbnStat 0 "Normal Operation" 1 "Unknown" 2 "Failed" ;
VAL_ 2151751680 HptcStFldIO 1 "true" 0 "false" ;
VAL_ 2151751680 CrshAlrtDrvrSlctdType 0 "Chime" 1 "Seat" ;
VAL_ 2151751680 CrshAlrtStPrsnt 1 "true" 0 "false" ;
VAL_ 2155536384 RevClnMtgnBrkReqAct 1 "true" 0 "false" ;
VAL_ 2155536384 TnDrvRIMOffUnbIO 1 "true" 0 "false" ;
VAL_ 2155536384 RVBUnblIO 1 "true" 0 "false" ;
VAL_ 2155536384 RVBFldIO 1 "true" 0 "false" ;
VAL_ 2155536384 RVBEnbldIO 1 "true" 0 "false" ;
VAL_ 2155536384 RVBDsbldIO 1 "true" 0 "false" ;
VAL_ 2151481344 HdUpDsplyUnblIO 1 "true" 0 "false" ;
VAL_ 2151481344 FSRACCFrstRsmPrssIO 1 "true" 0 "false" ;
VAL_ 2151481344 FrtRdrBlckdIO 1 "true" 0 "false" ;
VAL_ 2151481344 ShtToPrkBfExtngVehIO 1 "true" 0 "false" ;
VAL_ 2151481344 AutoBrkRlsIO 1 "true" 0 "false" ;
VAL_ 2151415808 FrPedDetCsStAvl 1 "true" 0 "false" ;
VAL_ 2151415808 FrPedDetCsCrStVal 3 "Alert and Brake" 2 "Alert" 1 "Off" 0 "No Action" ;
VAL_ 2151350272 APAIconDispRq 7 "Unused & Reserved" 6 "Unused & Reserved" 5 "Unused & Reserved" 4 "Complete" 3 "Stop" 2 "Reverse" 1 "Forward" 0 "No Icon" ;
VAL_ 2151522304 BrkPdLfSysDrvrRq 4 "Reset Rear" 3 "Reset Front" 2 "Enable" 1 "Disable" 0 "No Action" ;
VAL_ 2151522304 LnchCtrlRelLnLockReqd 1 "true" 0 "false" ;
VAL_ 2151522304 TCSTmpDsblReqConf 2 "Yes" 1 "No" 0 "No Action" ;
VAL_ 2151522304 ElEngyEconAvgRstRq 1 "true" 0 "false" ;
VAL_ 2151522304 FuelFltLfRstRqd 1 "true" 0 "false" ;
VAL_ 2150629376 CVSysFlrIO 1 "true" 0 "false" ;
VAL_ 2155929600 DslExhFldDiagWrnIdRq 0 "No Indication" 1 "Warning Level 1" 2 "Warning Level 2" 3 "Warning Level 3" 4 "Warning Level 4" 5 "Warning Level 5" 6 "Warning Level 6" 7 "Warning Level 7" ;
VAL_ 2155929600 DslExFldTpWrngIndRq 15 "Warning Level 15" 14 "Warning Level 14" 13 "Warning Level 13" 12 "Warning Level 12" 11 "Warning Level 11" 10 "Warning Level 10" 9 "Warning Level 9" 8 "Warning Level 8" 7 "Warning Level 7" 6 "Warning Level 6" 5 "Warning Level 5" 4 "Warning Level 4" 3 "Warning Level 3" 2 "Warning Level 2" 1 "Warning Level 1" 0 "No Indication" ;
VAL_ 2155929600 DslExhFldQlyWrngIReq 15 "Warning Level 15" 14 "Warning Level 14" 13 "Warning Level 13" 12 "Warning Level 12" 11 "Warning Level 11" 10 "Warning Level 10" 9 "Warning Level 9" 8 "Warning Level 8" 7 "Warning Level 7" 6 "Warning Level 6" 5 "Warning Level 5" 4 "Warning Level 4" 3 "Warning Level 3" 2 "Warning Level 2" 1 "Warning Level 1" 0 "No Indication" ;
VAL_ 2155929600 DslExhFldWrngIdRqER 15 "Warning Level 15" 14 "Warning Level 14" 13 "Warning Level 13" 12 "Warning Level 12" 11 "Warning Level 11" 10 "Warning Level 10" 9 "Warning Level 9" 8 "Warning Level 8" 7 "Warning Level 7" 6 "Warning Level 6" 5 "Warning Level 5" 4 "Warning Level 4" 3 "Warning Level 3" 2 "Warning Level 2" 1 "Warning Level 1" 0 "No Indication" ;
VAL_ 2155929600 DslExFldCnWrngIndRq 15 "Warning Level 15" 14 "Warning Level 14" 13 "Warning Level 13" 12 "Warning Level 12" 11 "Warning Level 11" 10 "Warning Level 10" 9 "Warning Level 9" 8 "Warning Level 8" 7 "Warning Level 7" 6 "Warning Level 6" 5 "Warning Level 5" 4 "Warning Level 4" 3 "Warning Level 3" 2 "Warning Level 2" 1 "Warning Level 1" 0 "No Indication" ;
VAL_ 2155929600 DslExNxEmWrngIndRq 15 "Warning Level 15" 14 "Warning Level 14" 13 "Warning Level 13" 12 "Warning Level 12" 11 "Warning Level 11" 10 "Warning Level 10" 9 "Warning Level 9" 8 "Warning Level 8" 7 "Warning Level 7" 6 "Warning Level 6" 5 "Warning Level 5" 4 "Warning Level 4" 3 "Warning Level 3" 2 "Warning Level 2" 1 "Warning Level 1" 0 "No Indication" ;
VAL_ 2154741760 RSAPrsnt 1 "true" 0 "false" ;
VAL_ 2154807296 ESCMHiEleclLdReqAct 1 "true" 0 "false" ;
VAL_ 2154807296 TnDrvStBltShftIntrlkCsStAvl 1 "true" 0 "false" ;
VAL_ 2154807296 TnDrvStBltShftIntrlkCrStVal 2 "On" 1 "Off" 0 "No Action" ;
VAL_ 2154807296 StBltShftIntrlkCsStAvl 1 "true" 0 "false" ;
VAL_ 2154807296 StBltShftIntrlkCsCrStVal 2 "On" 1 "Off" 0 "No Action" ;
VAL_ 2154807296 EASSI_UnsdRsrvd2 1 "true" 0 "false" ;
VAL_ 2154807296 EASSI_StlDetd 1 "true" 0 "false" ;
VAL_ 2154807296 EASSI_TrqDetd 1 "true" 0 "false" ;
VAL_ 2154807296 EASSI_FuelReqOn 1 "true" 0 "false" ;
VAL_ 2154807296 EASSI_StrtTyp 7 "Type G" 6 "Type F" 5 "Type E" 4 "Type D" 3 "Type C" 2 "Type B" 1 "Type A" 0 "No Start" ;
VAL_ 2154807296 EASSI_StrtStpSt 3 "Engine Stopping" 2 "Engine Starting" 1 "Engine Running" 0 "Engine Off" ;
VAL_ 2154807296 EASSI_TorqDetdIndet 1 "true" 0 "false" ;
VAL_ 2154807296 EngAutoStpNotProb 1 "true" 0 "false" ;
VAL_ 2154807296 AFLMnu3CstStAvl 1 "true" 0 "false" ;
VAL_ 2154807296 AFLMnu2CstStAvl 1 "true" 0 "false" ;
VAL_ 2154807296 AFLGPSMnu2CstStAvl 1 "true" 0 "false" ;
VAL_ 2154807296 AFLGPSCstStAvl 1 "true" 0 "false" ;
VAL_ 2154807296 AFLGPSCstCrStVal 0 "No Value" 1 "Corner And Curve Lighting Only" 2 "Intelligent Light Distribution" 3 "GPS Assistance" 4 "Reserved1" 5 "Reserved2" 6 "Reserved3" 7 "Off" ;
VAL_ 2154807296 AFLCstStAvl 1 "true" 0 "false" ;
VAL_ 2154807296 AFLCstCrStVal 0 "No Value" 1 "Corner And Curve Lighting Only" 2 "Intelligent Light Distribution" 3 "Reserved1" 4 "Reserved2" 5 "Reserved3" 6 "Reserved4" 7 "Off" ;
VAL_ 2151079936 PDIMPrsnt 1 "true" 0 "false" ;
VAL_ 2155364352 CstmrUsblSOCV 1 "Invalid" 0 "Valid" ;
VAL_ 2155364352 BattCntrlPrcssrVDA 1 "VirtualDeviceAvailable" 0 "VirtualDeviceUnavailable" ;
VAL_ 2155364352 JmpStrtStat 0 "Inactive" 1 "In Progress" 2 "Complete" 3 "Power Mode" 4 "Disabled" ;
VAL_ 2155364352 SvcHybridSysIO 1 "true" 0 "false" ;
VAL_ 2155364352 HybMdDisp 15 "Engine Charging Battery While Idle" 14 "Engine Charging Battery Moving" 13 "Engine Power Load Sharing" 12 "Battery Power Load Sharing" 11 "Undetermined" 10 "Charging With Engine On" 9 "Charging With Engine Off" 8 "Hybrid Power 4WD" 7 "Hybrid Power 2WD" 6 "Engine Power 4WD" 5 "Engine Power 2WD" 4 "Battery Power 4WD" 3 "Battery Power 2WD" 2 "Auto Stop" 1 "Engine Idle" 0 "Default / Accessory" ;
VAL_ 2154979328 FrntStVoltBstModReq 1 "true" 0 "false" ;
VAL_ 2155282432 RrStVoltBstModReq 1 "true" 0 "false" ;
VAL_ 2151505920 PTExPrtclFltManRgnDispPrsnt 1 "true" 0 "false" ;
VAL_ 2151505920 Trp2OdomtrV 1 "Invalid" 0 "Valid" ;
VAL_ 2151505920 Trp1OdomtrV 1 "Invalid" 0 "Valid" ;
VAL_ 2151505920 PTExPrtclFltManRgnRqd 1 "true" 0 "false" ;
VAL_ 2151505920 AutoMdSpdLmtCnfrmd 1 "true" 0 "false" ;
VAL_ 2151505920 ACCSettingType 0 "Manual" 1 "Auto" ;
VAL_ 2151505920 TrlrBrkDsplyAct 1 "true" 0 "false" ;
VAL_ 2151505920 SpdCurvAdvSysEnbld 1 "true" 0 "false" ;
VAL_ 2155896832 FuelAlcoholCompV 1 "Invalid" 0 "Valid" ;
VAL_ 2155896832 FuelAlchlCompAdptnPrg 1 "true" 0 "false" ;
VAL_ 2155896832 FuelMdStat 3 "Alternative Fuel Cut-off Active" 2 "Liquified Petroleum Gas Mode" 1 "Natural Gas Mode" 0 "Gasoline Mode" ;
VAL_ 2155896832 FlLvlTank2PctV 1 "Invalid" 0 "Valid" ;
VAL_ 2155896832 AltFuelPHeatAct 1 "true" 0 "false" ;
VAL_ 2155896832 AltFuelMdReqDndIO 1 "true" 0 "false" ;
VAL_ 2155896832 AltFuelLvlLo 1 "true" 0 "false" ;
VAL_ 2155896832 AltFuelAccWrnngAct 1 "true" 0 "false" ;
VAL_ 2155552768 PsvEntCmftWndRq 3 "Reserved" 2 "Comfort Open" 1 "Comfort Close" 0 "No Action" ;
VAL_ 2154496000 ShftrUnlkdBrkToShftIO 1 "true" 0 "false" ;
VAL_ 2154496000 ShftrLkdBklDrvStbltIO 1 "true" 0 "false" ;
VAL_ 2154496000 ShftrLkdBklPsnStbltIO 1 "true" 0 "false" ;
VAL_ 2154496000 TargaTopStateV 1 "Invalid" 0 "Valid" ;
VAL_ 2154496000 TargaTopState 0 "Open" 1 "Closed" ;
VAL_ 2154496000 CmpSftTopMotBfrOpTrnkIO 1 "true" 0 "false" ;
VAL_ 2155208704 SftTpPlsDnWrngIndOn 1 "true" 0 "false" ;
VAL_ 2155208704 SftTpPlsDnSrtdIndOn 1 "true" 0 "false" ;
VAL_ 2155208704 VltSwAtvIndOn 1 "true" 0 "false" ;
VAL_ 2155208704 SftTpVltLwIO 1 "true" 0 "false" ;
VAL_ 2155208704 SftTpVehOvSpdIndOn 1 "true" 0 "false" ;
VAL_ 2155208704 SftTpTneuCvrIO 1 "true" 0 "false" ;
VAL_ 2155208704 SftTpTmpLwIO 1 "true" 0 "false" ;
VAL_ 2155208704 SftTpStrIO 1 "true" 0 "false" ;
VAL_ 2155208704 SftTpRmCrgCrrIO 1 "true" 0 "false" ;
VAL_ 2155208704 SftTpMnlLtchIndOn 1 "true" 0 "false" ;
VAL_ 2155208704 SftTpMchnOvhtIO 1 "true" 0 "false" ;
VAL_ 2155208704 SftTpLtcIO 1 "true" 0 "false" ;
VAL_ 2155208704 SftTpFlrIO 1 "true" 0 "false" ;
VAL_ 2155208704 SftTpAbvWrngSpdIndOn 1 "true" 0 "false" ;
VAL_ 2155208704 FldngTpSt 4 "Not Secure And Not Moving " 3 "Closing" 2 "Opening" 1 "Fully Closed" 0 "Fully Opened" ;
VAL_ 2155208704 ClsTrnkLidIO 1 "true" 0 "false" ;
VAL_ 2155208704 CkSoftTpIO 1 "true" 0 "false" ;
VAL_ 2155208704 SftTpTrnLmpsRqd 1 "true" 0 "false" ;
VAL_ 2155208704 FldngTpWndCmftRq 0 "No Action" 1 "Comfort Close" 2 "Comfort Open" 3 "Reserved" ;
VAL_ 2155208704 FTUpdWndPsLmtEnbld 1 "true" 0 "false" ;
VAL_ 2153390080 RrClosOpenSwAct_2D1V 1 "Invalid" 0 "Valid" ;
VAL_ 2153390080 RrClosOpenSwAct_2D1 1 "true" 0 "false" ;
VAL_ 2155175936 AdptCrsLKALDWSwAct 1 "true" 0 "false" ;
VAL_ 2155175936 AdptCrsGapSwAct 2 "Increase Gap" 1 "Decrease Gap" 0 "No Activation" ;
VAL_ 2156806144 CellNtwrkDtTmAvl 1 "true" 0 "false" ;
VAL_ 2156806144 SecCmpstdValV 1 "Invalid" 0 "Valid" ;
VAL_ 2156806144 MinsCmpstdValV 1 "Invalid" 0 "Valid" ;
VAL_ 2156806144 HrsCmpstdValV 1 "Invalid" 0 "Valid" ;
VAL_ 2156806144 CldrMthCmpstdVal 0 "Unknown" 1 "January" 2 "February" 3 "March" 4 "April" 5 "May" 6 "June" 7 "July" 8 "August" 9 "September" 10 "October" 11 "November" 12 "December" ;
VAL_ 2154078208 RRWndPosStat 6 "Fully Opened" 5 "Open More Than C" 4 "Position C" 3 "Posistion B" 2 "Posistion A" 1 "Open Less Than A" 0 "Fully Closed" ;
VAL_ 2154078208 PsWndPosStat 6 "Fully Opened" 5 "Open More Than C" 4 "Position C" 3 "Posistion B" 2 "Posistion A" 1 "Open Less Than A" 0 "Fully Closed" ;
VAL_ 2154078208 LRWndPosStat 6 "Fully Opened" 5 "Open More Than C" 4 "Position C" 3 "Posistion B" 2 "Posistion A" 1 "Open Less Than A" 0 "Fully Closed" ;
VAL_ 2154078208 DrvWndPosStat 6 "Fully Opened" 5 "Open More Than C" 4 "Position C" 3 "Posistion B" 2 "Posistion A" 1 "Open Less Than A" 0 "Fully Closed" ;
VAL_ 2159042560 ODDI_InvldData 1 "true" 0 "false" ;
VAL_ 2159042560 ODDI_DataType 21 "Bitmap" 20 "DecimalShort" 19 "HoursOfDay" 18 "Character" 17 "Fuel Consumption Inverted" 16 "Fuel Consumption" 15 "Pressure" 14 "Temperature" 13 "Volume" 12 "DistanceShort" 11 "DistanceLong" 10 "BitmapId" 9 "TextId" 8 "Pictogram" 7 "List " 6 "Date" 5 "Time " 4 "Decimal" 3 "EnumerationValue" 2 "Integer" 1 "String" 0 "Speed" ;
VAL_ 2150006784 SysPwrMdPshbtnActV 1 "Invalid" 0 "Valid" ;
VAL_ 2150006784 SysPwrMdPshbtnAct 1 "true" 0 "false" ;
VAL_ 2150006784 PEPSRunCrnkRlyDctd 1 "true" 0 "false" ;
VAL_ 2155216896 DgtlMapPstdSpdLimAsrd 1 "true" 0 "false" ;
VAL_ 2155216896 SpdLmtPstdSpdM 0 "Don't Use Data" 1 "Use Data" ;
VAL_ 2155216896 ISA2CCC_ScndCdChr 0 "Unknown" 1 "A" 2 "B" 3 "C" 4 "D" 5 "E" 6 "F" 7 "G" 8 "H" 9 "I" 10 "J" 11 "K" 12 "L" 13 "M" 14 "N" 15 "O" 16 "P" 17 "Q" 18 "R" 19 "S" 20 "T" 21 "U" 22 "V" 23 "W" 24 "X" 25 "Y" 26 "Z" ;
VAL_ 2155216896 ISA2CCC_FrstCdChr 0 "Unknown" 1 "A" 2 "B" 3 "C" 4 "D" 5 "E" 6 "F" 7 "G" 8 "H" 9 "I" 10 "J" 11 "K" 12 "L" 13 "M" 14 "N" 15 "O" 16 "P" 17 "Q" 18 "R" 19 "S" 20 "T" 21 "U" 22 "V" 23 "W" 24 "X" 25 "Y" 26 "Z" ;
VAL_ 2155216896 CurvAdvInd 3 "Winding Road" 2 "Right Turn" 1 "Left Turn" 0 "No Advisory" ;
VAL_ 2155216896 SpdLmtUnits 1 "km/h" 0 "mph" ;
VAL_ 2155216896 LnCat 3 "Four Or More Lanes" 2 "Two Or Three Lanes" 1 "One lane" 0 "no info available" ;
VAL_ 2155216896 RdSpdCatType 3 "all speed categories 0 - 50 km/h" 2 "all speed categories 51-80 km/h" 1 "all speed categories 81-130 km/h" 0 "all speed categories > 130 km/h" ;
VAL_ 2155216896 FncRdClass 7 "COLLECTOR" 6 "ALLEY" 5 "ARTERIAL" 4 "HIGHWAY" 3 "PED-MALL" 2 "FREEWAY" 1 "SFREEWAY" 0 "LOCAL (Residential Road)" ;
VAL_ 2155216896 SprtLnRd 1 "true" 0 "false" ;
VAL_ 2155216896 CntrldAccRd 1 "true" 0 "false" ;
VAL_ 2155216896 BldUpArDet 1 "true" 0 "false" ;
VAL_ 2155216896 MpDataAvlbl 1 "true" 0 "false" ;
VAL_ 2156216320 TxtTelephoneDevPr 1 "true" 0 "false" ;
VAL_ 2158813184 ODIIIPC_ODIInd56 1 "true" 0 "false" ;
VAL_ 2158813184 ODIIIPC_ODIInd55 1 "true" 0 "false" ;
VAL_ 2158813184 ODIIIPC_ODIInd54 1 "true" 0 "false" ;
VAL_ 2158813184 ODIIIPC_ODIInd53 1 "true" 0 "false" ;
VAL_ 2158813184 ODIIIPC_ODIInd52 1 "true" 0 "false" ;
VAL_ 2158813184 ODIIIPC_ODIInd51 1 "true" 0 "false" ;
VAL_ 2158813184 ODIIIPC_ODIInd50 1 "true" 0 "false" ;
VAL_ 2158813184 ODIIIPC_ODIInd49 1 "true" 0 "false" ;
VAL_ 2158813184 ODIIIPC_ODIInd48 1 "true" 0 "false" ;
VAL_ 2158813184 ODIIIPC_ODIInd47 1 "true" 0 "false" ;
VAL_ 2158813184 ODIIIPC_ODIInd46 1 "true" 0 "false" ;
VAL_ 2158813184 ODIIIPC_ODIInd45 1 "true" 0 "false" ;
VAL_ 2158813184 ODIIIPC_ODIInd44 1 "true" 0 "false" ;
VAL_ 2158813184 ODIIIPC_ODIInd43 1 "true" 0 "false" ;
VAL_ 2158813184 ODIIIPC_ODIInd42 1 "true" 0 "false" ;
VAL_ 2158813184 ODIIIPC_ODIInd41 1 "true" 0 "false" ;
VAL_ 2158813184 ODIIIPC_ODIInd40 1 "true" 0 "false" ;
VAL_ 2158813184 ODIIIPC_ODIInd39 1 "true" 0 "false" ;
VAL_ 2158813184 ODIIIPC_ODIInd38 1 "true" 0 "false" ;
VAL_ 2158813184 ODIIIPC_ODIInd9 1 "true" 0 "false" ;
VAL_ 2158813184 ODIIIPC_ODIInd8 1 "true" 0 "false" ;
VAL_ 2158813184 ODIIIPC_ODIInd7 1 "true" 0 "false" ;
VAL_ 2158813184 ODIIIPC_ODIInd6 1 "true" 0 "false" ;
VAL_ 2158813184 ODIIIPC_ODIInd5 1 "true" 0 "false" ;
VAL_ 2158813184 ODIIIPC_ODIInd4 1 "true" 0 "false" ;
VAL_ 2158813184 ODIIIPC_ODIInd3 1 "true" 0 "false" ;
VAL_ 2158813184 ODIIIPC_ODIInd37 1 "true" 0 "false" ;
VAL_ 2158813184 ODIIIPC_ODIInd36 1 "true" 0 "false" ;
VAL_ 2158813184 ODIIIPC_ODIInd35 1 "true" 0 "false" ;
VAL_ 2158813184 ODIIIPC_ODIInd34 1 "true" 0 "false" ;
VAL_ 2158813184 ODIIIPC_ODIInd33 1 "true" 0 "false" ;
VAL_ 2158813184 ODIIIPC_ODIInd32 1 "true" 0 "false" ;
VAL_ 2158813184 ODIIIPC_ODIInd31 1 "true" 0 "false" ;
VAL_ 2158813184 ODIIIPC_ODIInd30 1 "true" 0 "false" ;
VAL_ 2158813184 ODIIIPC_ODIInd29 1 "true" 0 "false" ;
VAL_ 2158813184 ODIIIPC_ODIInd28 1 "true" 0 "false" ;
VAL_ 2158813184 ODIIIPC_ODIInd27 1 "true" 0 "false" ;
VAL_ 2158813184 ODIIIPC_ODIInd26 1 "true" 0 "false" ;
VAL_ 2158813184 ODIIIPC_ODIInd25 1 "true" 0 "false" ;
VAL_ 2158813184 ODIIIPC_ODIInd24 1 "true" 0 "false" ;
VAL_ 2158813184 ODIIIPC_ODIInd23 1 "true" 0 "false" ;
VAL_ 2158813184 ODIIIPC_ODIInd22 1 "true" 0 "false" ;
VAL_ 2158813184 ODIIIPC_ODIInd21 1 "true" 0 "false" ;
VAL_ 2158813184 ODIIIPC_ODIInd20 1 "true" 0 "false" ;
VAL_ 2158813184 ODIIIPC_ODIInd19 1 "true" 0 "false" ;
VAL_ 2158813184 ODIIIPC_ODIInd18 1 "true" 0 "false" ;
VAL_ 2158813184 ODIIIPC_ODIInd17 1 "true" 0 "false" ;
VAL_ 2158813184 ODIIIPC_ODIInd16 1 "true" 0 "false" ;
VAL_ 2158813184 ODIIIPC_ODIInd15 1 "true" 0 "false" ;
VAL_ 2158813184 ODIIIPC_ODIInd14 1 "true" 0 "false" ;
VAL_ 2158813184 ODIIIPC_ODIInd13 1 "true" 0 "false" ;
VAL_ 2158813184 ODIIIPC_ODIInd12 1 "true" 0 "false" ;
VAL_ 2158813184 ODIIIPC_ODIInd11 1 "true" 0 "false" ;
VAL_ 2158813184 ODIIIPC_ODIInd10 1 "true" 0 "false" ;
VAL_ 2158813184 ODIIIPC_ODIInd2 1 "true" 0 "false" ;
VAL_ 2158813184 ODIIIPC_ODIInd1 1 "true" 0 "false" ;
SIG_GROUP_ 2156838912 WiFiStationResp 1 : WSR_WiFiStnMACAddr WSR_WiFiAssnStat;
SIG_GROUP_ 2156822528 WiFiAccsPntData 1 : WAPD_EncrptnType WAPD_SecurityType WAPD_IHUWiFiEnStat;
SIG_GROUP_ 2153988096 EngyUsgScr 1 : EUS_TtEngyUsgScrAvVal EUS_ITEngyUsgScrAvVal EUS_OTEngyUsgScrAvVal EUS_TrEngyUsgScrAvVal EUS_TcEngyUsgScrAvVal;
SIG_GROUP_ 2155929600 DslExFldWrngVSpdLmt 1 : DEFWVSL_S3SpdLmt DEFWVSL_S2SpdLmt DEFWVSL_S1SpdLmt;
SIG_GROUP_ 2154807296 EngAutoStrtStpInfo 1 : EASSI_UnsdRsrvd2 EASSI_StlDetd EASSI_TrqDetd EASSI_FuelReqOn EASSI_StrtTyp EASSI_StrtStpSt EASSI_TorqDetdIndet;
SIG_GROUP_ 2159058944 ODIEvntPkt_IPC 1 : ODIEI_MultiFrRetCh ODIEI_FUCID ODIEI_EvID;
SIG_GROUP_ 2159042560 ODIDynData_IPC 1 : ODDI_DataVal ODDI_DataId ODDI_FUCID ODDI_InvldData ODDI_DataType;
SIG_GROUP_ 2155216896 IntlStdAlph2CddCntryCd 1 : ISA2CCC_ScndCdChr ISA2CCC_FrstCdChr;
SIG_GROUP_ 2158813184 ODIInd_IPC 1 : ODIIIPC_ODIInd56 ODIIIPC_ODIInd55 ODIIIPC_ODIInd54 ODIIIPC_ODIInd53 ODIIIPC_ODIInd52 ODIIIPC_ODIInd51 ODIIIPC_ODIInd50 ODIIIPC_ODIInd49 ODIIIPC_ODIInd48 ODIIIPC_ODIInd47 ODIIIPC_ODIInd46 ODIIIPC_ODIInd45 ODIIIPC_ODIInd44 ODIIIPC_ODIInd43 ODIIIPC_ODIInd42 ODIIIPC_ODIInd41 ODIIIPC_ODIInd40 ODIIIPC_ODIInd39 ODIIIPC_ODIInd38 ODIIIPC_ODIInd9 ODIIIPC_ODIInd8 ODIIIPC_ODIInd7 ODIIIPC_ODIInd6 ODIIIPC_ODIInd5 ODIIIPC_ODIInd4 ODIIIPC_ODIInd3 ODIIIPC_ODIInd37 ODIIIPC_ODIInd36 ODIIIPC_ODIInd35 ODIIIPC_ODIInd34 ODIIIPC_ODIInd33 ODIIIPC_ODIInd32 ODIIIPC_ODIInd31 ODIIIPC_ODIInd30 ODIIIPC_ODIInd29 ODIIIPC_ODIInd28 ODIIIPC_ODIInd27 ODIIIPC_ODIInd26 ODIIIPC_ODIInd25 ODIIIPC_ODIInd24 ODIIIPC_ODIInd23 ODIIIPC_ODIInd22 ODIIIPC_ODIInd21 ODIIIPC_ODIInd20 ODIIIPC_ODIInd19 ODIIIPC_ODIInd18 ODIIIPC_ODIInd17 ODIIIPC_ODIInd16 ODIIIPC_ODIInd15 ODIIIPC_ODIInd14 ODIIIPC_ODIInd13 ODIIIPC_ODIInd12 ODIIIPC_ODIInd11 ODIIIPC_ODIInd10 ODIIIPC_ODIInd2 ODIIIPC_ODIInd1 ODIIIPC_FUCID;
